VERSION "HNNBNNNYNNNNNNNNNNNNNNNNNNNNNNNNNNNNNNNNNN/4/%%%/4/'%**4NNN///"

NS_ :

BS_:

BU_: Aero_LB AFS_MLB Airbag_B8 BCM1_B8 Gateway_B8 Getriebe_AL551_651_B8 Getriebe_AL551_Q5_Hybrid Getriebe_SL_LB Lift_MLB_LB LWR_MLB Magnetic_Ride_LB Motor_MLB_AU48_AU416_Diesel Motor_MLB_B8_Q5_Otto Motor_MLB_Q5_Hybrid Niveau_LB Airbag_D4 BMS_Hybrid Daempfer_MLB EPB_MLB ESP Gateway Getriebe_AL551_951_D4_C7 Getriebe_AL551_Hybrid_D4_C7 Getriebe_DL382_MLB Getriebe_DL501_MLB Getriebe_VL381_MLB LEH_Hybrid LWS_D4 Motor2_MLB_D4_C7 Motor_MLB_AU64_AU57_Diesel Motor_MLB_BY_Otto Motor_MLB_C7_PHEV Motor_MLB_D4_C7_Hybrid Motor_MLB_D4_C7_Otto QSP SAK SAK2 SCR_MLB SCU

BO_ 782 Motor_05: 8 Motor_MLB_AU64_AU57_Diesel
 SG_ Motor_05_CHK : 0|8@1+ (1,0) [0|255] ""  Gateway,Getriebe_AL551_951_D4_C7,Getriebe_AL551_Hybrid_D4_C7,Getriebe_DL382_MLB,Getriebe_DL501_MLB,Getriebe_VL381_MLB
 SG_ Motor_05_BZ : 8|4@1+ (1,0) [0|15] ""  Gateway,Getriebe_AL551_951_D4_C7,Getriebe_AL551_Hybrid_D4_C7,Getriebe_DL382_MLB,Getriebe_DL501_MLB,Getriebe_VL381_MLB
 SG_ MO_EKlKomLeiRed : 12|2@1+ (1,0) [0|3] ""  Gateway
 SG_ MO_Freig_Reku : 14|2@1+ (1,0) [0|3] ""  Gateway
 SG_ MO_Klima_Eingr : 16|2@1+ (1,0) [0|3] ""  Gateway
 SG_ MO_Status_Normalbetrieb_02 : 18|1@1+ (1,0) [0|1] ""  Gateway
 SG_ MO_Schaltbeeinfl_Leistungsbegr : 19|1@1+ (1,0) [0|1] ""  Gateway,Getriebe_AL551_951_D4_C7,Getriebe_AL551_Hybrid_D4_C7,Getriebe_DL382_MLB,Getriebe_DL501_MLB
 SG_ MO_Schaltbeeinfl_Partikelfilter : 20|1@1+ (1,0) [0|1] ""  Gateway,Getriebe_AL551_951_D4_C7,Getriebe_AL551_Hybrid_D4_C7,Getriebe_DL382_MLB,Getriebe_DL501_MLB
 SG_ MO_Prio_MIN_Wunschdrehzahl : 21|1@1+ (1,0) [0|1] ""  Gateway,Getriebe_AL551_951_D4_C7,Getriebe_AL551_Hybrid_D4_C7,Getriebe_DL382_MLB,Getriebe_DL501_MLB,Getriebe_VL381_MLB
 SG_ MO_Freig_Anlass : 22|1@1+ (1,0) [0|1] ""  Gateway
 SG_ MO_Aussp_Anlass : 23|1@1+ (1,0) [0|1] ""  Gateway
 SG_ MO_MAX_Wunschdrehzahl : 24|9@1+ (25,0) [0|12750] "Unit_MinutInver"  Gateway,Getriebe_AL551_951_D4_C7,Getriebe_AL551_Hybrid_D4_C7,Getriebe_DL382_MLB,Getriebe_DL501_MLB,Getriebe_VL381_MLB
 SG_ MO_Prio_MAX_Wunschdrehzahl : 33|1@1+ (1,0) [0|1] ""  Gateway,Getriebe_AL551_951_D4_C7,Getriebe_AL551_Hybrid_D4_C7,Getriebe_DL382_MLB,Getriebe_DL501_MLB,Getriebe_VL381_MLB
 SG_ MO_Luftpfad_aktiv : 34|1@1+ (1,0) [0|1] ""  Gateway,Getriebe_AL551_951_D4_C7,Getriebe_AL551_Hybrid_D4_C7,Getriebe_DL382_MLB,Getriebe_DL501_MLB
 SG_ MO_v_Begrenz_Aktiv : 35|1@1+ (1,0) [0|1] ""  Gateway
 SG_ MO_v_Begrenz_Aktivierbar : 36|1@1+ (1,0) [0|1] ""  Gateway
 SG_ MO_Verbot_EKP : 37|1@1+ (1,0) [0|1] ""  Gateway
 SG_ MO_Anf_Pruefimpuls : 38|1@1+ (1,0) [0|1] ""  Gateway
 SG_ MO_Anf_KL75 : 39|1@1+ (1,0) [0|1] ""  Gateway
 SG_ MO_Charisma_FahrPr : 40|3@1+ (1,0) [0|7] ""  Gateway
 SG_ MO_Charisma_Status : 43|2@1+ (1,0) [0|3] ""  Gateway
 SG_ MO_Charisma_Umschaltung : 45|2@1+ (1,0) [0|3] ""  Gateway
 SG_ MO_Handshake_STH : 47|1@1+ (1,0) [0|1] ""  Gateway
 SG_ MO_MIN_Wunschdrehzahl : 48|8@1+ (25,0) [0|6350] "Unit_MinutInver"  Gateway,Getriebe_AL551_951_D4_C7,Getriebe_AL551_Hybrid_D4_C7,Getriebe_DL382_MLB,Getriebe_DL501_MLB,Getriebe_VL381_MLB
 SG_ MO_Drehzahlbeeinflussung : 56|8@1+ (0.39,0) [0|99.45] "Unit_PerCent"  Gateway,Getriebe_AL551_951_D4_C7,Getriebe_AL551_Hybrid_D4_C7,Getriebe_DL382_MLB,Getriebe_DL501_MLB,Getriebe_VL381_MLB

BO_ 1088 Motor_06: 8 Motor_MLB_AU64_AU57_Diesel
 SG_ MO_Kuehlerluefter_MUX M : 0|1@1+ (1,0) [0|1] ""  Gateway
 SG_ MO_Kuehlerluefter_1 m0 : 1|7@1+ (1,0) [0|100] "Unit_PerCent"  Gateway
 SG_ MO_Kuehlerluefter_2 m1 : 1|7@1+ (1,0) [0|100] "Unit_PerCent"  Gateway
 SG_ MO_HYB_Status_HV_Ladung : 8|3@1+ (1,0) [0|7] ""  Gateway
 SG_ MO_ITM_Warnung_Pumpe : 11|1@1+ (1,0) [0|1] ""  Gateway
 SG_ WIV_Anzeige_aktiv : 12|1@1+ (1,0) [0|1] ""  Gateway
 SG_ WIV_Oelmin_Warn : 13|1@1+ (1,0) [0|1] ""  Gateway
 SG_ WIV_Sensorfehler : 14|1@1+ (1,0) [0|1] ""  Gateway
 SG_ WIV_Schieflage : 15|1@1+ (1,0) [0|1] ""  Gateway
 SG_ WIV_Oelstand : 16|4@1+ (12.5,0) [0|100] "Unit_PerCent"  Gateway
 SG_ MO_Zustand_HWP : 20|2@1+ (1,0) [0|3] ""  Gateway
 SG_ MO_Kat_Warnung : 22|1@1+ (1,0) [0|1] ""  Gateway
 SG_ MO_Vorglueh_Lampe : 23|1@1+ (1,0) [0|1] ""  Gateway
 SG_ WIV_Oelsystem_aktiv : 24|1@1+ (1,0) [0|1] ""  Gateway
 SG_ WIV_nicht_betriebswarm : 25|1@1+ (1,0) [0|1] ""  Gateway
 SG_ WIV_Ueberfuell_Warn : 26|1@1+ (1,0) [0|1] ""  Gateway
 SG_ WIV_laufender_Motor : 27|1@1+ (1,0) [0|1] ""  Gateway
 SG_ MO_HYB_Text_1 : 28|1@1+ (1,0) [0|1] ""  Gateway
 SG_ MO_HYB_Text_2 : 29|1@1+ (1,0) [0|1] ""  Gateway
 SG_ MO_HYB_Text_3 : 30|1@1+ (1,0) [0|1] ""  Gateway
 SG_ MO_HYB_Text_4 : 31|1@1+ (1,0) [0|1] ""  Gateway
 SG_ MO_Text_Motorstart : 32|4@1+ (1,0) [0|15] ""  Gateway
 SG_ MO_HYB_Text_5 : 36|1@1+ (1,0) [0|1] ""  Gateway
 SG_ MO_HYB_Text_6 : 37|1@1+ (1,0) [0|1] ""  Gateway
 SG_ MO_HYB_Text_7 : 38|1@1+ (1,0) [0|1] ""  Gateway
 SG_ WIV_Oeldyn_avl : 39|1@1+ (1,0) [0|1] ""  Gateway
 SG_ MO_Text_MSG_Werkstatt : 40|1@1+ (1,0) [0|1] ""  Gateway
 SG_ MO_Text_Partikelfil_Reg : 41|1@1+ (1,0) [0|1] ""  Gateway
 SG_ MO_Text_Fehler_Kraftstoffsys : 42|1@1+ (1,0) [0|1] ""  Gateway
 SG_ WIV_Oelmenge : 43|5@1+ (125,0) [0|3875] "Unit_MilliLiter"  Gateway
 SG_ MO_Systemlampe : 48|1@1+ (1,0) [0|1] ""  Gateway
 SG_ MO_OBD2_Lampe : 49|1@1+ (1,0) [0|1] ""  Gateway
 SG_ MO_Heissleuchte : 50|1@1+ (1,0) [0|1] ""  Gateway
 SG_ MO_Partikel_Lampe : 51|1@1+ (1,0) [0|1] ""  Gateway
 SG_ MO_Winterfahrprog : 52|1@1+ (1,0) [0|1] ""  Gateway
 SG_ WIV_Oelstand_nicht_vorhanden : 53|1@1+ (1,0) [0|1] ""  Gateway
 SG_ WIV_nachfuellanzeige_ein : 54|1@1+ (1,0) [0|1] ""  Gateway
 SG_ WIV_Ueberfuell_deaktiv : 55|1@1+ (1,0) [0|1] ""  Gateway
 SG_ WIV_Unterfuell_Warn : 56|1@1+ (1,0) [0|1] ""  Gateway
 SG_ MO_Tankdeckel_Lampe : 57|1@1+ (1,0) [0|1] ""  Gateway
 SG_ MO_Text_Tankdeckelwarn : 58|1@1+ (1,0) [0|1] ""  Gateway
 SG_ WIV_Enable_Oeldr_Motor : 59|1@1+ (1,0) [0|1] ""  Gateway
 SG_ WIV_Oeldr_Warn_Motor : 60|1@1+ (1,0) [0|1] ""  Gateway
 SG_ MO_Avus_Motorschutz : 61|2@1+ (1,0) [0|3] ""  Gateway
 SG_ MO_HYB_Fahrbereitschaft : 63|1@1+ (1,0) [0|1] ""  Gateway

BO_ 1600 Motor_07: 8 Motor_MLB_AU64_AU57_Diesel
 SG_ MO_QBit_Ansaugluft_Temp : 0|1@1+ (1,0) [0|1] ""  Gateway,Getriebe_AL551_951_D4_C7,Getriebe_AL551_Hybrid_D4_C7,Getriebe_DL382_MLB,Getriebe_DL501_MLB,Getriebe_VL381_MLB
 SG_ MO_QBit_Oel_Temp : 1|1@1+ (1,0) [0|1] ""  Gateway,Getriebe_AL551_951_D4_C7,Getriebe_AL551_Hybrid_D4_C7
 SG_ MO_QBit_Kuehlmittel_Temp : 2|1@1+ (1,0) [0|1] ""  Gateway,Getriebe_AL551_951_D4_C7,Getriebe_AL551_Hybrid_D4_C7,Getriebe_DL382_MLB,Getriebe_DL501_MLB,Getriebe_VL381_MLB,LEH_Hybrid
 SG_ MO_HYB_Fehler_HV_Netz : 4|1@1+ (1,0) [0|1] ""  Gateway
 SG_ MO_aktives_Getriebeheizen : 5|1@1+ (1,0) [0|1] ""  Gateway,Getriebe_AL551_951_D4_C7,Getriebe_AL551_Hybrid_D4_C7,Getriebe_DL382_MLB,Getriebe_DL501_MLB,Getriebe_VL381_MLB
 SG_ MO_Absperrventil_oeffnen : 6|2@1+ (1,0) [0|3] ""  Gateway
 SG_ MO_Ansaugluft_Temp : 8|8@1+ (0.75,-48) [-48|141.75] "Unit_DegreCelsi"  Gateway,Getriebe_AL551_951_D4_C7,Getriebe_AL551_Hybrid_D4_C7,Getriebe_DL382_MLB,Getriebe_DL501_MLB,Getriebe_VL381_MLB
 SG_ MO_Oel_Temp : 16|8@1+ (1,-60) [-60|192] "Unit_DegreCelsi"  Gateway,Getriebe_AL551_951_D4_C7,Getriebe_AL551_Hybrid_D4_C7
 SG_ MO_Kuehlmittel_Temp : 24|8@1+ (0.75,-48) [-48|141.75] "Unit_DegreCelsi"  Gateway,Getriebe_AL551_951_D4_C7,Getriebe_AL551_Hybrid_D4_C7,Getriebe_DL382_MLB,Getriebe_DL501_MLB,Getriebe_VL381_MLB,LEH_Hybrid
 SG_ MO_Hoeheninfo : 32|8@1+ (0.00781,0) [0|1.98374] ""  Gateway,Getriebe_AL551_951_D4_C7,Getriebe_AL551_Hybrid_D4_C7,Getriebe_DL382_MLB,Getriebe_DL501_MLB,Getriebe_VL381_MLB
 SG_ MO_Kennfeldk : 40|1@1+ (1,0) [0|1] ""  Gateway
 SG_ MO_Versionsinfo : 41|6@1+ (1,0) [0|63] ""  Gateway
 SG_ MO_Getriebe_kuehlen : 47|1@1+ (1,0) [0|1] ""  Gateway,Getriebe_AL551_951_D4_C7,Getriebe_AL551_Hybrid_D4_C7,Getriebe_DL382_MLB,Getriebe_DL501_MLB,Getriebe_VL381_MLB
 SG_ MO_Mom_Traegheit_02 : 48|5@1+ (0.01,0) [0|0.31] "Unit_KiloGramMeterSquar"  Gateway,Getriebe_AL551_951_D4_C7,Getriebe_AL551_Hybrid_D4_C7,Getriebe_DL382_MLB,Getriebe_DL501_MLB,Getriebe_VL381_MLB
 SG_ MO_Heizungspumpenansteuerung : 53|4@1+ (10,0) [0|100] "Unit_PerCent"  Gateway
 SG_ MO_SpannungsAnf : 57|1@1+ (1,0) [0|1] ""  Gateway
 SG_ MO_Nachlaufzeit_Heizungspumpe : 58|6@1+ (15,0) [0|945] "Unit_Secon"  Gateway

BO_ 1607 Motor_09: 8 Motor_MLB_AU64_AU57_Diesel
 SG_ MO_ITM_Kuehlmittel_Temp : 0|8@1+ (0.75,-48) [-45.75|143.25] "Unit_DegreCelsi"  Gateway
 SG_ MO_E85_Sensor : 8|4@1+ (10,0) [0|100] "Unit_PerCent"  Gateway
 SG_ SCR_Anz_Motorstarts : 12|4@1+ (1,0) [0|13] ""  Gateway
 SG_ SCR_Reichweite : 16|15@1+ (1,0) [0|32766] "Unit_KiloMeter"  Gateway
 SG_ MO_Ethanol_Spuelhinweis : 31|1@1+ (1,0) [0|1] ""  Gateway
 SG_ SCR_Warnstufe_1 : 32|1@1+ (1,0) [0|1] ""  Gateway
 SG_ SCR_Warnstufe_2 : 33|1@1+ (1,0) [0|1] ""  Gateway
 SG_ SCR_Text : 34|3@1+ (1,0) [0|7] ""  Gateway
 SG_ SCR_Akustik : 37|2@1+ (1,0) [0|3] ""  Gateway
 SG_ SCR_verbaut : 39|1@1+ (1,0) [0|1] ""  Gateway
 SG_ MO_Kraftstofffilter_Wasser : 40|1@1+ (1,0) [0|1] ""  Gateway
 SG_ SCR_Systemfehler : 41|1@1+ (1,0) [0|1] ""  Gateway
 SG_ SCR_Inducement_Strategie : 42|2@1+ (1,0) [0|3] ""  Gateway
 SG_ MO_CO2_Faktor : 44|12@1+ (1,0) [1|4094] "Unit_GramPerLiter"  Gateway
 SG_ MO_MKB_MUX M : 56|2@1+ (1,0) [0|3] ""  Gateway
 SG_ MO_MKB_01 m0 : 59|5@1+ (1,0) [0|31] ""  Gateway
 SG_ MO_MKB_02 m1 : 59|5@1+ (1,0) [0|31] ""  Gateway
 SG_ MO_MKB_03 m2 : 59|5@1+ (1,0) [0|31] ""  Gateway
 SG_ MO_MKB_04 m3 : 59|5@1+ (1,0) [0|31] ""  Gateway

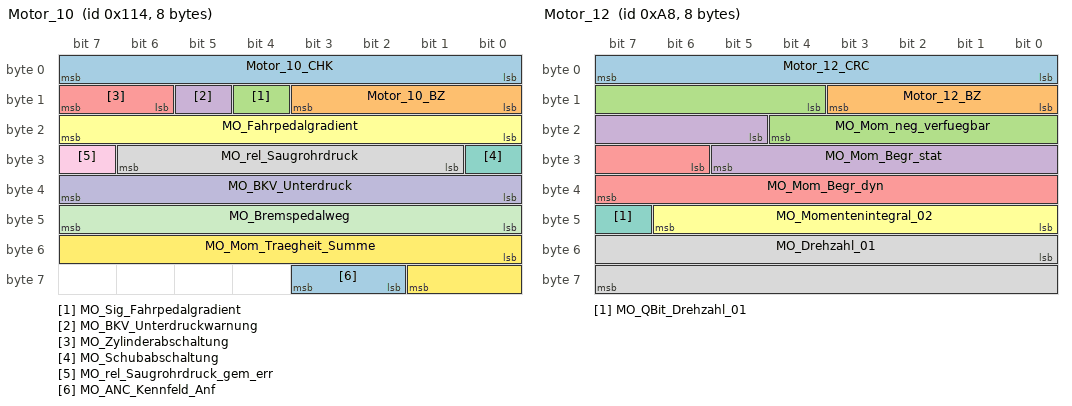
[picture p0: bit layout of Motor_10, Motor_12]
BO_ 276 Motor_10: 8 Motor_MLB_AU64_AU57_Diesel
 SG_ Motor_10_CHK : 0|8@1+ (1,0) [0|255] ""  Gateway,Getriebe_AL551_951_D4_C7,Getriebe_AL551_Hybrid_D4_C7,Getriebe_DL382_MLB,Getriebe_DL501_MLB
 SG_ Motor_10_BZ : 8|4@1+ (1,0) [0|15] ""  Gateway,Getriebe_AL551_951_D4_C7,Getriebe_AL551_Hybrid_D4_C7,Getriebe_DL382_MLB,Getriebe_DL501_MLB
 SG_ MO_Sig_Fahrpedalgradient : 12|1@1+ (1,0) [0|1] ""  Gateway
 SG_ MO_BKV_Unterdruckwarnung : 13|1@1+ (1,0) [0|1] ""  Gateway
 SG_ MO_Zylinderabschaltung : 14|2@1+ (1,0) [0|3] ""  Gateway,Getriebe_AL551_951_D4_C7,Getriebe_AL551_Hybrid_D4_C7,Getriebe_DL382_MLB,Getriebe_DL501_MLB
 SG_ MO_Fahrpedalgradient : 16|8@1+ (25,0) [0|6350] "Unit_PerCentPerSecon"  Gateway
 SG_ MO_Schubabschaltung : 24|1@1+ (1,0) [0|1] ""  Gateway
 SG_ MO_rel_Saugrohrdruck : 25|6@1+ (18,0) [0|1116] "Unit_MilliBar"  Gateway
 SG_ MO_rel_Saugrohrdruck_gem_err : 31|1@1+ (1,0) [0|1] ""  Gateway
 SG_ MO_BKV_Unterdruck : 32|8@1+ (4,0) [0|1012] "Unit_MilliBar"  Gateway
 SG_ MO_Bremspedalweg : 40|8@1+ (0.4,-0.4) [0|101.2] "Unit_PerCent"  Gateway,Getriebe_AL551_Hybrid_D4_C7
 SG_ MO_Mom_Traegheit_Summe : 48|10@1+ (1,-509) [-509|509] ""  Gateway,Getriebe_AL551_Hybrid_D4_C7
 SG_ MO_ANC_Kennfeld_Anf : 58|2@1+ (1,0) [0|3] ""  Gateway

BO_ 168 Motor_12: 8 Motor_MLB_C7_PHEV
 SG_ Motor_12_CRC : 0|8@1+ (1,0) [0|255] ""  Gateway
 SG_ Motor_12_BZ : 8|4@1+ (1,0) [0|15] ""  Gateway
 SG_ MO_Mom_neg_verfuegbar : 12|9@1+ (1,-509) [-509|0] ""  Gateway
 SG_ MO_Mom_Begr_stat : 21|9@1+ (1,0) [0|509] ""  Gateway
 SG_ MO_Mom_Begr_dyn : 30|10@1+ (1,-509) [-509|509] ""  Gateway
 SG_ MO_Momentenintegral_02 : 40|7@1+ (1,0) [0|100] "Unit_PerCent"  Gateway
 SG_ MO_QBit_Drehzahl_01 : 47|1@1+ (1,0) [0|1] ""  Gateway
 SG_ MO_Drehzahl_01 : 48|16@1+ (0.25,0) [0|16383] "Unit_MinutInver"  Gateway

BO_ 1648 Motor_18: 8 Motor_MLB_AU64_AU57_Diesel
 SG_ MO_max_Ladedruck : 0|6@1+ (0.1,0) [0|6.3] "Unit_Bar"  Gateway
 SG_ MO_ANC_Kennfeld_Anf : 6|2@1+ (1,0) [0|3] ""  Gateway
 SG_ MO_Bremslicht_Reku : 8|1@1+ (1,0) [0|1] ""  Gateway
 SG_ MO_StartStopp_PopUp : 9|2@1+ (1,0) [0|3] ""  Gateway
 SG_ MO_EPCL : 13|3@1+ (1,0) [0|7] ""  Gateway
 SG_ MO_Zylabsch_Texte_02 : 16|4@1+ (1,0) [0|15] ""  Gateway
 SG_ MO_Fahrzeugtyp : 20|3@1+ (1,0) [0|7] ""  Gateway
 SG_ MO_NMAX_Schaltanzeige : 23|9@1+ (25,0) [0|12775] "Unit_MinutInver"  Gateway
 SG_ MO_Abstellzeit : 32|8@1+ (8,0) [0|2024] "Unit_Minut"  Gateway,Getriebe_DL382_MLB,Getriebe_DL501_MLB
 SG_ MO_Abstellzeit_Status : 40|2@1+ (1,0) [0|3] ""  Gateway,Getriebe_DL382_MLB,Getriebe_DL501_MLB
 SG_ MO_Hybrid_StartStopp_LED : 43|2@1+ (1,0) [0|3] ""  Gateway
 SG_ MO_Fehler_Zylabsch : 45|2@1+ (1,0) [0|3] ""  Gateway
 SG_ MO_Anzahl_Abgesch_Zyl : 47|3@1+ (1,0) [0|7] ""  Gateway,Getriebe_AL551_951_D4_C7,Getriebe_AL551_Hybrid_D4_C7,Getriebe_DL382_MLB,Getriebe_DL501_MLB
 SG_ MO_Zylabsch_Texte : 50|2@1+ (1,0) [0|3] ""  Gateway
 SG_ MO_Ethanol_BS_Texte : 52|3@1+ (1,0) [0|7] ""  Gateway
 SG_ MO_Drehzahl_Warnung : 55|1@1+ (1,0) [0|1] ""  Gateway
 SG_ MO_obere_Drehzahlgrenze : 56|8@1+ (50,0) [50|12750] "Unit_MinutInver"  Gateway

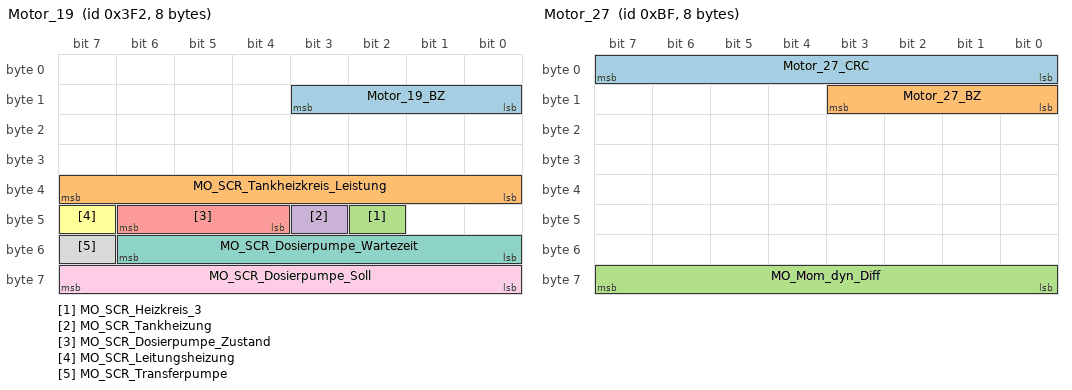
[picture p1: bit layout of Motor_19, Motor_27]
BO_ 1010 Motor_19: 8 Motor_MLB_AU64_AU57_Diesel
 SG_ Motor_19_BZ : 8|4@1+ (1,0) [0|15] ""  SCR_MLB
 SG_ MO_SCR_Tankheizkreis_Leistung : 32|8@1+ (1,0) [0|150] "Unit_Watt" Vector__XXX
 SG_ MO_SCR_Heizkreis_3 : 42|1@1+ (1,0) [0|1] ""  SCR_MLB
 SG_ MO_SCR_Tankheizung : 43|1@1+ (1,0) [0|1] ""  SCR_MLB
 SG_ MO_SCR_Dosierpumpe_Zustand : 44|3@1+ (1,0) [0|7] ""  SCR_MLB
 SG_ MO_SCR_Leitungsheizung : 47|1@1+ (1,0) [0|1] ""  SCR_MLB
 SG_ MO_SCR_Dosierpumpe_Wartezeit : 48|7@1+ (1,0) [0|120] "Unit_Secon"  SCR_MLB
 SG_ MO_SCR_Transferpumpe : 55|1@1+ (1,0) [0|1] ""  SCR_MLB
 SG_ MO_SCR_Dosierpumpe_Soll : 56|8@1+ (0.4,0) [0|100] "Unit_PerCent"  SCR_MLB

BO_ 815 Motor_23: 8 Motor_MLB_AU64_AU57_Diesel
 SG_ MO_Antriebsstrang_Warnung_HS : 46|2@1+ (1,0) [0|3] ""  Gateway
 SG_ MO_Anzeige_Verbrauch : 48|16@1+ (0.005,0) [0|327.675] "Unit_LiterPerHour"  Gateway

BO_ 1391 Motor_25: 8 Motor_MLB_AU64_AU57_Diesel
 SG_ MO_IstLeistung_EKAT : 41|7@1+ (20,0) [0|2500] "Unit_Watt"  Gateway
 SG_ MO_HYB_Drehzahl_VM : 48|16@1+ (0.25,0) [0|16256] "Unit_MinutInver"  Gateway,Getriebe_AL551_Hybrid_D4_C7

BO_ 191 Motor_27: 8 Motor_MLB_AU64_AU57_Diesel
 SG_ Motor_27_CRC : 0|8@1+ (1,0) [0|255] ""  Getriebe_AL551_951_D4_C7,Getriebe_AL551_Hybrid_D4_C7,Getriebe_DL382_MLB,Getriebe_DL501_MLB,Getriebe_VL381_MLB
 SG_ Motor_27_BZ : 8|4@1+ (1,0) [0|15] ""  Getriebe_AL551_951_D4_C7,Getriebe_AL551_Hybrid_D4_C7,Getriebe_DL382_MLB,Getriebe_DL501_MLB,Getriebe_VL381_MLB
 SG_ MO_Mom_dyn_Diff : 56|8@1+ (1,-25) [-25|229] "Unit_NewtoMeter"  Getriebe_AL551_951_D4_C7,Getriebe_AL551_Hybrid_D4_C7,Getriebe_DL382_MLB,Getriebe_DL501_MLB,Getriebe_VL381_MLB

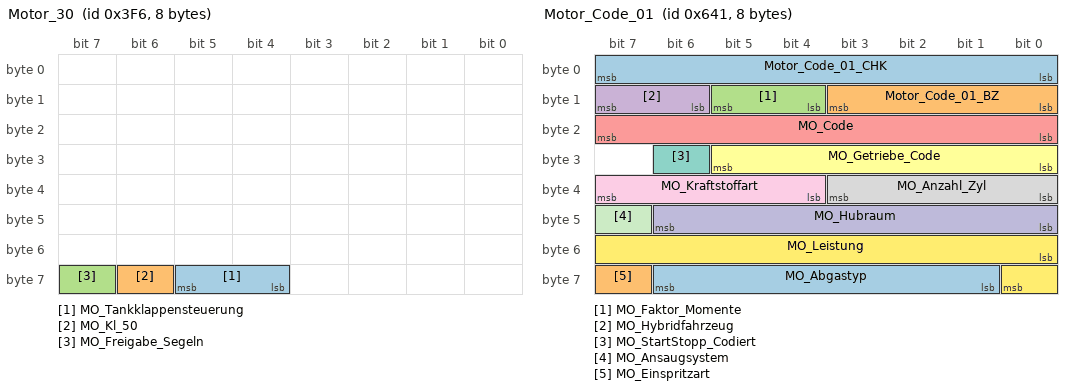
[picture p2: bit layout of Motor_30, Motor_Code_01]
BO_ 1014 Motor_30: 8 Motor_MLB_AU64_AU57_Diesel
 SG_ MO_Tankklappensteuerung : 60|2@1+ (1,0) [0|3] ""  Gateway
 SG_ MO_Kl_50 : 62|1@1+ (1,0) [0|1] ""  Getriebe_AL551_951_D4_C7
 SG_ MO_Freigabe_Segeln : 63|1@1+ (1,0) [0|1] ""  Getriebe_AL551_951_D4_C7,Getriebe_DL382_MLB,Getriebe_DL501_MLB

BO_ 1601 Motor_Code_01: 8 Motor_MLB_AU64_AU57_Diesel
 SG_ Motor_Code_01_CHK : 0|8@1+ (1,0) [0|255] ""  Gateway,Getriebe_AL551_951_D4_C7,Getriebe_AL551_Hybrid_D4_C7,Getriebe_DL382_MLB,Getriebe_DL501_MLB,Getriebe_VL381_MLB,LEH_Hybrid
 SG_ Motor_Code_01_BZ : 8|4@1+ (1,0) [0|15] ""  Gateway,Getriebe_AL551_951_D4_C7,Getriebe_AL551_Hybrid_D4_C7,Getriebe_DL382_MLB,Getriebe_DL501_MLB,Getriebe_VL381_MLB,LEH_Hybrid
 SG_ MO_Faktor_Momente : 12|2@1+ (1,0) [0|3] ""  EPB_MLB,Gateway,Getriebe_AL551_951_D4_C7,Getriebe_AL551_Hybrid_D4_C7,Getriebe_DL382_MLB,Getriebe_DL501_MLB,Getriebe_VL381_MLB
 SG_ MO_Hybridfahrzeug : 14|2@1+ (1,0) [0|3] ""  EPB_MLB,Gateway
 SG_ MO_Code : 16|8@1+ (1,0) [0|255] ""  EPB_MLB,Gateway,Getriebe_AL551_951_D4_C7,Getriebe_AL551_Hybrid_D4_C7,Getriebe_DL382_MLB,Getriebe_DL501_MLB,Getriebe_VL381_MLB,SAK,SAK2
 SG_ MO_Getriebe_Code : 24|6@1+ (1,0) [0|63] ""  EPB_MLB,Gateway,Getriebe_AL551_951_D4_C7,Getriebe_AL551_Hybrid_D4_C7,Getriebe_DL382_MLB,Getriebe_DL501_MLB,Getriebe_VL381_MLB
 SG_ MO_StartStopp_Codiert : 30|1@1+ (1,0) [0|1] ""  Gateway
 SG_ MO_Anzahl_Zyl : 32|4@1+ (1,0) [0|15] ""  Gateway
 SG_ MO_Kraftstoffart : 36|4@1+ (1,0) [0|15] ""  EPB_MLB,Gateway
 SG_ MO_Hubraum : 40|7@1+ (0.1,0) [0|12.7] "Unit_Liter"  Gateway
 SG_ MO_Ansaugsystem : 47|1@1+ (1,0) [0|1] ""  EPB_MLB,Gateway
 SG_ MO_Leistung : 48|9@1+ (1,0) [0|511] "Unit_KiloWatt"  Gateway
 SG_ MO_Abgastyp : 57|6@1+ (1,0) [0|63] ""  BMS_Hybrid,Gateway,Getriebe_AL551_951_D4_C7,Getriebe_AL551_Hybrid_D4_C7,LEH_Hybrid
 SG_ MO_Einspritzart : 63|1@1+ (1,0) [0|1] ""  Gateway

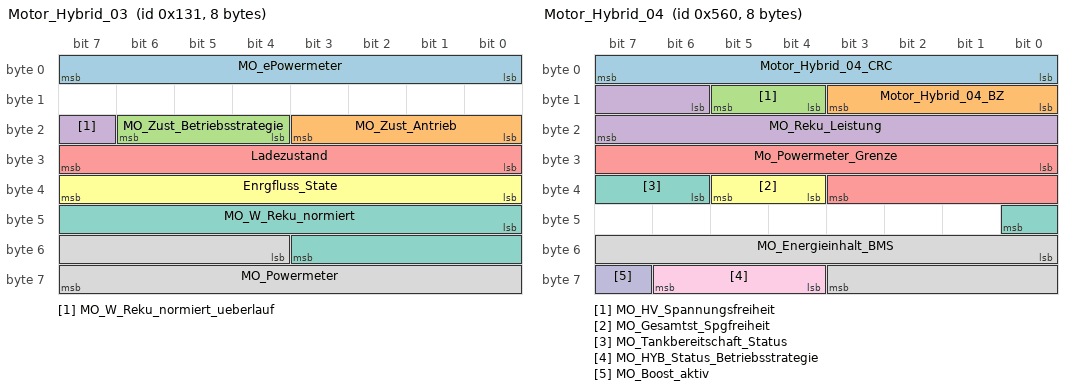
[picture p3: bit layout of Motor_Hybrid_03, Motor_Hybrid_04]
BO_ 305 Motor_Hybrid_03: 8 Motor_MLB_C7_PHEV
 SG_ MO_ePowermeter : 0|8@1+ (0.4,-0.4) [0|100.8] "Unit_PerCent"  Gateway
 SG_ MO_Zust_Antrieb : 16|4@1+ (1,0) [0|15] ""  Gateway
 SG_ MO_Zust_Betriebsstrategie : 20|3@1+ (1,0) [0|7] ""  Gateway
 SG_ MO_W_Reku_normiert_ueberlauf : 23|1@1+ (1,0) [0|1] ""  Gateway
 SG_ Ladezustand : 24|8@1+ (1,0) [0|100] "Unit_PerCent"  Gateway
 SG_ Enrgfluss_State : 32|8@1+ (1,0) [0|255] ""  Gateway
 SG_ MO_W_Reku_normiert : 40|12@1+ (10,0) [0|40950] "Unit_WattSecond"  Gateway
 SG_ MO_Powermeter : 52|12@1+ (1,0) [0|4092] ""  Gateway

BO_ 1376 Motor_Hybrid_04: 8 Motor_MLB_C7_PHEV
 SG_ Motor_Hybrid_04_CRC : 0|8@1+ (1,0) [0|255] ""  Gateway
 SG_ Motor_Hybrid_04_BZ : 8|4@1+ (1,0) [0|15] ""  Gateway
 SG_ MO_HV_Spannungsfreiheit : 12|2@1+ (1,0) [0|3] ""  Gateway
 SG_ MO_Reku_Leistung : 14|10@1+ (10,0) [0|10230] "Unit_Watt"  Gateway
 SG_ Mo_Powermeter_Grenze : 24|12@1+ (1,0) [0|4092] ""  Gateway
 SG_ MO_Gesamtst_Spgfreiheit : 36|2@1+ (1,0) [0|3] ""  Gateway
 SG_ MO_Tankbereitschaft_Status : 38|3@1+ (1,0) [0|7] ""  Gateway
 SG_ MO_Energieinhalt_BMS : 48|12@1+ (25,0) [0|102325] "Unit_WattHour"  Gateway
 SG_ MO_HYB_Status_Betriebsstrategie : 60|3@1+ (1,0) [0|7] ""  Gateway
 SG_ MO_Boost_aktiv : 63|1@1+ (1,0) [0|1] ""  Gateway

BO_ 969 MotorSlave_01: 1 Motor2_MLB_D4_C7
 SG_ MOS_KD_Fehler : 0|1@1+ (1,0) [0|1] ""  Gateway

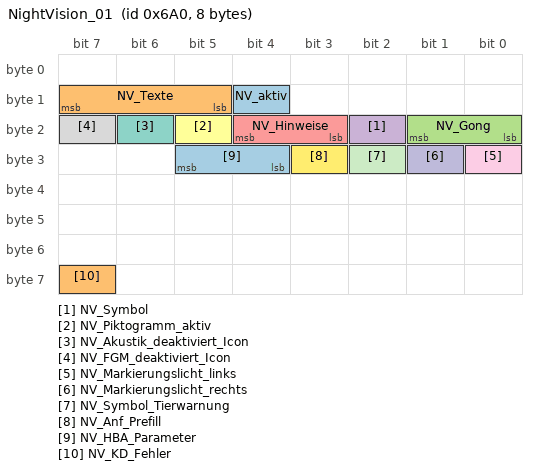
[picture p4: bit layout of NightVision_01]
BO_ 1696 NightVision_01: 8 Gateway
 SG_ NV_aktiv : 12|1@1+ (1,0) [0|1] ""  Airbag_D4
 SG_ NV_Texte : 13|3@1+ (1,0) [0|7] "" Vector__XXX
 SG_ NV_Gong : 16|2@1+ (1,0) [0|3] ""  Airbag_D4
 SG_ NV_Symbol : 18|1@1+ (1,0) [0|1] ""  Airbag_D4
 SG_ NV_Hinweise : 19|2@1+ (1,0) [0|3] "" Vector__XXX
 SG_ NV_Piktogramm_aktiv : 21|1@1+ (1,0) [0|1] "" Vector__XXX
 SG_ NV_Akustik_deaktiviert_Icon : 22|1@1+ (1,0) [0|1] "" Vector__XXX
 SG_ NV_FGM_deaktiviert_Icon : 23|1@1+ (1,0) [0|1] "" Vector__XXX
 SG_ NV_Markierungslicht_links : 24|1@1+ (1,0) [0|1] "" Vector__XXX
 SG_ NV_Markierungslicht_rechts : 25|1@1+ (1,0) [0|1] "" Vector__XXX
 SG_ NV_Symbol_Tierwarnung : 26|1@1+ (1,0) [0|1] "" Vector__XXX
 SG_ NV_Anf_Prefill : 27|1@1+ (1,0) [0|1] "" Vector__XXX
 SG_ NV_HBA_Parameter : 28|2@1+ (1,0) [0|3] "" Vector__XXX
 SG_ NV_KD_Fehler : 63|1@1+ (1,0) [0|1] "" Vector__XXX

BO_ 1742 NMH_BMS: 7 BMS_Hybrid
 SG_ NMH_BMS_Start_1 : 0|1@1+ (1,0) [0|1] ""  BMS_Hybrid,EPB_MLB,Gateway,Getriebe_AL551_951_D4_C7,Getriebe_AL551_Hybrid_D4_C7,Getriebe_DL382_MLB,Getriebe_DL501_MLB,Getriebe_VL381_MLB,LEH_Hybrid,Motor2_MLB_D4_C7,Motor_MLB_AU64_AU57_Diesel,Motor_MLB_BY_Otto,Motor_MLB_C7_PHEV,Motor_MLB_D4_C7_Hybrid,Motor_MLB_D4_C7_Otto,SCR_MLB
 SG_ NMH_BMS_Start_2 : 1|1@1+ (1,0) [0|1] "" Vector__XXX
 SG_ NMH_BMS_Normal_Mode_1 : 2|1@1+ (1,0) [0|1] "" Vector__XXX
 SG_ NMH_BMS_Normal_Mode_2 : 3|1@1+ (1,0) [0|1] "" Vector__XXX
 SG_ NMH_BMS_Car_WakeUp : 6|1@1+ (1,0) [0|1] "" Vector__XXX
 SG_ NMH_BMS_Per_WakeUp : 8|5@1+ (1,0) [0|31] "" Vector__XXX
 SG_ NMH_BMS_Fkt_WakeUp : 13|3@1+ (1,0) [0|7] "" Vector__XXX
 SG_ NMH_BMS_Klemme_15 : 16|1@1+ (1,0) [0|1] "" Vector__XXX
 SG_ NMH_BMS_Diagnose : 17|1@1+ (1,0) [0|1] "" Vector__XXX
 SG_ NMH_BMS_MindestAktivZeit : 18|1@1+ (1,0) [0|1] "" Vector__XXX
 SG_ NMH_BMS_NL_Daten_EEPROM : 24|1@1+ (1,0) [0|1] "" Vector__XXX
 SG_ NMH_BMS_NL_Luefter : 25|1@1+ (1,0) [0|1] "" Vector__XXX
 SG_ NMH_BMS_Signalfehler : 32|1@1+ (1,0) [0|1] "" Vector__XXX
 SG_ NMH_BMS_TimeOut_Fehler : 33|1@1+ (1,0) [0|1] "" Vector__XXX
 SG_ NMH_BMS_CAN_Diag_deaktiv : 34|1@1+ (1,0) [0|1] "" Vector__XXX
 SG_ NMH_BMS_KompSchutz : 35|1@1+ (1,0) [0|1] "" Vector__XXX
 SG_ NMH_BMS_Mute_Mode : 36|1@1+ (1,0) [0|1] "" Vector__XXX
 SG_ NMH_BMS_Transport_Mode : 37|1@1+ (1,0) [0|1] "" Vector__XXX
 SG_ NMH_BMS_Abschaltstufe_aktiv : 38|1@1+ (1,0) [0|1] "" Vector__XXX
 SG_ NMH_BMS_Busfehler : 39|1@1+ (1,0) [0|1] "" Vector__XXX
 SG_ NMH_BMS_Lokalaktiv : 48|1@1+ (1,0) [0|1] "" Vector__XXX
 SG_ NMH_BMS_Subsystemaktiv : 49|1@1+ (1,0) [0|1] "" Vector__XXX

BO_ 1743 NMH_EM: 7 LEH_Hybrid
 SG_ NMH_EM_Start_1 : 0|1@1+ (1,0) [0|1] ""  BMS_Hybrid,EPB_MLB,Gateway,Getriebe_AL551_951_D4_C7,Getriebe_AL551_Hybrid_D4_C7,Getriebe_DL382_MLB,Getriebe_DL501_MLB,Getriebe_VL381_MLB,LEH_Hybrid,Motor2_MLB_D4_C7,Motor_MLB_AU64_AU57_Diesel,Motor_MLB_BY_Otto,Motor_MLB_C7_PHEV,Motor_MLB_D4_C7_Hybrid,Motor_MLB_D4_C7_Otto,SCR_MLB
 SG_ NMH_EM_Start_2 : 1|1@1+ (1,0) [0|1] "" Vector__XXX
 SG_ NMH_EM_Normal_Mode_1 : 2|1@1+ (1,0) [0|1] "" Vector__XXX
 SG_ NMH_EM_Normal_Mode_2 : 3|1@1+ (1,0) [0|1] "" Vector__XXX
 SG_ NMH_EM_Car_WakeUp : 6|1@1+ (1,0) [0|1] "" Vector__XXX
 SG_ NMH_EM_Per_WakeUp : 8|5@1+ (1,0) [0|31] "" Vector__XXX
 SG_ NMH_EM_Fkt_WakeUp : 13|3@1+ (1,0) [0|7] "" Vector__XXX
 SG_ NMH_EM_Klemme_15 : 16|1@1+ (1,0) [0|1] "" Vector__XXX
 SG_ NMH_EM_Diagnose : 17|1@1+ (1,0) [0|1] "" Vector__XXX
 SG_ NMH_EM_MindestAktivZeit : 18|1@1+ (1,0) [0|1] "" Vector__XXX
 SG_ NMH_EM_keine_HV_Entl : 19|1@1+ (1,0) [0|1] "" Vector__XXX
 SG_ NMH_EM_NL_Datem_EEPROM : 24|1@1+ (1,0) [0|1] "" Vector__XXX
 SG_ NMH_EM_Signalfehler : 32|1@1+ (1,0) [0|1] "" Vector__XXX
 SG_ NMH_EM_TimeOut_Fehler : 33|1@1+ (1,0) [0|1] "" Vector__XXX
 SG_ NMH_EM_CAN_Diag_deaktiv : 34|1@1+ (1,0) [0|1] "" Vector__XXX
 SG_ NMH_EM_KompSchutz : 35|1@1+ (1,0) [0|1] "" Vector__XXX
 SG_ NMH_EM_Mute_Mode : 36|1@1+ (1,0) [0|1] "" Vector__XXX
 SG_ NMH_EM_Transport_Mode : 37|1@1+ (1,0) [0|1] "" Vector__XXX
 SG_ NMH_EM_Abschaltstufe_aktiv : 38|1@1+ (1,0) [0|1] "" Vector__XXX
 SG_ NMH_EM_Busfehler : 39|1@1+ (1,0) [0|1] "" Vector__XXX
 SG_ NMH_EM_Lokalaktiv : 48|1@1+ (1,0) [0|1] "" Vector__XXX
 SG_ NMH_EM_Subsystemaktiv : 49|1@1+ (1,0) [0|1] "" Vector__XXX

BO_ 1753 NMH_EPB: 7 EPB_MLB
 SG_ NMH_EPB_Start_1 : 0|1@1+ (1,0) [0|1] ""  BMS_Hybrid,EPB_MLB,Gateway,Getriebe_AL551_951_D4_C7,Getriebe_AL551_Hybrid_D4_C7,Getriebe_DL382_MLB,Getriebe_DL501_MLB,Getriebe_VL381_MLB,LEH_Hybrid,Motor2_MLB_D4_C7,Motor_MLB_AU64_AU57_Diesel,Motor_MLB_BY_Otto,Motor_MLB_C7_PHEV,Motor_MLB_D4_C7_Hybrid,Motor_MLB_D4_C7_Otto,SCR_MLB
 SG_ NMH_EPB_Start_2 : 1|1@1+ (1,0) [0|1] "" Vector__XXX
 SG_ NMH_EPB_Normal_Mode_1 : 2|1@1+ (1,0) [0|1] "" Vector__XXX
 SG_ NMH_EPB_Normal_Mode_2 : 3|1@1+ (1,0) [0|1] "" Vector__XXX
 SG_ NMH_EPB_Car_WakeUp : 6|1@1+ (1,0) [0|1] "" Vector__XXX
 SG_ NMH_EPB_Per_WakeUp : 8|5@1+ (1,0) [0|31] "" Vector__XXX
 SG_ NMH_EPB_Fkt_WakeUp : 13|3@1+ (1,0) [0|7] "" Vector__XXX
 SG_ NMH_EPB_NM_aktiv_Klemme_15 : 16|1@1+ (1,0) [0|1] "" Vector__XXX
 SG_ NMH_EPB_NM_aktiv_Diagnose : 17|1@1+ (1,0) [0|1] "" Vector__XXX
 SG_ NMH_EPB_NM_aktiv_Start : 18|1@1+ (1,0) [0|1] "" Vector__XXX
 SG_ NMH_EPB_NM_aktiv_Schalter : 19|1@1+ (1,0) [0|1] "" Vector__XXX
 SG_ NMH_EPB_NM_aktiv_Bedarf_Anzeige : 20|1@1+ (1,0) [0|1] "" Vector__XXX
 SG_ NMH_EPB_NM_aktiv_v_groesser_Null : 21|1@1+ (1,0) [0|1] "" Vector__XXX
 SG_ NMH_EPB_AutoAdjust : 22|1@1+ (1,0) [0|1] "" Vector__XXX
 SG_ NMH_EPB_kein_NL : 24|1@1+ (1,0) [0|1] "" Vector__XXX
 SG_ NMH_EPB_NL_Temp_Modell : 25|1@1+ (1,0) [0|1] "" Vector__XXX
 SG_ NMH_EPB_NL_Min : 26|1@1+ (1,0) [0|1] "" Vector__XXX
 SG_ NM_EPB_Signalfehler : 32|1@1+ (1,0) [0|1] "" Vector__XXX
 SG_ NMH_EPB_TimeOut_Fehler : 33|1@1+ (1,0) [0|1] "" Vector__XXX
 SG_ NMH_EPB_CAN_Diag_deaktiv : 34|1@1+ (1,0) [0|1] "" Vector__XXX
 SG_ NMH_EPB_KompSchutz : 35|1@1+ (1,0) [0|1] "" Vector__XXX
 SG_ NMH_EPB_Mute_Mode : 36|1@1+ (1,0) [0|1] "" Vector__XXX
 SG_ NMH_EPB_Transport_Mode : 37|1@1+ (1,0) [0|1] "" Vector__XXX
 SG_ NMH_EPB_Abschaltstufe_aktiv : 38|1@1+ (1,0) [0|1] "" Vector__XXX
 SG_ NMH_EPB_Eindraht_Fehler : 39|1@1+ (1,0) [0|1] "" Vector__XXX
 SG_ NMH_EPB_Lokalaktiv : 48|1@1+ (1,0) [0|1] "" Vector__XXX
 SG_ NMH_EPB_Subsystemaktiv : 49|1@1+ (1,0) [0|1] "" Vector__XXX

BO_ 1728 NMH_Gateway: 7 Gateway
 SG_ NMH_GW_Start_1 : 0|1@1+ (1,0) [0|1] ""  BMS_Hybrid,EPB_MLB,Gateway,Getriebe_AL551_951_D4_C7,Getriebe_AL551_Hybrid_D4_C7,Getriebe_DL382_MLB,Getriebe_DL501_MLB,Getriebe_VL381_MLB,LEH_Hybrid,Motor2_MLB_D4_C7,Motor_MLB_AU64_AU57_Diesel,Motor_MLB_BY_Otto,Motor_MLB_C7_PHEV,Motor_MLB_D4_C7_Hybrid,Motor_MLB_D4_C7_Otto,SCR_MLB
 SG_ NMH_GW_Start_2 : 1|1@1+ (1,0) [0|1] ""  BMS_Hybrid,EPB_MLB,Gateway,Getriebe_AL551_951_D4_C7,Getriebe_AL551_Hybrid_D4_C7,Getriebe_DL382_MLB,Getriebe_DL501_MLB,Getriebe_VL381_MLB,LEH_Hybrid,Motor2_MLB_D4_C7,Motor_MLB_AU64_AU57_Diesel,Motor_MLB_BY_Otto,Motor_MLB_C7_PHEV,Motor_MLB_D4_C7_Hybrid,Motor_MLB_D4_C7_Otto,SCR_MLB
 SG_ NMH_GW_Normal_Mode_1 : 2|1@1+ (1,0) [0|1] ""  BMS_Hybrid,EPB_MLB,Gateway,Getriebe_AL551_951_D4_C7,Getriebe_AL551_Hybrid_D4_C7,Getriebe_DL382_MLB,Getriebe_DL501_MLB,Getriebe_VL381_MLB,LEH_Hybrid,Motor2_MLB_D4_C7,Motor_MLB_AU64_AU57_Diesel,Motor_MLB_BY_Otto,Motor_MLB_C7_PHEV,Motor_MLB_D4_C7_Hybrid,Motor_MLB_D4_C7_Otto,SCR_MLB
 SG_ NMH_GW_Normal_Mode_2 : 3|1@1+ (1,0) [0|1] ""  BMS_Hybrid,EPB_MLB,Gateway,Getriebe_AL551_951_D4_C7,Getriebe_AL551_Hybrid_D4_C7,Getriebe_DL382_MLB,Getriebe_DL501_MLB,Getriebe_VL381_MLB,LEH_Hybrid,Motor2_MLB_D4_C7,Motor_MLB_AU64_AU57_Diesel,Motor_MLB_BY_Otto,Motor_MLB_C7_PHEV,Motor_MLB_D4_C7_Hybrid,Motor_MLB_D4_C7_Otto,SCR_MLB
 SG_ NMH_GW_Car_WakeUp : 6|1@1+ (1,0) [0|1] "" Vector__XXX
 SG_ NMH_GW_Per_WakeUp : 8|5@1+ (1,0) [0|31] "" Vector__XXX
 SG_ NMH_GW_Fkt_WakeUp : 13|3@1+ (1,0) [0|7] "" Vector__XXX
 SG_ NMH_GW_NM_aktiv_Klemme_15 : 16|1@1+ (1,0) [0|1] "" Vector__XXX
 SG_ NMH_GW_NM_aktiv_Diagnose : 17|1@1+ (1,0) [0|1] "" Vector__XXX
 SG_ NMH_GW_NM_aktiv_Start : 18|1@1+ (1,0) [0|1] "" Vector__XXX
 SG_ NMH_GW_NM_aktiv_BDM : 19|1@1+ (1,0) [0|1] "" Vector__XXX
 SG_ NMH_GW_NM_aktiv_Warnblinken : 20|1@1+ (1,0) [0|1] "" Vector__XXX
 SG_ NMH_GW_NM_aktiv_ESP : 21|1@1+ (1,0) [0|1] "" Vector__XXX
 SG_ NMH_GW_NM_aktiv_EMP : 22|1@1+ (1,0) [0|1] "" Vector__XXX
 SG_ NMH_GW_Abschaltstufe_3 : 24|1@1+ (1,0) [0|1] "" Vector__XXX
 SG_ NMH_GW_SG_Fehlerdauer : 25|1@1+ (1,0) [0|1] "" Vector__XXX
 SG_ NMH_GW_STH_Wakeup : 26|1@1+ (1,0) [0|1] "" Vector__XXX
 SG_ NMH_GW_NL_Diagnose : 27|1@1+ (1,0) [0|1] "" Vector__XXX
 SG_ NM_GW_Signalfehler : 32|1@1+ (1,0) [0|1] "" Vector__XXX
 SG_ NMH_GW_TimeOut_Fehler : 33|1@1+ (1,0) [0|1] "" Vector__XXX
 SG_ NMH_GW_CAN_Diag_deaktiv : 34|1@1+ (1,0) [0|1] "" Vector__XXX
 SG_ NMH_GW_KompSchutz : 35|1@1+ (1,0) [0|1] "" Vector__XXX
 SG_ NMH_GW_Mute_Mode : 36|1@1+ (1,0) [0|1] "" Vector__XXX
 SG_ NMH_GW_Transport_Mode : 37|1@1+ (1,0) [0|1] "" Vector__XXX
 SG_ NMH_GW_Abschaltstufe_aktiv : 38|1@1+ (1,0) [0|1] "" Vector__XXX
 SG_ NMH_GW_Eindraht_Fehler : 39|1@1+ (1,0) [0|1] "" Vector__XXX
 SG_ NMH_GW_ACAN : 40|1@1+ (1,0) [0|1] "" Vector__XXX
 SG_ NMH_GW_KombiCAN : 41|1@1+ (1,0) [0|1] "" Vector__XXX
 SG_ NMH_GW_KomfortCAN : 42|1@1+ (1,0) [0|1] "" Vector__XXX
 SG_ NMH_GW_Infotainment : 43|1@1+ (1,0) [0|1] "" Vector__XXX
 SG_ NMH_GW_Fahrwerk : 44|1@1+ (1,0) [0|1] "" Vector__XXX
 SG_ NMH_GW_WakeUp_CAN_Bus : 45|3@1+ (1,0) [0|7] "" Vector__XXX

BO_ 1730 NMH_Getriebe: 7 Getriebe_AL551_951_D4_C7
 SG_ NMH_GE_Start_1 : 0|1@1+ (1,0) [0|1] ""  BMS_Hybrid,EPB_MLB,Gateway,Getriebe_AL551_951_D4_C7,Getriebe_AL551_Hybrid_D4_C7,Getriebe_DL382_MLB,Getriebe_DL501_MLB,Getriebe_VL381_MLB,LEH_Hybrid,Motor2_MLB_D4_C7,Motor_MLB_AU64_AU57_Diesel,Motor_MLB_BY_Otto,Motor_MLB_C7_PHEV,Motor_MLB_D4_C7_Hybrid,Motor_MLB_D4_C7_Otto,SCR_MLB
 SG_ NMH_GE_Start_2 : 1|1@1+ (1,0) [0|1] "" Vector__XXX
 SG_ NMH_GE_Normal_Mode_1 : 2|1@1+ (1,0) [0|1] "" Vector__XXX
 SG_ NMH_GE_Normal_Mode_2 : 3|1@1+ (1,0) [0|1] "" Vector__XXX
 SG_ NMH_GE_Car_WakeUp : 6|1@1+ (1,0) [0|1] "" Vector__XXX
 SG_ NMH_GE_Per_WakeUp : 8|5@1+ (1,0) [0|31] "" Vector__XXX
 SG_ NMH_GE_Fkt_WakeUp : 13|3@1+ (1,0) [0|7] "" Vector__XXX
 SG_ NMH_GE_NM_aktiv_Klemme_15 : 16|1@1+ (1,0) [0|1] "" Vector__XXX
 SG_ NMH_GE_NM_aktiv_Diagnose : 17|1@1+ (1,0) [0|1] "" Vector__XXX
 SG_ NMH_GE_NM_aktiv_Start : 18|1@1+ (1,0) [0|1] "" Vector__XXX
 SG_ NMH_GE_N_Haltephase : 19|1@1+ (1,0) [0|1] "" Vector__XXX
 SG_ NMH_GE_Positionsanzeige : 20|1@1+ (1,0) [0|1] "" Vector__XXX
 SG_ NMH_GE_kein_NL : 24|1@1+ (1,0) [0|1] "" Vector__XXX
 SG_ NMH_GE_NL_Daten_EEPROM : 25|1@1+ (1,0) [0|1] "" Vector__XXX
 SG_ NMH_GE_NL_Drucksens : 26|1@1+ (1,0) [0|1] "" Vector__XXX
 SG_ NMH_GE_NL_Abtrieb : 27|1@1+ (1,0) [0|1] "" Vector__XXX
 SG_ NMH_GE_NL_Waehlhebel : 28|1@1+ (1,0) [0|1] "" Vector__XXX
 SG_ NMH_GE_NL_Wegfahrsperre : 29|1@1+ (1,0) [0|1] "" Vector__XXX
 SG_ NM_GE_Signalfehler : 32|1@1+ (1,0) [0|1] "" Vector__XXX
 SG_ NMH_GE_TimeOut_Fehler : 33|1@1+ (1,0) [0|1] "" Vector__XXX
 SG_ NMH_GE_CAN_Diag_deaktiv : 34|1@1+ (1,0) [0|1] "" Vector__XXX
 SG_ NMH_GE_KompSchutz : 35|1@1+ (1,0) [0|1] "" Vector__XXX
 SG_ NMH_GE_Mute_Mode : 36|1@1+ (1,0) [0|1] "" Vector__XXX
 SG_ NMH_GE_Transport_Mode : 37|1@1+ (1,0) [0|1] "" Vector__XXX
 SG_ NMH_GE_Abschaltstufe_aktiv : 38|1@1+ (1,0) [0|1] "" Vector__XXX
 SG_ NMH_GE_Eindraht_Fehler : 39|1@1+ (1,0) [0|1] "" Vector__XXX
 SG_ NMH_GE_Lokalaktiv : 48|1@1+ (1,0) [0|1] "" Vector__XXX
 SG_ NMH_GE_Subsystemaktiv : 49|1@1+ (1,0) [0|1] "" Vector__XXX
 SG_ NMH_GSG_Subbusaktiv : 50|1@1+ (1,0) [0|1] "" Vector__XXX

BO_ 1729 NMH_Motor: 7 Motor_MLB_AU64_AU57_Diesel
 SG_ NMH_MO_Start_1 : 0|1@1+ (1,0) [0|1] ""  BMS_Hybrid,EPB_MLB,Gateway,Getriebe_AL551_951_D4_C7,Getriebe_AL551_Hybrid_D4_C7,Getriebe_DL382_MLB,Getriebe_DL501_MLB,Getriebe_VL381_MLB,LEH_Hybrid,Motor2_MLB_D4_C7,Motor_MLB_AU64_AU57_Diesel,Motor_MLB_BY_Otto,Motor_MLB_C7_PHEV,Motor_MLB_D4_C7_Hybrid,Motor_MLB_D4_C7_Otto,SCR_MLB
 SG_ NMH_MO_Start_2 : 1|1@1+ (1,0) [0|1] "" Vector__XXX
 SG_ NMH_MO_Normal_Mode_1 : 2|1@1+ (1,0) [0|1] "" Vector__XXX
 SG_ NMH_MO_Normal_Mode_2 : 3|1@1+ (1,0) [0|1] "" Vector__XXX
 SG_ NMH_MO_Car_WakeUp : 6|1@1+ (1,0) [0|1] "" Vector__XXX
 SG_ NMH_MO_Per_WakeUp : 8|5@1+ (1,0) [0|31] "" Vector__XXX
 SG_ NMH_MO_Fkt_WakeUp : 13|3@1+ (1,0) [0|7] "" Vector__XXX
 SG_ NMH_MO_NM_aktiv_Klemme_15 : 16|1@1+ (1,0) [0|1] "" Vector__XXX
 SG_ NMH_MO_NM_aktiv_Diagnose : 17|1@1+ (1,0) [0|1] "" Vector__XXX
 SG_ NMH_MO_NM_aktiv_Start : 18|1@1+ (1,0) [0|1] "" Vector__XXX
 SG_ NMH_MO_NM_aktiv_EKP_Vorlauf : 19|1@1+ (1,0) [0|1] "" Vector__XXX
 SG_ NMH_MO_NM_aktiv_STH_Betrieb : 20|1@1+ (1,0) [0|1] "" Vector__XXX
 SG_ NMH_MO_NM_aktiv_HV : 21|1@1+ (1,0) [0|1] "" Vector__XXX
 SG_ NMH_MO_kein_NL : 24|1@1+ (1,0) [0|1] "" Vector__XXX
 SG_ NMH_MO_NL_Kuehlerluefter : 25|1@1+ (1,0) [0|1] "" Vector__XXX
 SG_ NMH_MO_NL_Diagnose : 26|1@1+ (1,0) [0|1] "" Vector__XXX
 SG_ NMH_MO_NL_WFS : 27|1@1+ (1,0) [0|1] "" Vector__XXX
 SG_ NMH_MO_NL_EEPROM : 28|1@1+ (1,0) [0|1] "" Vector__XXX
 SG_ NMH_MO_NL_Sonstige : 29|1@1+ (1,0) [0|1] "" Vector__XXX
 SG_ NM_MO_01_NM_aktiv_Betankung : 30|1@1+ (1,0) [0|1] "" Vector__XXX
 SG_ NM_MO_Signalfehler : 32|1@1+ (1,0) [0|1] "" Vector__XXX
 SG_ NMH_MO_TimeOut_Fehler : 33|1@1+ (1,0) [0|1] "" Vector__XXX
 SG_ NMH_MO_CAN_Diag_deaktiv : 34|1@1+ (1,0) [0|1] "" Vector__XXX
 SG_ NMH_MO_KompSchutz : 35|1@1+ (1,0) [0|1] "" Vector__XXX
 SG_ NMH_MO_Mute_Mode : 36|1@1+ (1,0) [0|1] "" Vector__XXX
 SG_ NMH_MO_Transport_Mode : 37|1@1+ (1,0) [0|1] "" Vector__XXX
 SG_ NMH_MO_Abschaltstufe_aktiv : 38|1@1+ (1,0) [0|1] "" Vector__XXX
 SG_ NMH_MO_Eindraht_Fehler : 39|1@1+ (1,0) [0|1] "" Vector__XXX
 SG_ NMH_MO_Lokalaktiv : 48|1@1+ (1,0) [0|1] "" Vector__XXX
 SG_ NMH_MO_Subsystemaktiv : 49|1@1+ (1,0) [0|1] "" Vector__XXX

BO_ 1736 NMH_Motor_Slave: 7 Motor2_MLB_D4_C7
 SG_ NMH_MO_SL_Start_1 : 0|1@1+ (1,0) [0|1] ""  BMS_Hybrid,EPB_MLB,Gateway,Getriebe_AL551_951_D4_C7,Getriebe_AL551_Hybrid_D4_C7,Getriebe_DL382_MLB,Getriebe_DL501_MLB,Getriebe_VL381_MLB,LEH_Hybrid,Motor2_MLB_D4_C7,Motor_MLB_AU64_AU57_Diesel,Motor_MLB_BY_Otto,Motor_MLB_C7_PHEV,Motor_MLB_D4_C7_Hybrid,Motor_MLB_D4_C7_Otto,SCR_MLB
 SG_ NMH_MO_SL_Start_2 : 1|1@1+ (1,0) [0|1] "" Vector__XXX
 SG_ NMH_MO_SL_Normal_Mode_1 : 2|1@1+ (1,0) [0|1] "" Vector__XXX
 SG_ NMH_MO_SL_Normal_Mode_2 : 3|1@1+ (1,0) [0|1] "" Vector__XXX
 SG_ NMH_MO_SL_Car_WakeUp : 6|1@1+ (1,0) [0|1] "" Vector__XXX
 SG_ NMH_MO_SL_Per_WakeUp : 8|5@1+ (1,0) [0|31] "" Vector__XXX
 SG_ NMH_MO_SL_Fkt_WakeUp : 13|3@1+ (1,0) [0|7] "" Vector__XXX
 SG_ NMH_MO_SL_NM_aktiv_Klemme_15 : 16|1@1+ (1,0) [0|1] "" Vector__XXX
 SG_ NMH_MO_SL_NM_aktiv_Diagnose : 17|1@1+ (1,0) [0|1] "" Vector__XXX
 SG_ NMH_MO_SL_NM_aktiv_Start : 18|1@1+ (1,0) [0|1] "" Vector__XXX
 SG_ NMH_MO_SL_NM_aktiv_EKP_Vorlauf : 19|1@1+ (1,0) [0|1] "" Vector__XXX
 SG_ NMH_MO_SL_NM_aktiv_STH_Betrieb : 20|1@1+ (1,0) [0|1] "" Vector__XXX
 SG_ NMH_MO_SL_NM_aktiv_HV : 21|1@1+ (1,0) [0|1] "" Vector__XXX
 SG_ NMH_MO_kein_NL : 24|1@1+ (1,0) [0|1] "" Vector__XXX
 SG_ NMH_MO_NL_Kuehlerluefter : 25|1@1+ (1,0) [0|1] "" Vector__XXX
 SG_ NMH_MO_NL_Diagnose : 26|1@1+ (1,0) [0|1] "" Vector__XXX
 SG_ NMH_MO_NL_WFS : 27|1@1+ (1,0) [0|1] "" Vector__XXX
 SG_ NMH_MO_NL_EEPROM : 28|1@1+ (1,0) [0|1] "" Vector__XXX
 SG_ NMH_MO_NL_Sonstige : 29|1@1+ (1,0) [0|1] "" Vector__XXX
 SG_ NM_MO_SL_Signalfehler : 32|1@1+ (1,0) [0|1] "" Vector__XXX
 SG_ NMH_MO_SL_TimeOut_Fehler : 33|1@1+ (1,0) [0|1] "" Vector__XXX
 SG_ NMH_MO_SL_CAN_Diag_deaktiv : 34|1@1+ (1,0) [0|1] "" Vector__XXX
 SG_ NMH_MO_SL_KompSchutz : 35|1@1+ (1,0) [0|1] "" Vector__XXX
 SG_ NMH_MO_SL_Mute_Mode : 36|1@1+ (1,0) [0|1] "" Vector__XXX
 SG_ NMH_MO_SL_Transport_Mode : 37|1@1+ (1,0) [0|1] "" Vector__XXX
 SG_ NMH_MO_SL_Abschaltstufe_aktiv : 38|1@1+ (1,0) [0|1] "" Vector__XXX
 SG_ NMH_MO_SL_Busfehler : 39|1@1+ (1,0) [0|1] "" Vector__XXX
 SG_ NMH_MO_Sl_Lokalaktiv : 48|1@1+ (1,0) [0|1] "" Vector__XXX
 SG_ NMH_MO_SL_Subsystemaktiv : 49|1@1+ (1,0) [0|1] "" Vector__XXX

BO_ 1782 NMH_SCR: 7 SCR_MLB
 SG_ NMH_SCR_Start_1 : 0|1@1+ (1,0) [0|1] ""  BMS_Hybrid,EPB_MLB,Gateway,Getriebe_AL551_951_D4_C7,Getriebe_AL551_Hybrid_D4_C7,Getriebe_DL382_MLB,Getriebe_DL501_MLB,Getriebe_VL381_MLB,LEH_Hybrid,Motor2_MLB_D4_C7,Motor_MLB_AU64_AU57_Diesel,Motor_MLB_BY_Otto,Motor_MLB_C7_PHEV,Motor_MLB_D4_C7_Hybrid,Motor_MLB_D4_C7_Otto,SCR_MLB
 SG_ NMH_SCR_Start_2 : 1|1@1+ (1,0) [0|1] "" Vector__XXX
 SG_ NMH_SCR_Normal_Mode_1 : 2|1@1+ (1,0) [0|1] "" Vector__XXX
 SG_ NMH_SCR_Normal_Mode_2 : 3|1@1+ (1,0) [0|1] "" Vector__XXX
 SG_ NMH_SCR_Car_WakeUp : 6|1@1+ (1,0) [0|1] "" Vector__XXX
 SG_ NMH_SCR_Per_WakeUp : 8|5@1+ (1,0) [0|31] "" Vector__XXX
 SG_ NMH_SCR_Fkt_WakeUp : 13|3@1+ (1,0) [0|7] "" Vector__XXX
 SG_ NMH_SCR_Klemme_15 : 16|1@1+ (1,0) [0|1] "" Vector__XXX
 SG_ NMH_SCR_Diagnose : 17|1@1+ (1,0) [0|1] "" Vector__XXX
 SG_ NMH_SCR_MindestAktivZeit : 18|1@1+ (1,0) [0|1] "" Vector__XXX
 SG_ NMH_SCR_NL_Datem_EEPROM : 24|1@1+ (1,0) [0|1] "" Vector__XXX
 SG_ NMH_SCR_NL_OBD_Diagnose : 25|1@1+ (1,0) [0|1] "" Vector__XXX
 SG_ NMH_SCR_Signalfehler : 32|1@1+ (1,0) [0|1] "" Vector__XXX
 SG_ NMH_SCR_TimeOut_Fehler : 33|1@1+ (1,0) [0|1] "" Vector__XXX
 SG_ NMH_SCR_CAN_Diag_deaktiv : 34|1@1+ (1,0) [0|1] "" Vector__XXX
 SG_ NMH_SCR_KompSchutz : 35|1@1+ (1,0) [0|1] "" Vector__XXX
 SG_ NMH_SCR_Mute_Mode : 36|1@1+ (1,0) [0|1] "" Vector__XXX
 SG_ NMH_SCR_Transport_Mode : 37|1@1+ (1,0) [0|1] "" Vector__XXX
 SG_ NMH_SCR_Abschaltstufe_aktiv : 38|1@1+ (1,0) [0|1] "" Vector__XXX
 SG_ NMH_SCR_Busfehler : 39|1@1+ (1,0) [0|1] "" Vector__XXX
 SG_ NMH_SCR_Lokalaktiv : 48|1@1+ (1,0) [0|1] "" Vector__XXX
 SG_ NMH_SCR_Subsystemaktiv : 49|1@1+ (1,0) [0|1] "" Vector__XXX

BO_TX_BU_ 782 : Motor_MLB_AU64_AU57_Diesel,Motor_MLB_BY_Otto,Motor_MLB_C7_PHEV,Motor_MLB_D4_C7_Hybrid,Motor_MLB_D4_C7_Otto;
BO_TX_BU_ 1088 : Motor_MLB_AU64_AU57_Diesel,Motor_MLB_BY_Otto,Motor_MLB_C7_PHEV,Motor_MLB_D4_C7_Hybrid,Motor_MLB_D4_C7_Otto;
BO_TX_BU_ 1600 : Motor_MLB_AU64_AU57_Diesel,Motor_MLB_BY_Otto,Motor_MLB_C7_PHEV,Motor_MLB_D4_C7_Hybrid,Motor_MLB_D4_C7_Otto;
BO_TX_BU_ 1607 : Motor_MLB_AU64_AU57_Diesel,Motor_MLB_BY_Otto,Motor_MLB_C7_PHEV,Motor_MLB_D4_C7_Hybrid,Motor_MLB_D4_C7_Otto;
BO_TX_BU_ 276 : Motor_MLB_AU64_AU57_Diesel,Motor_MLB_BY_Otto,Motor_MLB_C7_PHEV,Motor_MLB_D4_C7_Hybrid,Motor_MLB_D4_C7_Otto;
BO_TX_BU_ 168 : Motor_MLB_C7_PHEV,Motor_MLB_D4_C7_Hybrid;
BO_TX_BU_ 1648 : Motor_MLB_AU64_AU57_Diesel,Motor_MLB_BY_Otto,Motor_MLB_C7_PHEV,Motor_MLB_D4_C7_Hybrid,Motor_MLB_D4_C7_Otto;
BO_TX_BU_ 815 : Motor_MLB_AU64_AU57_Diesel,Motor_MLB_BY_Otto,Motor_MLB_C7_PHEV,Motor_MLB_D4_C7_Hybrid,Motor_MLB_D4_C7_Otto;
BO_TX_BU_ 1391 : Motor_MLB_AU64_AU57_Diesel,Motor_MLB_C7_PHEV,Motor_MLB_D4_C7_Hybrid;
BO_TX_BU_ 1014 : Motor_MLB_AU64_AU57_Diesel,Motor_MLB_C7_PHEV,Motor_MLB_D4_C7_Hybrid,Motor_MLB_D4_C7_Otto;
BO_TX_BU_ 1601 : Motor_MLB_AU64_AU57_Diesel,Motor_MLB_BY_Otto,Motor_MLB_C7_PHEV,Motor_MLB_D4_C7_Hybrid,Motor_MLB_D4_C7_Otto;
BO_TX_BU_ 305 : Motor_MLB_C7_PHEV,Motor_MLB_D4_C7_Hybrid;
BO_TX_BU_ 1376 : Motor_MLB_C7_PHEV,Motor_MLB_D4_C7_Hybrid;
BO_TX_BU_ 1730 : Getriebe_AL551_951_D4_C7,Getriebe_AL551_Hybrid_D4_C7,Getriebe_DL382_MLB,Getriebe_DL501_MLB,Getriebe_VL381_MLB;
BO_TX_BU_ 1729 : Motor_MLB_AU64_AU57_Diesel,Motor_MLB_BY_Otto,Motor_MLB_C7_PHEV,Motor_MLB_D4_C7_Hybrid,Motor_MLB_D4_C7_Otto;
CM_ SG_ 782 Motor_05_CHK "Berechnung siehe Lastenheft 'Kommunikationsabsicherung für FlexRay und CAN'
Endwerte siehe 'Kommunikationsabsicherung für FlexRay und CAN / Anhang C: Tabelle S-PDU Kennungen'";
CM_ SG_ 782 MO_EKlKomLeiRed "Anforderung an die Klimasteuerung, die Leistungsaufnahme des E-Kompressors bei schlechtem SOC und in bestimmten Fahrsituationen zu begrenzen. (Das bereits bestehende Signal 'Klimakompressor aus' als stets umzusetzende Anforderung bleibt unverändert besteh";
CM_ SG_ 782 MO_Freig_Reku "Empfehlung des Motor-SG's zur Spannungsabsenkung/-anhebung für den Rekuperationsbetrieb";
CM_ SG_ 782 MO_Klima_Eingr "Eingriffe des Motor bei der Klima";
CM_ SG_ 782 MO_Status_Normalbetrieb_02 "Signal ausschließlich für AUDI B8.
Auch im B8 nur GSG Empfänger dieses Signales.
Alle weiteren Fahrzeuge verwenden das Signal in Motor_02.

Das Motorsteuergerät sendet das Informationsbit, wenn die Initialisierungsphase des Steuergerätes abgeschlossen";
CM_ SG_ 782 MO_Schaltbeeinfl_Leistungsbegr "Schaltbeeinflussung an das Getriebe wegen Leistungsbegrenzung";
CM_ SG_ 782 MO_Schaltbeeinfl_Partikelfilter "Schaltbeeinflussung an das Getriebe wegen Partikelfilter-Regeneration
";
CM_ SG_ 782 MO_Prio_MIN_Wunschdrehzahl "Prioritätsbit der Motorwunschdrehzahl als MIN";
CM_ SG_ 782 MO_Freig_Anlass "Bit wird gesetzt, wenn der Motor beim Automatikstart gestartet werden darf (Motorstillstand, Emissionsmaßnahmen sind erfüllt).";
CM_ SG_ 782 MO_Aussp_Anlass "Das Signal zeigt an, ob die Wiederholstartsperre aktiv ist. D. h. eine Ansteuerung des Anlassers wird auch bei erfüllten Startvoraussetzungen (HS: Interlock betätigt bzw. AT: P/N eingelegt und Bremse betätigt) nicht erfolgen.";
CM_ SG_ 782 MO_MAX_Wunschdrehzahl "maximale Motorwunschdrehzahl aufgrund Systemfehlern, Temperatur oder Verbrauchs/ Abgas Optimum, die vom Getriebe nicht überschritten werden darf";
CM_ SG_ 782 MO_Prio_MAX_Wunschdrehzahl "Prioritätsbit der Motorwunschdrehzahl  als MAX";
CM_ SG_ 782 MO_Luftpfad_aktiv "Getriebeeingriff wird zusätzlich zum Zündungspfad auch über den Luftpfad umgesetzt, kommt zu MLB neu in die PL48-Getriebe";
CM_ SG_ 782 MO_v_Begrenz_Aktiv "Motor begrenzt aktuell die Geschwindigkeit des Fahrzeugs; Reaktion auf externe oder interne Anforderung";
CM_ SG_ 782 MO_v_Begrenz_Aktivierbar "Fehlerbit wird vom Motor-SG gesetzt, wenn dieses nicht in dieGeschwindigkeits-begrenzung gehen kann, ein Fehler während der v-Begrenzung auftritt oder v > v_Begrenzung - v_Delta";
CM_ SG_ 782 MO_Verbot_EKP "Es gilt: Signalspec MO_Verbot_EKP V1.1

MSG sendet Verbot der EKP-Ansteuerung an das BCM";
CM_ SG_ 782 MO_Anf_Pruefimpuls "Es gilt: Signalspec MO_Anf_Pruefimpuls v1.1

Anforderung des MSG an das BCM  zum Senden eines Prüfimpulses zur Diagnose der Wakeup-Leitung auf Dauerlow";
CM_ SG_ 782 MO_Anf_KL75 "Information wann die Kl. 75 während des Startvorgangs abgeschaltet werden soll. Umsetzung durch BCM2.";
CM_ SG_ 782 MO_Charisma_FahrPr "Aktuelles Fahrprogramm des Charisma-Teilnehmers

Achtung neue Modusnamen (wie im MMI):

0x1 = Komfort = Comfort
0x2 = Dynamik = Auto
0x3 = Sport = Dynamic";
CM_ SG_ 782 MO_Charisma_Status "Charisma Systemstatus des Charisma-Teilnehmers

Wert 0x3 ist nur für Fahrzeuge ab MQB relevant";
CM_ SG_ 782 MO_Charisma_Umschaltung "Erkennung  Umschaltaufforderung des Charisma-Teilnehmers";
CM_ SG_ 782 MO_Handshake_STH "Es gilt: Signalspec MO_Handshake v1.0

Handshake zwischen MSG und STH. Wenn das MSG die EKP aufgrund einer STH-Anforderung ansteuert und kein Fehlereintrag bzgl. EKP/KPE/NDR vorliegt, wird das Bit gesetzt.";
CM_ SG_ 782 MO_MIN_Wunschdrehzahl "minimale Motorwunschdrehzahl aufgrund Regeneration, die vom Getriebe nicht unterschritten werden darf";
CM_ SG_ 782 MO_Drehzahlbeeinflussung "Mit diesem Faktor kann das Motorsteuergerät die vom CVT-Getriebe einzustellende Sollmotodrehzahl beeinflussen. Im CVT-Steuergerät ist ein verbrauchsoptimales Kennfeld und ein abgasoptimiertes Kennfeld abgelegt. Mit dem Wert von 0-100% wird zwischen diesen";
CM_ SG_ 1088 MO_Kuehlerluefter_MUX "Multiplexer für das Signal 'MO_Kuehlerlüfter'";
CM_ SG_ 1088 MO_Kuehlerluefter_1 "Ansteuertastverhaeltnis (PWM) der Kuehlerluefterendstufe 1";
CM_ SG_ 1088 MO_Kuehlerluefter_2 "Ansteuertastverhaeltnis (PWM) der Kuehlerluefterendstufe 2";
CM_ SG_ 1088 MO_HYB_Status_HV_Ladung "Statusanzeige für Funktion HV-Ladung über 12V-Seite";
CM_ SG_ 1088 MO_ITM_Warnung_Pumpe "Textanzeige: 'Motor sofort abstellen, geschaltete Wasserpumpe defekt / klemmt'";
CM_ SG_ 1088 WIV_Anzeige_aktiv "Peilstabsanzeigefunktion aktiv";
CM_ SG_ 1088 WIV_Oelmin_Warn "Signal gibt an wenn der Ölstand die Min-Schwelle unterschritten hat";
CM_ SG_ 1088 WIV_Sensorfehler "Ölstand/Öltemperatursensor (TOG) defekt";
CM_ SG_ 1088 WIV_Schieflage "Fahrzeug steht nicht waagerecht, Messung ungenau";
CM_ SG_ 1088 WIV_Oelstand "8 Segmente zur Balkenanzeige des Ölstands";
CM_ SG_ 1088 MO_Zustand_HWP "Rückmeldung des  Ansteuerzustand der Hauptwasserpumpe an das Klima-SG .
Der Zustand 'HWP fördert' wird übermittelt, wenn die Schaufeln der Hauptwasserpumpe frei drehen können und die Motordrehzahl und damit die Wasserpumpendrehzahl größer als Null ist. B";
CM_ SG_ 1088 MO_Kat_Warnung "Das Signal lässt im Kombi des LB83x eine Warnlampe angehen um eine Überhitzung   des Katalysators zu signalisieren";
CM_ SG_ 1088 MO_Vorglueh_Lampe "Vorglühlampe im Kombi, Kombi steuert immer gleiche LED an. 
Mit Einführung des Einheits-Kombis sind getrennte Signalwege für Vorglühlampe und EPCL notwendig.";
CM_ SG_ 1088 WIV_Oelsystem_aktiv "Gesamtölsystem aktiv (entspricht Ölsensor verbaut) und das Ölstand-Untermenu im MMI aktiv";
CM_ SG_ 1088 WIV_nicht_betriebswarm "Motor nicht betriebswarm, Messung ungenau";
CM_ SG_ 1088 WIV_Ueberfuell_Warn "Ölstand hat die Überfüllschwelle überschritten";
CM_ SG_ 1088 WIV_laufender_Motor "Messung bei laufendem Motor nicht möglich";
CM_ SG_ 1088 MO_HYB_Text_1 "Textanzeige: Fehler Hybridsystem
bitte Fahrzeug an sicherem Ort anhalten";
CM_ SG_ 1088 MO_HYB_Text_2 "Textanzeige: Fehler Hybridystem
bitte Werkstatt aufsuchen";
CM_ SG_ 1088 MO_HYB_Text_3 "Textanzeige: Bitte Motor erneut starten";
CM_ SG_ 1088 MO_HYB_Text_4 "Textanzeige: E-Mode unterbrochen (passiv)";
CM_ SG_ 1088 MO_Text_Motorstart "Anzeigetexte für Start/Stopp und Motor-Start";
CM_ SG_ 1088 MO_HYB_Text_5 "Textanzeige: Hybrid-Funktionen nicht verfügbar";
CM_ SG_ 1088 MO_HYB_Text_6 "Textanzeige: Elektrisches Fahren zur Zeit nicht möglich";
CM_ SG_ 1088 MO_HYB_Text_7 "Textanzeige: Traktionsbatterie wird geladen bitte Motor nicht abstellen";
CM_ SG_ 1088 WIV_Oeldyn_avl "Ölstand aus dynamischer Messung vorhanden";
CM_ SG_ 1088 MO_Text_MSG_Werkstatt "Über dieses Bit wird im Kombi ein Fehlerklartextanzeige erzeugt werden: 'Motorsteuergerät Werkstatt'.
";
CM_ SG_ 1088 MO_Text_Partikelfil_Reg "Über dieses Bit im Kombi wird ein Klartextanzeige erzeugt werden: 'Partikelfilter benötigt Regeneration'.
";
CM_ SG_ 1088 MO_Text_Fehler_Kraftstoffsys "Über dieses Bit wird im Kombi ein Fehlerklartextanzeige erzeugt wird: 'Fehler im Kraftstoffsystem'.	
";
CM_ SG_ 1088 WIV_Oelmenge "Ölmenge zwischen Min und Max";
CM_ SG_ 1088 MO_Systemlampe "EGas Systemlampe (EPC) oder Vorglühlampe im Kombi, Kombi steuert immer gleiche
LED an, nur über Ziffernblatt wird die EPC von der Vorglühlampe differenziert";
CM_ SG_ 1088 MO_OBD2_Lampe "OBD bzw. MIL-Lampe wird vom Motorsteuergerät angesteuert, die Information im Signal GE_OBD_Status wird vom Motorsteuergerät an das Kombi weitergereicht";
CM_ SG_ 1088 MO_Heissleuchte "Ansteuerung der Kühlwassertemperatur-Heißleuchte (Sensor nur noch am Motorsteuergerät): Temperaturschaltschwellen mit Hysterese (bei VW D1/Colorado Kombi derzeit noch nicht genutzt).";
CM_ SG_ 1088 MO_Partikel_Lampe "Partikelfilter-Lampe wird eingeschaltet";
CM_ SG_ 1088 WIV_Oelstand_nicht_vorhanden "Kein aktueller Ölstand vorhanden";
CM_ SG_ 1088 WIV_nachfuellanzeige_ein "Steuert das Aufblenden der Nachfüllanzeige im Kombi, nach Klemme 15 ein und geöffneter Motorhaube";
CM_ SG_ 1088 WIV_Ueberfuell_deaktiv "Unterdrückung der Warnung im Kombi die durch Signal WIV_Ueberfuel_Warn ausgelöst wird";
CM_ SG_ 1088 WIV_Unterfuell_Warn "Ölstand hat die Unterfüllschwelle unterschritten";
CM_ SG_ 1088 MO_Tankdeckel_Lampe "Ansteuerung Tankdeckel-Warnlampe Kombiinstrument (nur Ottomotoren) z.Zt. Vorhalt VW";
CM_ SG_ 1088 MO_Text_Tankdeckelwarn "Textbit der Tankdeckelwarnung, z.Zt. Vorhalt VW";
CM_ SG_ 1088 WIV_Enable_Oeldr_Motor "Schaltet die interne Öldruckauswertung im Kombiinstrument ab und aktiviert die Auswertung des Bits 'WIV_Oeldr_Warn_Motor'";
CM_ SG_ 1088 WIV_Oeldr_Warn_Motor "Löst im Kombiinstrument die rote Prio1-Öldruckwarnung (inkl. 3xBeep) aus.
nur MLB: die Warnauslösung erfolgt nur bei gleichzeitig gesetztem 'WIV_Enable_Oeldr_Motor'";
CM_ SG_ 1088 MO_Avus_Motorschutz "Warntexten zum Kombi für den Fall des Avus-Notlauf. Priowarnung, kann parallel mit anderen Warnungen 
im Mitteldisplay angezeigt werden.";
CM_ SG_ 1088 MO_HYB_Fahrbereitschaft "Signal steuert u.a. in der Lenkhilfe zusammen mit weiteren Informationen den Modewechsel in den 'Drivemode'
Grüne Anzeige im Kombiinstrument zur Signalisierung der Bereitschaft des Hybridsystems.";
CM_ SG_ 1600 MO_QBit_Ansaugluft_Temp "
";
CM_ SG_ 1600 MO_QBit_Kuehlmittel_Temp "
";
CM_ SG_ 1600 MO_HYB_Fehler_HV_Netz "Im HV-Bordnetz ist fehlerbedingt kein generatorischer Betrieb möglich. Das 12V-Bordnetz wird über den DC/DC-Wandler allein aus der Traktionsbatterie gespeist. Um diesen Zustand möglichst lange aufrechterhalten zu können, sollten Komfort-Verbraucher abgesc";
CM_ SG_ 1600 MO_aktives_Getriebeheizen "Information für Getriebe, ob ein Ventil für Getriebheizen angesteuert werden muss";
CM_ SG_ 1600 MO_Absperrventil_oeffnen "Signal an Klima-SG das Absperrrventil anzusteuern. Ab D4 auch 0x3 Ventil_schließen.

Im MQB wird hier der Soll-Status des Absperrventils ausgegeben.
Achtung: bei z. B. klemmendem Ventil entspricht das Signal nicht dem tatsächlichen Status!";
CM_ SG_ 1600 MO_Ansaugluft_Temp "In Fahrzeugen ohne Außentemperatur vom Kombi kann aus der Ansauglufttemperatur auf die Außentemperatur geschlossen werden. Beim SDI ist das mit einer gewissen Genauigkeit gegeben. Genutzt wird es vom ASG.";
CM_ SG_ 1600 MO_Oel_Temp "Realer Meßbereich ca. -40..150 Grad";
CM_ SG_ 1600 MO_Kuehlmittel_Temp "Kuehlmitteltemperatur";
CM_ SG_ 1600 MO_Hoeheninfo "Korrekturfaktor Höhe (1 entspricht 1013 mbar)";
CM_ SG_ 1600 MO_Kennfeldk "Die Kennfeldkühlung ist in diesem Fahrzeug verbaut und hat keinen Systemfehler";
CM_ SG_ 1600 MO_Versionsinfo "Versioninformation vom Motor zur Steuerung bei inkompatiblen KMatrix-Änderung bzw. Einführung von neuen Funktionen, die in den Empfängern verriegelt werden müssen. Zu jedem Ereignis wird ein fixer Zählerstand zugeordnet, um dem Empfänger die funktionale Ä";
CM_ SG_ 1600 MO_Getriebe_kuehlen "Anforderung Getriebekühlventilansteuerung";
CM_ SG_ 1600 MO_Mom_Traegheit_02 "Massenträgheit des Motors (J) in kgm²
Bei Handschaltern wird das Zweimassenschwungrad mit berücksichtigt.
Bei eingebautem Getriebesteuergerät wird nur das Motorträgheitsmoment angegeben (Ohne Anteile des Massenschwungrades).";
CM_ SG_ 1600 MO_Heizungspumpenansteuerung "Anforderung Heizungspumpenansteuerung
MQB und Hybrid: Status der Heizungsunterstützungspumpe am MSG
";
CM_ SG_ 1600 MO_SpannungsAnf "Forderung des Motor-SGs zur Spannungsanhebung";
CM_ SG_ 1600 MO_Nachlaufzeit_Heizungspumpe "Nachlaufzeit für Heizungspumpe für Turboladerschutz";
CM_ SG_ 1607 MO_ITM_Kuehlmittel_Temp "Kuehlmitteltemperatur: Ersatzkühlmitteltemperatur für Motoren mit ITM (Thermomanagement)

ACHTUNG: Ab MQB wird in diesem Signal das Anzeigeplateau durch das MSG dargestellt!";
CM_ SG_ 1607 MO_E85_Sensor "Information über den E85 Gehalt (%-mass.) im Ottokraftstoff";
CM_ SG_ 1607 SCR_Anz_Motorstarts "Anzahl noch möglicher Motorstarts, wenn Reichweite = 0 ist
0..13 = Anzeige 'x mögliche Restarts'
14 = Eingeschränkte Fahrfunktion (z. Zt. Audi)
15 = keine Einschränkung (Anzeige Reichweite)
Bedienung des Signals nur bei Dieseln mit SCR-System.";
CM_ SG_ 1607 SCR_Reichweite "Gesamtreichweite in km der aktuellen SCR-Tankfüllung.
Bedienung des Signals nur bei Dieseln mit SCR-System.";
CM_ SG_ 1607 MO_Ethanol_Spuelhinweis "Hinweis das der Fahrer beim nächsten Tanken Ethanol armen Sprit tanken soll.";
CM_ SG_ 1607 SCR_Warnstufe_1 "Ansteuerung der SCR Füllstandswarnlampe (Stufe 1) (gelbe Lampe) SCR_Warnstufe_1 (Prio 2).
Bedienung des Signals nur bei Dieseln mit SCR-System. Andere senden Initwert.";
CM_ SG_ 1607 SCR_Warnstufe_2 "Ansteuerung der SCR Füllstandswarnlampe (Stufe 2) (Blinkbit für gelbe Lampe oder rote Lampe) SCR_Warnstufe_2 (Prio 1).
Bedienung des Signals nur bei Dieseln mit SCR-System. Andere senden Initwert.";
CM_ SG_ 1607 SCR_Text "Warntext (z. B. in Kombination mit SCR Warnstufe und SCR-Systemfehler).
Bedienung des Signals nur bei Dieseln mit SCR-System. Andere senden Initwert.";
CM_ SG_ 1607 SCR_Akustik "Ansteuerung von Summer/Gong bei Aktivieren der SCR-Warnungen.
Bedienung des Signals nur bei Dieseln mit SCR-System. Andere senden Initwert.";
CM_ SG_ 1607 SCR_verbaut "Die SCR-Signale deren Initwert ungleich 0 sind, werden nur dann ausgewertet, wenn SCR_verbaut == 1 den Verbau des SCR Systems zeigt.";
CM_ SG_ 1607 MO_Kraftstofffilter_Wasser "Für Schlechtkraftstoffländer wird das Wasserabscheidevolumen im Dieselkraftstofffilter mit einem  Wassersensor überwacht. Ist das Volumen erschöpft, erfolgt im Kombi eine entsprechende Anzeige.";
CM_ SG_ 1607 SCR_Systemfehler "Ansteuerung Anzeige für SCR-Systemfehler";
CM_ SG_ 1607 SCR_Inducement_Strategie "Art des Motor-Inducement-Konzepts. Abhängig von diesem Signal sind die Warntexte zwischen 'Kein Motorstart (in...km)' und 'eingeschränkte Fahrbarkeit (in ...km)' auszuwählen.";
CM_ SG_ 1607 MO_CO2_Faktor "dynamischer Umrechnungsfaktor von l in CO2";
CM_ SG_ 1607 MO_MKB_MUX "Die vier Motorkennbuchstaben werden gemultiplext in MO_MKB übertragen. Das Signal MO_MKB_MUX stellt das Steuersignal für diesen Multiplexer dar.";
CM_ SG_ 1607 MO_MKB_01 "Motorkennbuchstabe 1";
CM_ SG_ 1607 MO_MKB_02 "Motorkennbuchstabe 2";
CM_ SG_ 1607 MO_MKB_03 "Motorkennbuchstabe 3";
CM_ SG_ 1607 MO_MKB_04 "Motorkennbuchstabe 4";
CM_ SG_ 276 Motor_10_CHK "Berechnung siehe Lastenheft 'Kommunikationsabsicherung für FlexRay und CAN'
Endwerte siehe 'Kommunikationsabsicherung für FlexRay und CAN / Anhang C: Tabelle S-PDU Kennungen'";
CM_ SG_ 276 MO_Sig_Fahrpedalgradient "Kennzeichnet das Vorzeichen des Signal 'Fahrpedalgradient'. Die Ausgabe erfolgt nur parallel statisch mit gesendetem Signal: 'Steuerungsbit Fahrpedalgradient' ";
CM_ SG_ 276 MO_BKV_Unterdruckwarnung "Über die Unterdruckwarnung signalisiert das MSG dem ESP, dass kein ausreichender Unterdruck für den BKV zur Verfügung gestellt werden kann.";
CM_ SG_ 276 MO_Zylinderabschaltung "Status Zylinderabschaltung Motor";
CM_ SG_ 276 MO_Fahrpedalgradient "Das Motorsteuergerät besitzt 2 analoge Fahrpedalsignale. Das Signal des ersten Kanals wird alle 4ms abgetastet. Um Bitschwankungen des A/D-Wandler herauszufiltern wird das Signal entjittert. Anschließend wird der Gradient berechnet. Entsprechend der Zyklu";
CM_ SG_ 276 MO_Schubabschaltung "ESP plausibilisiert Unterdrucksensor nur bei aktiver Schubabschaltung";
CM_ SG_ 276 MO_rel_Saugrohrdruck "Der Wert gibt an, um wieviel mbar der Saugrohrdruck unterhalb des Umgebungsdrucks liegt. Überdruck im Saugrohr wird nicht ausgegeben.
0: Saugrohrdruck=Umgebungsdruck";
CM_ SG_ 276 MO_rel_Saugrohrdruck_gem_err "0: mind. eine Modellrechnung wird zur Berechnung des relativen Saugdrucks herangezogen
1: Relativer Saugrohrdruck wird ausschließlich über Messgrößen bestimmt";
CM_ SG_ 276 MO_BKV_Unterdruck "Der maximale Wert wird auf 1012 mbar begrenzt";
CM_ SG_ 276 MO_Bremspedalweg "Bremspedalwert in Prozent. Der Wert ist Nullpunkt-abgeglichen.";
CM_ SG_ 276 MO_Mom_Traegheit_Summe "Einheitenloser Wert! Faktor in MO_Faktor_Momente (CAN V6.x) bzw. MO_Faktor_Momente_02 (CAN V7.x) in Motor_Code_01 beachten!

Moment, das zur Beschleunigung der trägen Massen aufgewendet wird bzw. frei wird; Summen aus Anteilen für Verbrennungsmotor und ";
CM_ SG_ 276 MO_ANC_Kennfeld_Anf "Anforderung ANC Kennfeldumschaltung";
CM_ BO_ 168 "Teil 2 neue Momentenschnittstelle MLB";
CM_ SG_ 168 Motor_12_CRC "Für MLB:
'Berechnung siehe Lastenheft 'Kommunikationsabsicherung für FlexRay und CAN''

Ab MQB und MLBevo:
'Berechnung siehe Lastenheft 'End-to-End Kommunikationsabsicherung'

Endwerte siehe Begleitdokument 'S-PDU Kennungsfolgen'";
CM_ SG_ 168 MO_Mom_neg_verfuegbar "Einheitenloser Wert! Faktor in MO_Faktor_Momente (CAN V6.x) bzw. MO_Faktor_Momente_02 (CAN V7.x) in Motor_Code_01 beachten!

Bei aktueller Drehzahl im nächsten Task (bei CAN-Übertragung z.B. 10ms) tatsächlich verfügbares negatives Moment (Summe aus Verl";
CM_ SG_ 168 MO_Mom_Begr_stat "Einheitenloser Wert! Faktor in MO_Faktor_Momente (CAN V6.x) bzw. MO_Faktor_Momente_02 (CAN V7.x) in Motor_Code_01 beachten!

Bei aktueller Drehzahl max. mögliches Moment (Summe aus Verbrennungsmotor und E-Motor) aus stat. Vollastkurve, korrigiert für ak";
CM_ SG_ 168 MO_Mom_Begr_dyn "Einheitenloser Wert! Faktor in MO_Faktor_Momente (CAN V6.x) bzw. MO_Faktor_Momente_02 (CAN V7.x) in Motor_Code_01 beachten!

Bei aktueller Drehzahl kurzfristig (ca. 100..200 ms) max. mögliches Moment (Summe aus Verbrennungsmotor und E-Motor), zeigt alle";
CM_ SG_ 168 MO_Momentenintegral_02 "100  %  entspricht volle Verfügbarkeit aktuell vorhanden. 0 % entspricht Integral bis Limit gefüllt, erhöhender Eingriff kann aktuell nicht berücksichtigt werden oder aufgrund eines Fehlers nicht verfügbar
";
CM_ SG_ 168 MO_QBit_Drehzahl_01 "AUDI D4: Zykluszeit: 10ms (siehe Zykluszeit schnell/Cycletime Fast)

Achtung:
Reduktion der Zykluszeit Motor_03 auf 10ms geplant.
Projektabhängig soll künftig mit 10ms gesendet werden.
Empfänger die in weiteren Konzern-Projekten eingesetzt werden müs";
CM_ SG_ 168 MO_Drehzahl_01 "Im Fehlerfall wird die Motordrehzahl über die Nockenwellendrehzahl als Ersatzgrösse ausgegeben

Bei Parallelhybrid: Getriebeeingangsdrehzahl (=E-Maschinen Drehzahl)";
CM_ BO_ 1648 "Kombischnittstelle";
CM_ SG_ 1648 MO_max_Ladedruck "maximal möglicher Ladedruck (zur Anpassung des Anzeigebereichs bei absoluter Ladedruckanzeige)";
CM_ SG_ 1648 MO_ANC_Kennfeld_Anf "Anforderung ANC Kennfeldumschaltung";
CM_ SG_ 1648 MO_Bremslicht_Reku "Bremslicht (ggf. bei Rekuperation durch E-Motor) wird angesteuert";
CM_ SG_ 1648 MO_StartStopp_PopUp "Das Signal zeigt an, ob der StSt-Status mittels Deaktivierungstaster geändert wurde. Ein Wechsel auf die Werte 01 oder 10 löst im Kombi ein entsprechendes PopUp aus. Bei einem Statuswechsel durch andere Signalquellen (z.B. Charisma, fehlerbedingte Abschal";
CM_ SG_ 1648 MO_EPCL "tbd";
CM_ SG_ 1648 MO_Zylabsch_Texte_02 "ZAS-Anzeige für den Fahrer im Kombi
0: kein ZAS (generell keinerlei ZAS-Anzeigen)  (Init für nicht ZAS-Motor)
1: ZAS im Vollmotorbetrieb  (Init für ZAS-Motor)
2: ZAS im Abschaltbetrieb: 1 Zyl aktiv
3: ZAS im Abschaltbetrieb: 2 Zyl aktiv
4: ZAS im Abs";
CM_ SG_ 1648 MO_Fahrzeugtyp "Unterscheidet die Fahrzeugtypen bzgl. der Antriebsart";
CM_ SG_ 1648 MO_NMAX_Schaltanzeige "Maximaldrehzahl für Schaltanzeige";
CM_ SG_ 1648 MO_Abstellzeit "Abstelldauer nach letztem KL15 aus";
CM_ SG_ 1648 MO_Abstellzeit_Status "Statusinformation zur Abstellzeit
0: Die dem Status zugeordnete Variable konnte noch nicht berechnet werden. 
1: Die dem Status zugehörige Variable wurde korrekt berechnet. 
2: Der Wert der zugehörigen Variablen ist nur ein Minimalwert. 
3: Der Wert d";
CM_ SG_ 1648 MO_Hybrid_StartStopp_LED "Ansteuerung der Funktions-LED der Hybrid Taste bzw. Start/Stop Deaktivierungstaste.
Der Start/Stopp-Master (derzeit im MSG) (oder ein künftiger Hybrid-Master) soll die Ansteuerung senden.";
CM_ SG_ 1648 MO_Fehler_Zylabsch "Fehlerstatus der Funktion Zylinderabschaltung ";
CM_ SG_ 1648 MO_Anzahl_Abgesch_Zyl "Gibt die Anzahl der abgeschalteten Zylinder an. In Übergangszuständen wird der Zielbetriebszustand angezeigt.";
CM_ SG_ 1648 MO_Zylabsch_Texte "Zylinderabschaltung mode in Kombi, fuer Zylinderabschaltung";
CM_ SG_ 1648 MO_Ethanol_BS_Texte "Ethanol Brennstoff-Texte im Kombi

0 = kein Text
1 = E85 Warm_Up
2 = FlexFuel Warnung 3.Stufe (Too cold for ethanol)
3 = Warmfahrempfehlung MQB / FlexFuel Warnung 1.Stufe (Refuel with gasoline)
4 = FlexFuel Warnung 2. Stufe (Refuel with gasoline)
5";
CM_ SG_ 1648 MO_Drehzahl_Warnung "Warnhinweis zum Kombi im Fall einer fehlerbehafteten Drehzahlbegrenzung";
CM_ SG_ 1648 MO_obere_Drehzahlgrenze "obere Drehzahlgrenze des Motors";
CM_ BO_ 1010 "SCR-Schnittstelle";
CM_ SG_ 1010 Motor_19_BZ "Zähler der von der Applikation inkrementiert wird";
CM_ SG_ 1010 MO_SCR_Tankheizkreis_Leistung "der Tankheizer soll Leistungsgeregelt werden";
CM_ SG_ 1010 MO_SCR_Heizkreis_3 "Heizkreis 3 einschalten";
CM_ SG_ 1010 MO_SCR_Tankheizung "Anforderung Tankheizung";
CM_ SG_ 1010 MO_SCR_Dosierpumpe_Zustand "In welchen Zustand die  Dosierpumpe geschaltet wird";
CM_ SG_ 1010 MO_SCR_Leitungsheizung "Anforderung Leitungsheizung";
CM_ SG_ 1010 MO_SCR_Dosierpumpe_Wartezeit "Zeit nach der bei KL15_AUS das Rücksaugen der Leitung en beginnen soll. Abhängig von der AGA-Temperatur";
CM_ SG_ 1010 MO_SCR_Transferpumpe "Ansteuern der Tansferpumpe zum Umpumpen vom Passivtank zum Aktivtank";
CM_ SG_ 1010 MO_SCR_Dosierpumpe_Soll "Sollwert zur Pumpensteuerung im eingestellten Zustand
Drehzahlregulierung 100% entspricht 4000 1/min
Druckregelung 100% entspricht 10 bar";
CM_ SG_ 815 MO_Antriebsstrang_Warnung_HS "Status der Fehlerlampen-Ansteuerung und Textausgabe für Fehlerspeichereinträge aus der Kupplungsschutz-Funktion für Handschaltgetriebe.";
CM_ SG_ 815 MO_Anzeige_Verbrauch "Anzeige Verbrauchssignal fürs Kombi.
Im Bezug auf Verbrennerbeteiligung.";
CM_ SG_ 1391 MO_IstLeistung_EKAT "Gesamt IST-Leistung der elektrischen Heizscheibe(n)";
CM_ SG_ 1391 MO_HYB_Drehzahl_VM "für OBD freeze frame";
CM_ SG_ 191 Motor_27_CRC "Für MLB:
'Berechnung siehe Lastenheft 'Kommunikationsabsicherung für FlexRay und CAN''

Ab MQB und MLBevo:
'Berechnung siehe Lastenheft 'End-to-End Kommunikationsabsicherung''

Endwerte siehe Begleitdokument 'S-PDU Kennungsfolgen'";
CM_ SG_ 191 MO_Mom_dyn_Diff "dynamisches Differenzmoment zwischen berechneten inneren Motormoment und dem zylinderdruckbasierten gemessenen inneren Motormoment";
CM_ SG_ 1014 MO_Tankklappensteuerung "Ansteuerungsanforderung der Tankklappe";
CM_ SG_ 1014 MO_Kl_50 "Klemme 50: Startausführung
";
CM_ SG_ 1014 MO_Freigabe_Segeln "Freigabebit des Segelbetriebs im Getriebe. Bedingt durch bestimmte Diagnosen und Adaptionen des MSGs, die nur im Schub möglich sind, darf nicht jede Schubphase für einen Segelbetrieb genutzt werden. Eine Freigabe bleibt auch außerhalb einer Schubphase bes";
CM_ BO_ 1601 "MLB";
CM_ SG_ 1601 Motor_Code_01_CHK "Berechnung siehe Lastenheft 'Kommunikationsabsicherung für FlexRay und CAN'
Endwerte siehe 'Kommunikationsabsicherung für FlexRay und CAN / Anhang C: Tabelle S-PDU Kennungen'


";
CM_ SG_ 1601 MO_Faktor_Momente "Dieses Bit schaltet den Wertebereich aller Momente vom Motor, Getriebe, TSK, ESP ... um! Die Momente besitzen somit einen variablen Wertebereich, weil sich durch den Faktor die Momente sowohl in Auflösung als auch Maximalwerten ändert.

Defaultwert ist ";
CM_ SG_ 1601 MO_Hybridfahrzeug "Anhand dieses Signals plausibilisiert die Lenkhilfe das Bit Fahrbereitschaft.

Im Projekt Cayenne PHEV (und ggf. auch VW526 PHEV) ist aus Gründen der Abwärtskompatibilität der Wert '2' zu senden.";
CM_ SG_ 1601 MO_Code "Motorcodierinformation für Getriebe. Überwachung auf Falschverbau.";
CM_ SG_ 1601 MO_Getriebe_Code "Getriebecodierung des Motors";
CM_ SG_ 1601 MO_StartStopp_Codiert "Funktion StartStopp im aktuellen Klemmenzyklus verbaut";
CM_ SG_ 1601 MO_Anzahl_Zyl "Zylinderzahl des Verbrennungsmotors";
CM_ SG_ 1601 MO_Kraftstoffart "Primärkraftstoff zum Antrieb des Fahrzeugs";
CM_ SG_ 1601 MO_Hubraum "Hubraum des Verbrennungsmotors";
CM_ SG_ 1601 MO_Ansaugsystem "Art des Ansaugsystems des Verbrennungsmotors";
CM_ SG_ 1601 MO_Leistung "Nennleistung des Verbrennungsmotors";
CM_ SG_ 1601 MO_Abgastyp "Bit 0:
0x0 = kein EOBD
0x1 = EOBD

Bit 1:
0x0 = kein OBD (US-Norm)
0x1 = OBD (US-Norm)

Bit 2: 
0x0 = kein DPF verbaut
0x1 = DPF verbaut

Bit 5: 
0x0 = DPF regeneriert nicht
0x1 = DPF regeneriert
";
CM_ SG_ 305 MO_ePowermeter "Anzeige ePowermeter (Fahrreserve elektrisch bis Start Verbrennungsmotor (Verbrenner startet bei 100%))";
CM_ SG_ 305 MO_Zust_Antrieb "Signalisiert die Zuordnung der Antriebsverbräuche zu den Antriebsmaschinen für die Restreichweitenberechnung, nicht gleichbedeutend mit Motorlauf EM oder VM";
CM_ SG_ 305 MO_Zust_Betriebsstrategie "Signalisiert den aktuellen Zustand der Betriebsstrategie";
CM_ SG_ 305 MO_W_Reku_normiert_ueberlauf "Motorsteuergeräteinterner Rekuperationszähler, der vom Kombi ausgewertet wird, um die Rekuperierte Arbeit/Leistung zu erfassen.";
CM_ SG_ 305 Ladezustand "Ladezustand der Batterie
";
CM_ SG_ 305 Enrgfluss_State "Energiefluss zwischen den Achsen, Batterie, Elektromotor und Verbrennungsmotor";
CM_ SG_ 305 MO_W_Reku_normiert "Motorsteuergeräteinterner Rekuperationszähler, der vom Kombi ausgewertet wird, um die Rekuperierte Arbeit/Leistung zu erfassen.";
CM_ SG_ 305 MO_Powermeter "Anzeigewerte im Kombi
0       = Unteres Ende Bremsen/grau;
340   = Unteres Ende CHARGE;
1020 = READY;
1870 = Oberes Ende EFFICIENCY;
3400 = 100%;
4080 = MAX;";
CM_ SG_ 1376 Motor_Hybrid_04_CRC "'Berechnung siehe Lastenheft 'End-to-End Kommunikationsabsicherung'

Endwerte siehe Begleitdokument 'S-PDU Kennungsfolgen'";
CM_ SG_ 1376 Motor_Hybrid_04_BZ "4bit-Botschaftszaehler, wird in jeder Sendebotschaft inkrementiert";
CM_ SG_ 1376 MO_HV_Spannungsfreiheit "Anzeige der Spannungsfreiheit des HV-Systems im Kombi (Service und Produktion). 

Abhängigkeiten zu anderen Signalen:
BMS_Status_Spannungsfreiheit und EM_Status_Spannungsfreiheit und BMS_Status_ServiceDisconnect";
CM_ SG_ 1376 MO_Reku_Leistung "Durchschnittliche Rekuperationsleistung zur Umrechnung im Kombi";
CM_ SG_ 1376 Mo_Powermeter_Grenze "Anzeige des verfügbaren Powermeterstands im Kombi. Bei EV Unterscheidung zwischen Boost- und Dauerbereich, bei HEV für die Zustartgrenze nutzber";
CM_ SG_ 1376 MO_Gesamtst_Spgfreiheit "0x0 (00)   Funktion Init (ohne Funktion)
0x1 (01)   HV-System spannungsfrei 
0x2 (10)   HV-System nicht spannungsfrei 
0x3 (11)   Fehler";
CM_ SG_ 1376 MO_Tankbereitschaft_Status "Meldung der Tankbereitschaft";
CM_ SG_ 1376 MO_Energieinhalt_BMS "Restenergieinhalt der Traktionsbatterie, beeinflusst durch Fahrstrategie und weiteren Faktoren der Antriebssteuerung.";
CM_ SG_ 1376 MO_HYB_Status_Betriebsstrategie "Zustände der Betriebsstrategie im MSG";
CM_ SG_ 1376 MO_Boost_aktiv "Anzeige im Kombi ob Boostmode aktiv ist.
Nur für Au210/7 Flottenfahrzeuge. Entfall zur Serientopologie";
CM_ BO_ 969 "neu: geänderte ID wg. Verschiebung NMH";
CM_ BO_ 1696 "MLBevo ohne KD-Bit";
CM_ SG_ 1696 NV_aktiv "Nightvision aktiviert (liefert Bild)";
CM_ SG_ 1696 NV_Gong "Das Signal löst einen Gong des NightVision-Systems im Kombidisplay aus";
CM_ SG_ 1696 NV_Symbol "Wenn das NV-System einen Fußgänger findet, fordert es mit dem Signal das HUD auf, ein Symbol zu zeigen";
CM_ SG_ 1696 NV_Hinweise "Das Signal dient dazu Hinweistexte in das NightVision Bild im Kombiinstrument einzublenden.Die Anzeigedauer der Hinweistexte ist Signalgesteuert. D.h., sie werden angezeigt bis das CAN-Signal s_NV_Texte seinen Wert ändert.";
CM_ SG_ 1696 NV_Piktogramm_aktiv "Signal sagt, dass das Piktogramm im NightVision-Reiter geändert werden soll";
CM_ SG_ 1696 NV_Akustik_deaktiviert_Icon "Ansteuerungssignal für das  Akustik-deaktiviert-Icon";
CM_ SG_ 1696 NV_FGM_deaktiviert_Icon "Ansteuerungssignal für das  Fussgängermarkierung-deaktiviert-Icon";
CM_ SG_ 1696 NV_Markierungslicht_links "Das Signal steuert die Aktivierung des Markierungslicht links bei Fußgängerwarnung";
CM_ SG_ 1696 NV_Markierungslicht_rechts "Das Signal steuert die Aktivierung des Markierungslicht rechts bei Fußgängerwarnung";
CM_ SG_ 1696 NV_Symbol_Tierwarnung "Signal zur Anforderung einer Symbolanzeige für Tierwarnung.";
CM_ SG_ 1696 NV_Anf_Prefill "Anforderung an ESP, dass die Prefill-Funktion aktiviert werden soll.";
CM_ SG_ 1696 NV_HBA_Parameter "Anforderung an ESP, welcher HBA-Parametersatz verwendet werden soll. Die Festlegung der Empfindlichkeitsschwellen der verschiedenen Parametersätze erfolgt mit der Applikation des Gesamtsystems ESP/ACC bzw. des HBA.
Nur Audi B8: Umsetzung der Anforderung ";
CM_ SG_ 1696 NV_KD_Fehler "Bei gesetztem Bit ist mindestens ein Kundendienstfehler eingetragen
";
CM_ BO_ 1742 "200 ms";
CM_ SG_ 1742 NMH_BMS_Start_1 "Transition in NMH-Statemachine: 'Bus-Sleep' ==> 'Start'
Das Bit wird von der Standard-SW bedient.";
CM_ SG_ 1742 NMH_BMS_Start_2 "Transition in NMH-Statemachine: 'Prepare To Sleep' ==> 'Start'
Das Bit wird von der Standard-SW bedient.";
CM_ SG_ 1742 NMH_BMS_Normal_Mode_1 "Transition in NMH-Statemachine: 'Start' ==> 'Normal Mode'
Das Bit wird von der Standard-SW bedient.";
CM_ SG_ 1742 NMH_BMS_Normal_Mode_2 "Transition in NMH-Statemachine: 'Ready To Sleep' ==> 'Normal'
Das Bit wird von der Standard-SW bedient.";
CM_ SG_ 1742 NMH_BMS_Car_WakeUp "Das Bit wird vom VSG nicht bedient. Die Car Wakeup-Funktionalität ist im BMS nicht umgesetzt.
";
CM_ SG_ 1742 NMH_BMS_Per_WakeUp "Peripherie-Wakeup (Peripherie inkl. CAN hat geweckt):
1 = CAN

";
CM_ SG_ 1742 NMH_BMS_Fkt_WakeUp "Funktions-Wakeup (Softwarefunktion hat geweckt):
0x0 Peripherie-Wakeup


";
CM_ SG_ 1742 NMH_BMS_Klemme_15 "NM-Nachlaufursache: Das BMS sendet noch NM-high Botschaften (befindet sich nicht im Zustand 'Ready To Sleep') aufgrund einer eingeschalteten Kl.15. In diesem Fall wird das Bit vom BMS gesetzt.";
CM_ SG_ 1742 NMH_BMS_Diagnose "NM-Nachlaufursache: Das BMS sendet noch NM-high Botschaften (befindet sich nicht im Zustand 'Ready To Sleep') bei Kl.15 AUS und aktiver Diagnosesession. In diesem Fall wird das Bit vom BMS gesetzt.";
CM_ SG_ 1742 NMH_BMS_MindestAktivZeit "NM-Nachlaufursache: Das BMS sendet noch NM-high Botschaften (befindet sich nicht im Zustand 'Ready To Sleep') aufgrund der Mindestaktivzeit von 4s. In diesem Fall wird das Bit vom BMS gesetzt.";
CM_ SG_ 1742 NMH_BMS_NL_Daten_EEPROM "EEPROM Datenspeicherung (lokaler / SG interner Nachlauf vor Wakeup)";
CM_ SG_ 1742 NMH_BMS_NL_Luefter "Lüftersteuerung für Batteriekühlung (lokaler / SG interner Nachlauf vor Wakeup)";
CM_ SG_ 1742 NMH_BMS_Signalfehler "Bei der Speicherung eines CAN-Signalfehlers muss dieser mindestens einmal in der NM-Botschaft angezeigt werden.";
CM_ SG_ 1742 NMH_BMS_TimeOut_Fehler "Das BMS hat einen aktiven Timeout-Fehler zu einem anderen SG erkannt und setzt dieses Bit. Der FSP-Eintrag ist aktiv. Sobald wieder Botschaften des anderen Teilnehmers empfangen werden (FSP-Eintrag passiv), wird das Bit zurückgesetzt.";
CM_ SG_ 1742 NMH_BMS_CAN_Diag_deaktiv "Das Bit wird vom BMS in folgenden Fällen gesetzt (CAN-Diagnose ist deaktiv):
- Hochlauf des Steuergeräts nach CAN-Wakeup (t_diag_start ist noch nicht abgelaufen)
- Retriggerung von t_diag_start bei Kl.15 EIN
- Unterspannung (U < 9V)
- Überspannung (U ";
CM_ SG_ 1742 NMH_BMS_KompSchutz "Das Bit wird vom BMS immer mit 0 gesendet";
CM_ SG_ 1742 NMH_BMS_Mute_Mode "Das Bit wird vom BMS wie folgt bedient: wenn über den UDS-Service 'Communication Control' ein Abschalten der Applikationsbotschaften gefordert wird und gleichzeitig noch NWM-Botschaften gesendet werden dürfen, dann wird das Bit gesetzt
";
CM_ SG_ 1742 NMH_BMS_Transport_Mode "Funktionseinschränkung aufgrund Transportmodus aktiv:
Das Bit wird vom BMS gesetzt, wenn das Signal 'BEM_02_Abschaltstufen' in der Botschaft BEM_02 den Wert 4 
(= Transportmodus) annimmt. Die Ambientebeleuchtung wird vom BMS abgeschaltet bzw. nicht eing";
CM_ SG_ 1742 NMH_BMS_Abschaltstufe_aktiv "Funktionseinschränkung aufgrund Abschaltstufe aktiv:
Das Bit wird vom BMS gesetzt, wenn das Signal 'BEM_02_Abschaltstufen' in der Botschaft BEM_02 den Wert 2 (= Stufe 2), den Wert 3 (= Stufe 3) oder den Wert 7 (= Ruhestrommessmodus) annimmt. Die Ambiente";
CM_ SG_ 1742 NMH_BMS_Busfehler "Das Bit wird vom BMS gesetzt, wenn der ERROR-Pin des CAN-Transceivers dem µController einen Fehler signalisiert.";
CM_ SG_ 1742 NMH_BMS_Lokalaktiv "Zeigt an ob Steuergerät lokal aktiv war";
CM_ SG_ 1742 NMH_BMS_Subsystemaktiv "Zeigt an ob ein Subsystem des SGs nach Klemme15 AUS und nach entsprechender MAX Aktivzeit noch aktiv war";
CM_ BO_ 1743 "Elektrischer Motor
200 ms";
CM_ SG_ 1743 NMH_EM_Start_1 "Transition in NMH-Statemachine: 'Bus-Sleep' ==> 'Start'
Das Bit wird von der Standard-SW bedient.";
CM_ SG_ 1743 NMH_EM_Start_2 "Transition in NMH-Statemachine: 'Prepare To Sleep' ==> 'Start'
Das Bit wird von der Standard-SW bedient.";
CM_ SG_ 1743 NMH_EM_Normal_Mode_1 "Transition in NMH-Statemachine: 'Start' ==> 'Normal Mode'
Das Bit wird von der Standard-SW bedient.";
CM_ SG_ 1743 NMH_EM_Normal_Mode_2 "Transition in NMH-Statemachine: 'Ready To Sleep' ==> 'Normal'
Das Bit wird von der Standard-SW bedient.";
CM_ SG_ 1743 NMH_EM_Car_WakeUp "Das Bit wird vom SG nicht bedient. Die Car Wakeup-Funktionalität ist im SG nicht umgesetzt.
";
CM_ SG_ 1743 NMH_EM_Per_WakeUp "Peripherie-Wakeup (Peripherie inkl. CAN hat geweckt):
1 = CAN

";
CM_ SG_ 1743 NMH_EM_Fkt_WakeUp "Funktions-Wakeup (Softwarefunktion hat geweckt):
0x0 Peripherie-Wakeup


";
CM_ SG_ 1743 NMH_EM_Klemme_15 "NM-Nachlaufursache: Das SG sendet noch NM-high Botschaften (befindet sich nicht im Zustand 'Ready To Sleep') aufgrund einer eingeschalteten Kl.15. In diesem Fall wird das Bit vom SG gesetzt.";
CM_ SG_ 1743 NMH_EM_Diagnose "NM-Nachlaufursache: Das SG sendet noch NM-high Botschaften (befindet sich nicht im Zustand 'Ready To Sleep') bei Kl.15 AUS und aktiver Diagnosesession. In diesem Fall wird das Bit vom SG gesetzt.";
CM_ SG_ 1743 NMH_EM_MindestAktivZeit "NM-Nachlaufursache: Das SG sendet noch NM-high Botschaften (befindet sich nicht im Zustand 'Ready To Sleep') aufgrund der Mindestaktivzeit von 4s. In diesem Fall wird das Bit vom SG gesetzt.";
CM_ SG_ 1743 NMH_EM_keine_HV_Entl "HV-Entladung nicht möglich (NM-Nachlaufursache, nicht 'Ready To Sleep')";
CM_ SG_ 1743 NMH_EM_NL_Datem_EEPROM "EEPROM Datenspeicherung (lokaler / SG interner Nachlauf vor Wakeup)";
CM_ SG_ 1743 NMH_EM_Signalfehler "Bei der Speicherung eines CAN-Signalfehlers muss dieser mindestens einmal in der NM-Botschaft angezeigt werden.";
CM_ SG_ 1743 NMH_EM_TimeOut_Fehler "Das SG hat einen aktiven Timeout-Fehler zu einem anderen SG erkannt und setzt dieses Bit. Der FSP-Eintrag ist aktiv. Sobald wieder Botschaften des anderen Teilnehmers empfangen werden (FSP-Eintrag passiv), wird das Bit zurückgesetzt.";
CM_ SG_ 1743 NMH_EM_CAN_Diag_deaktiv "Das Bit wird vom SG in folgenden Fällen gesetzt (CAN-Diagnose ist deaktiv):
- Hochlauf des Steuergeräts nach CAN-Wakeup (t_diag_start ist noch nicht abgelaufen)
- Retriggerung von t_diag_start bei Kl.15 EIN
- Unterspannung (U < 9V)
- Überspannung (U >";
CM_ SG_ 1743 NMH_EM_KompSchutz "Das Bit wird vom SG immer mit 0 gesendet";
CM_ SG_ 1743 NMH_EM_Mute_Mode "Das Bit wird vom SG wie folgt bedient: wenn über den UDS-Service 'Communication Control' ein Abschalten der Applikationsbotschaften gefordert wird und gleichzeitig noch NWM-Botschaften gesendet werden dürfen, dann wird das Bit gesetzt
";
CM_ SG_ 1743 NMH_EM_Transport_Mode "Funktionseinschränkung aufgrund Transportmodus aktiv:
Das Bit wird vom SG gesetzt, wenn das Signal 'BEM_02_Abschaltstufen' in der Botschaft BEM_02 den Wert 4 
(= Transportmodus) annimmt. Die Ambientebeleuchtung wird vom SG abgeschaltet bzw. nicht einges";
CM_ SG_ 1743 NMH_EM_Abschaltstufe_aktiv "Funktionseinschränkung aufgrund Abschaltstufe aktiv:
Das Bit wird vom SG gesetzt, wenn das Signal 'BEM_02_Abschaltstufen' in der Botschaft BEM_02 den Wert 2 (= Stufe 2), den Wert 3 (= Stufe 3) oder den Wert 7 (= Ruhestrommessmodus) annimmt. Die Ambienteb";
CM_ SG_ 1743 NMH_EM_Busfehler "Das Bit wird vom SG gesetzt, wenn der ERROR-Pin des CAN-Transceivers dem µController einen Fehler signalisiert.";
CM_ SG_ 1743 NMH_EM_Lokalaktiv "Zeigt an ob Steuergerät lokal aktiv war";
CM_ SG_ 1743 NMH_EM_Subsystemaktiv "Zeigt an ob ein Subsystem des SGs nach Klemme15 AUS und nach entsprechender MAX Aktivzeit noch aktiv war";
CM_ BO_ 1753 "200ms ab D4";
CM_ SG_ 1753 NMH_EPB_Start_1 "Zustand Start (<--Sleep)";
CM_ SG_ 1753 NMH_EPB_Start_2 "Zustand Start (<--Prepare to Sleep)";
CM_ SG_ 1753 NMH_EPB_Normal_Mode_1 "Zustand Normal Mode (<-- Start)";
CM_ SG_ 1753 NMH_EPB_Normal_Mode_2 "Zustand Normal Mode (<-- Ready to Sleep)";
CM_ SG_ 1753 NMH_EPB_Car_WakeUp "Car WakeUp (optional), wird vom EPB nicht gesendet";
CM_ SG_ 1753 NMH_EPB_Per_WakeUp "Weckursache Peripherie
";
CM_ SG_ 1753 NMH_EPB_Fkt_WakeUp "Weckursache Funktion
";
CM_ SG_ 1753 NMH_EPB_NM_aktiv_Klemme_15 "Kl.15 EIN (Nachlaufursache, nicht 'Ready To Sleep')";
CM_ SG_ 1753 NMH_EPB_NM_aktiv_Diagnose "Diagnose bei Kl 15 aus (Nachlaufursache, nicht 'Ready To Sleep')";
CM_ SG_ 1753 NMH_EPB_NM_aktiv_Start "Mindestaktivzeit Zustand 'Start' (Nachlaufursache, nicht 'Ready To Sleep')";
CM_ SG_ 1753 NMH_EPB_NM_aktiv_Schalter "Schalter aktiv (Nachlaufursache, nicht 'Ready To Sleep')";
CM_ SG_ 1753 NMH_EPB_NM_aktiv_Bedarf_Anzeige "EPB hat noch Anzeigebedarf im Kombi (Buskommunikation erforderlich)
(Nachlaufursache, nicht 'Ready To Sleep')
";
CM_ SG_ 1753 NMH_EPB_NM_aktiv_v_groesser_Null "v>0 bis zu ersten Fahrzeugstillstand (Nachlaufursache, nicht 'Ready To Sleep')";
CM_ SG_ 1753 NMH_EPB_AutoAdjust "Anzeige der Nachlaufursache wenn die Funktion Auto Adjust ausgeführt wird";
CM_ SG_ 1753 NMH_EPB_kein_NL "kein lokaler / SG interner Nachlauf vor Wakeup";
CM_ SG_ 1753 NMH_EPB_NL_Temp_Modell "Temperaturmodell (lokaler / SG interner Nachlauf vor Wakeup)";
CM_ SG_ 1753 NMH_EPB_NL_Min "Mindestlaufzeit nach Spezifikation noch nicht abgelaufen (kein lokaler / SG interner Nachlauf vor Wakeup)
";
CM_ SG_ 1753 NM_EPB_Signalfehler "Bei der Speicherung eines CAN-Signalfehlers muss dieser mindestens einmal in der NM-Botschaft angezeigt werden.";
CM_ SG_ 1753 NMH_EPB_TimeOut_Fehler "Aktiver Timeout Fehlerspeichereintrag";
CM_ SG_ 1753 NMH_EPB_CAN_Diag_deaktiv "CAN Bus bezogene Eigendiagnose deaktiviert (Überspannung, Unterspannung, Hochlaufphase, ...) ";
CM_ SG_ 1753 NMH_EPB_KompSchutz "Funktionseinschränung aufgrund Komponentenschutz aktiv";
CM_ SG_ 1753 NMH_EPB_Mute_Mode "Funktionseinschränung aufgrund Mute Mode aktiv, nur VW";
CM_ SG_ 1753 NMH_EPB_Transport_Mode "Funktionseinschränung aufgrund Transport Mode aktiv";
CM_ SG_ 1753 NMH_EPB_Abschaltstufe_aktiv "Funktionsabschaltung wegen Abschaltschaltstufe";
CM_ SG_ 1753 NMH_EPB_Eindraht_Fehler "Erkennung Eindrahtfehler";
CM_ SG_ 1753 NMH_EPB_Lokalaktiv "Zeigt an ob das SG nach Klemme15 AUS und nach entsprechender MAX Aktivzeit noch aktiv war";
CM_ SG_ 1753 NMH_EPB_Subsystemaktiv "Zeigt an ob ein Subsystem des SGs nach Klemme15 AUS und nach entsprechender MAX Aktivzeit noch aktiv war";
CM_ BO_ 1728 "D4 Kombi-Komfort 200ms";
CM_ SG_ 1728 NMH_GW_Start_1 "Zustand Start (<--Sleep)";
CM_ SG_ 1728 NMH_GW_Start_2 "Zustand Start (<--Prepare to Sleep)";
CM_ SG_ 1728 NMH_GW_Normal_Mode_1 "Zustand Normal Mode (<-- Start)";
CM_ SG_ 1728 NMH_GW_Normal_Mode_2 "Zustand Normal Mode (<-- Ready to Sleep)";
CM_ SG_ 1728 NMH_GW_Car_WakeUp "Car WakeUp (optional), wird vom GW nicht gesendet";
CM_ SG_ 1728 NMH_GW_Per_WakeUp "Weckursache Peripherie
";
CM_ SG_ 1728 NMH_GW_Fkt_WakeUp "Weckursache Funktion (Softwarefunktion hat geweckt)
0 = wenn Peripheriewakeup
1 = BDM BEM
2 = Car Wakeup empfangen: Das Bussegment wurde aufgrund einer CarWakeup Anforderung geweckt. Das GW hat zuvor eine NWM-Botschaft auf einem Bus mit aktiviertem Car";
CM_ SG_ 1728 NMH_GW_NM_aktiv_Klemme_15 "Kl.15 EIN (Nachlaufursache, nicht 'Ready To Sleep')";
CM_ SG_ 1728 NMH_GW_NM_aktiv_Diagnose "Diagnose bei Kl 15 aus (Nachlaufursache, nicht 'Ready To Sleep')";
CM_ SG_ 1728 NMH_GW_NM_aktiv_Start "Mindestaktivzeit Zustand 'Start' (Nachlaufursache, nicht 'Ready To Sleep')";
CM_ SG_ 1728 NMH_GW_NM_aktiv_BDM "BDM-Kommunikation (Nachlaufursache, nicht 'Ready To Sleep')
";
CM_ SG_ 1728 NMH_GW_NM_aktiv_Warnblinken "Warnblinken (NM-Nachlaufursache, nicht 'Ready To Sleep')
";
CM_ SG_ 1728 NMH_GW_NM_aktiv_ESP "ESP aktiv (Wakeup/Sleep-Konzept)
(NM-Nachlaufursache, nicht 'Ready To Sleep')
";
CM_ SG_ 1728 NMH_GW_NM_aktiv_EMP "Nachlauf Energiemanagementplannung";
CM_ SG_ 1728 NMH_GW_Abschaltstufe_3 "Abschaltstufe 3 (BEM) 
(SG-interner Nachlauf vor CAN-Wakeup)
";
CM_ SG_ 1728 NMH_GW_SG_Fehlerdauer "Steuergeraetefehlerdauer (BEM)
(SG-interner Nachlauf vor CAN-Wakeup)
";
CM_ SG_ 1728 NMH_GW_STH_Wakeup "Standheizungswakeup (BEM)
(SG-interner Nachlauf vor CAN-Wakeup)";
CM_ SG_ 1728 NMH_GW_NL_Diagnose "Gateway hat lokalen Nachlauf wegen Kommunikation mit Tester auf DiagCAN";
CM_ SG_ 1728 NM_GW_Signalfehler "Bei der Speicherung eines CAN-Signalfehlers muss dieser mindestens einmal in der NM-Botschaft angezeigt werden.";
CM_ SG_ 1728 NMH_GW_TimeOut_Fehler "Aktiver Timeout Fehlerspeichereintrag";
CM_ SG_ 1728 NMH_GW_CAN_Diag_deaktiv "CAN Bus bezogene Eigendiagnose deaktiviert (Überspannung, Unterspannung, Hochlaufphase, ...) ";
CM_ SG_ 1728 NMH_GW_KompSchutz "Funktionseinschränung aufgrund Komponentenschutz aktiv";
CM_ SG_ 1728 NMH_GW_Mute_Mode "Funktionseinschränung aufgrund Mute Mode aktiv, nur VW";
CM_ SG_ 1728 NMH_GW_Transport_Mode "Funktionseinschränung aufgrund Transport Mode aktiv";
CM_ SG_ 1728 NMH_GW_Abschaltstufe_aktiv "Funktionsabschaltung wegen Abschaltschaltstufe";
CM_ SG_ 1728 NMH_GW_Eindraht_Fehler "Erkennung Eindrahtfehler";
CM_ SG_ 1728 NMH_GW_ACAN "Antriebs-CAN aktiv (Wakeup/Sleep Konzept)
(NM-Nachlaufursache, nicht 'Ready To Sleep')
";
CM_ SG_ 1728 NMH_GW_KombiCAN "Kombi/Fahrwerks-CAN aktiv (Wakeup/Sleep Konzept)
(NM-Nachlaufursache, nicht 'Ready To Sleep')
";
CM_ SG_ 1728 NMH_GW_KomfortCAN "Komfort-CAN aktiv (Wakeup/Sleep Konzept)
(NM-Nachlaufursache, nicht 'Ready To Sleep')

";
CM_ SG_ 1728 NMH_GW_Infotainment "Infotainment aktiv (CAN oder MOST), Wakeup/Sleep-Konzept
(NM-Nachlaufursache, nicht 'Ready To Sleep')
";
CM_ SG_ 1728 NMH_GW_Fahrwerk "Fahrwerks-Bus aktiv (Wakeup/Sleep Konzept)
(NM-Nachlaufursache, nicht 'Ready To Sleep')
";
CM_ SG_ 1728 NMH_GW_WakeUp_CAN_Bus "Weckendes Bussegment (Welcher CAN hat geweckt bzw. CarWakeup angefordert?)

";
CM_ BO_ 1730 "200ms ab D4";
CM_ SG_ 1730 NMH_GE_Start_1 "Zustand Start (<--Sleep)";
CM_ SG_ 1730 NMH_GE_Start_2 "Zustand Start (<--Prepare to Sleep)";
CM_ SG_ 1730 NMH_GE_Normal_Mode_1 "Zustand Normal Mode (<-- Start)";
CM_ SG_ 1730 NMH_GE_Normal_Mode_2 "Zustand Normal Mode (<-- Ready to Sleep)";
CM_ SG_ 1730 NMH_GE_Car_WakeUp "Car WakeUp (optional), wird vom Getriebe nicht gesendet";
CM_ SG_ 1730 NMH_GE_Per_WakeUp "Weckurasche Peripherie
";
CM_ SG_ 1730 NMH_GE_Fkt_WakeUp "Weckursache Funktion

";
CM_ SG_ 1730 NMH_GE_NM_aktiv_Klemme_15 "Klemme 15 ein (NM-Nachlaufursache, nicht 'Ready To Sleep')
";
CM_ SG_ 1730 NMH_GE_NM_aktiv_Diagnose "Diagnose bei Kl 15 aus (Nachlaufursache, nicht 'Ready To Sleep')";
CM_ SG_ 1730 NMH_GE_NM_aktiv_Start "Mindestaktivzeit Zustand 'Start' (Nachlaufursache, nicht 'Ready To Sleep')";
CM_ SG_ 1730 NMH_GE_N_Haltephase "Falls Wefgahrsperre Nachlauf vor CAN-Wakeup aktiv (Nur AL-Getriebe)";
CM_ SG_ 1730 NMH_GE_Positionsanzeige "Nachlauf für die Anzeige der Getriebeposition im Kombi";
CM_ SG_ 1730 NMH_GE_kein_NL "kein lokaler / SG interner Nachlauf vor Wakeup";
CM_ SG_ 1730 NMH_GE_NL_Daten_EEPROM "EEPROM Datenspeicherung (lokaler / SG interner Nachlauf vor Wakeup)";
CM_ SG_ 1730 NMH_GE_NL_Drucksens "lokaler / SG interner Nachlauf: Wird gesetzt falls Druck auf einer der beiden Drucksensoren über applizierbarer Schwelle (bedeutet Motor läuft) vor CAN-Wakeup - nur VL Getriebe";
CM_ SG_ 1730 NMH_GE_NL_Abtrieb "lokaler / SG interner Nachlauf: Wird gesetzt falls Abtriebsdrehzahl größer applizierbarer Schwelle (bedeutet Fahrzeug bewegt sich) vor CAN-Wakeup - nicht DL Getriebe";
CM_ SG_ 1730 NMH_GE_NL_Waehlhebel "lokaler / SG interner Nachlauf: Wird gesetzt falls Wählhebel nicht in P oder N vor CAN-Wakeup - nur AL Getriebe";
CM_ SG_ 1730 NMH_GE_NL_Wegfahrsperre "lokaler / SG interner Nachlauf: Wird gesetzt falls Wegfahrsperre Nachlauf vor CAN-Wakeup aktiv - nur AL Getriebe";
CM_ SG_ 1730 NM_GE_Signalfehler "Bei der Speicherung eines CAN-Signalfehlers muss dieser mindestens einmal in der NM-Botschaft angezeigt werden.";
CM_ SG_ 1730 NMH_GE_TimeOut_Fehler "Aktiver Timeout Fehlerspeichereintrag  ";
CM_ SG_ 1730 NMH_GE_CAN_Diag_deaktiv "CAN Bus bezogene Eigendiagnose deaktiviert (Überspannung, Unterspannung, Hochlaufphase, ...) ";
CM_ SG_ 1730 NMH_GE_KompSchutz "Funktionseinschränung aufgrund Komponentenschutz aktiv";
CM_ SG_ 1730 NMH_GE_Mute_Mode "Funktionseinschränung aufgrund Mute Mode aktiv, nur VW";
CM_ SG_ 1730 NMH_GE_Transport_Mode "Funktionseinschränung aufgrund Transport Mode aktiv";
CM_ SG_ 1730 NMH_GE_Abschaltstufe_aktiv "Funktionsabschaltung wegen Abschaltschaltstufe";
CM_ SG_ 1730 NMH_GE_Eindraht_Fehler "Erkennung Eindrahtfehler";
CM_ SG_ 1730 NMH_GE_Lokalaktiv "Zeigt an ob das SG nach Klemme15 AUS und nach entsprechender MAX Aktivzeit noch aktiv war";
CM_ SG_ 1730 NMH_GE_Subsystemaktiv "Zeigt an ob ein Subsystem des SGs nach Klemme15 AUS und nach entsprechender MAX Aktivzeit noch aktiv war";
CM_ SG_ 1730 NMH_GSG_Subbusaktiv "Zeigt an ob der Subbus aktiv oder inaktiv ist";
CM_ BO_ 1729 "200ms ab D4";
CM_ SG_ 1729 NMH_MO_Start_1 "Zustand Start (<--Sleep)";
CM_ SG_ 1729 NMH_MO_Start_2 "Zustand Start (<--Prepare to Sleep)";
CM_ SG_ 1729 NMH_MO_Normal_Mode_1 "Zustand Normal Mode (<-- Start)";
CM_ SG_ 1729 NMH_MO_Normal_Mode_2 "Zustand Normal Mode (<-- Ready to Sleep)";
CM_ SG_ 1729 NMH_MO_Car_WakeUp "Car WakeUp (optional), wird vom Motor nicht gesendet";
CM_ SG_ 1729 NMH_MO_Per_WakeUp "Weckursache Peripherie
";
CM_ SG_ 1729 NMH_MO_Fkt_WakeUp "Weckursache Funktion
";
CM_ SG_ 1729 NMH_MO_NM_aktiv_Klemme_15 "Klemme 15 ein (NM-Nachlaufursache, nicht 'Ready To Sleep')";
CM_ SG_ 1729 NMH_MO_NM_aktiv_Diagnose "Diagnose bei Kl 15 aus (NM-Nachlaufursache, nicht 'Ready To Sleep')
";
CM_ SG_ 1729 NMH_MO_NM_aktiv_Start "Mindestaktivzeit Zustand 'Start' (NM-Nachlaufursache, nicht 'Ready To Sleep')";
CM_ SG_ 1729 NMH_MO_NM_aktiv_EKP_Vorlauf "EKP-Vorlauf (z. Zt. nicht bei Diesel)
(NM-Nachlaufursache, nicht 'Ready To Sleep')
";
CM_ SG_ 1729 NMH_MO_NM_aktiv_STH_Betrieb "STH-Betrieb (NM-Nachlaufursache, nicht 'Ready To Sleep')
";
CM_ SG_ 1729 NMH_MO_NM_aktiv_HV "Abschaltung HV-System:
Hybrid-Manager deaktiviert alle Hochvolt-Verbraucher für stromloses Öffnen der Batterieschütze
(Nachlaufursache, nicht 'Ready To Sleep')

Laden:
Nachlauf aufgrund Start des Ladevorganges HV-Batterie

Konditionieren:
Nachlauf";
CM_ SG_ 1729 NMH_MO_kein_NL "kein lokaler / SG interner Nachlauf vor Wakeup";
CM_ SG_ 1729 NMH_MO_NL_Kuehlerluefter "Kühlerlüfter Steuerung / Zusatzwasserpumpe (lokaler / SG interner Nachlauf vor Wakeup)";
CM_ SG_ 1729 NMH_MO_NL_Diagnose "Diagnosefunktionen (lokaler / SG interner Nachlauf vor Wakeup)";
CM_ SG_ 1729 NMH_MO_NL_WFS "Wegfahrsperre (lokaler / SG interner Nachlauf vor Wakeup)";
CM_ SG_ 1729 NMH_MO_NL_EEPROM "EEPROM Zugriffe RAM/ROM Tests (lokaler / SG interner Nachlauf vor Wakeup)";
CM_ SG_ 1729 NMH_MO_NL_Sonstige "Sonstige lokale / SG interne Nachläufe vor Wakeup";
CM_ SG_ 1729 NM_MO_01_NM_aktiv_Betankung "Betankung Drucktank";
CM_ SG_ 1729 NM_MO_Signalfehler "Bei der Speicherung eines CAN-Signalfehlers muss dieser mindestens einmal in der NM-Botschaft angezeigt werden.";
CM_ SG_ 1729 NMH_MO_TimeOut_Fehler "Aktiver Timeout Fehlerspeichereintrag  ";
CM_ SG_ 1729 NMH_MO_CAN_Diag_deaktiv "CAN Bus bezogene Eigendiagnose deaktiviert (Überspannung, Unterspannung, Hochlaufphase, ...) ";
CM_ SG_ 1729 NMH_MO_KompSchutz "Funktionseinschränung aufgrund Komponentenschutz aktiv";
CM_ SG_ 1729 NMH_MO_Mute_Mode "Funktionseinschränung aufgrund Mute Mode aktiv, nur VW";
CM_ SG_ 1729 NMH_MO_Transport_Mode "1 = Funktionseinschränung aufgrund Transport Mode aktiv";
CM_ SG_ 1729 NMH_MO_Abschaltstufe_aktiv "Funktionsabschaltung wegen Abschaltschaltstufe";
CM_ SG_ 1729 NMH_MO_Eindraht_Fehler "Erkennung Eindrahtfehler";
CM_ SG_ 1729 NMH_MO_Lokalaktiv "Zeigt an ob das SG nach Klemme15 AUS und nach entsprechender MAX Aktivzeit noch aktiv war";
CM_ SG_ 1729 NMH_MO_Subsystemaktiv "Zeigt an ob ein Subsystem des SGs nach Klemme15 AUS und nach entsprechender MAX Aktivzeit noch aktiv war";
CM_ BO_ 1736 "200ms D4";
CM_ SG_ 1736 NMH_MO_SL_Start_1 "Zustand Start (<--Sleep)";
CM_ SG_ 1736 NMH_MO_SL_Start_2 "Zustand Start (<--Prepare to Sleep)";
CM_ SG_ 1736 NMH_MO_SL_Normal_Mode_1 "Zustand Normal Mode (<-- Start)";
CM_ SG_ 1736 NMH_MO_SL_Normal_Mode_2 "Zustand Normal Mode (<-- Ready to Sleep)";
CM_ SG_ 1736 NMH_MO_SL_Car_WakeUp "Car WakeUp (optional), wird vom Motor nicht gesendet";
CM_ SG_ 1736 NMH_MO_SL_Per_WakeUp "Weckursache Peripherie
";
CM_ SG_ 1736 NMH_MO_SL_Fkt_WakeUp "Weckursache Funktion
";
CM_ SG_ 1736 NMH_MO_SL_NM_aktiv_Klemme_15 "Klemme 15 ein (NM-Nachlaufursache, nicht 'Ready To Sleep')";
CM_ SG_ 1736 NMH_MO_SL_NM_aktiv_Diagnose "Diagnose bei Kl 15 aus (NM-Nachlaufursache, nicht 'Ready To Sleep')
";
CM_ SG_ 1736 NMH_MO_SL_NM_aktiv_Start "Mindestaktivzeit Zustand 'Start' (NM-Nachlaufursache, nicht 'Ready To Sleep')";
CM_ SG_ 1736 NMH_MO_SL_NM_aktiv_EKP_Vorlauf "EKP-Vorlauf (z. Zt. nicht bei Diesel)
(NM-Nachlaufursache, nicht 'Ready To Sleep')
";
CM_ SG_ 1736 NMH_MO_SL_NM_aktiv_STH_Betrieb "STH-Betrieb (NM-Nachlaufursache, nicht 'Ready To Sleep')
";
CM_ SG_ 1736 NMH_MO_SL_NM_aktiv_HV "Abschaltung HV-System:
Hybrid-Manager deaktiviert alle Hochvolt-Verbraucher für stromloses Öffnen der Batterieschütze
(Nachlaufursache, nicht 'Ready To Sleep')

Laden:
Nachlauf aufgrund Start des Ladevorganges HV-Batterie

Konditionieren:
Nachlauf";
CM_ SG_ 1736 NMH_MO_kein_NL "kein lokaler / SG interner Nachlauf vor Wakeup";
CM_ SG_ 1736 NMH_MO_NL_Kuehlerluefter "Kühlerlüfter Steuerung / Zusatzwasserpumpe (lokaler / SG interner Nachlauf vor Wakeup)";
CM_ SG_ 1736 NMH_MO_NL_Diagnose "Diagnosefunktionen (lokaler / SG interner Nachlauf vor Wakeup)";
CM_ SG_ 1736 NMH_MO_NL_WFS "Wegfahrsperre (lokaler / SG interner Nachlauf vor Wakeup)";
CM_ SG_ 1736 NMH_MO_NL_EEPROM "EEPROM Zugriffe RAM/ROM Tests (lokaler / SG interner Nachlauf vor Wakeup)";
CM_ SG_ 1736 NMH_MO_NL_Sonstige "Sonstige lokale / SG interne Nachläufe vor Wakeup";
CM_ SG_ 1736 NM_MO_SL_Signalfehler "Bei der Speicherung eines CAN-Signalfehlers muss dieser mindestens einmal in der NM-Botschaft angezeigt werden.";
CM_ SG_ 1736 NMH_MO_SL_TimeOut_Fehler "Aktiver Timeout Fehlerspeichereintrag  ";
CM_ SG_ 1736 NMH_MO_SL_CAN_Diag_deaktiv "CAN Bus bezogene Eigendiagnose deaktiviert (Überspannung, Unterspannung, Hochlaufphase, ...) ";
CM_ SG_ 1736 NMH_MO_SL_KompSchutz "Funktionseinschränung aufgrund Komponentenschutz aktiv";
CM_ SG_ 1736 NMH_MO_SL_Mute_Mode "Funktionseinschränung aufgrund Mute Mode aktiv, nur VW";
CM_ SG_ 1736 NMH_MO_SL_Transport_Mode "1 = Funktionseinschränung aufgrund Transport Mode aktiv";
CM_ SG_ 1736 NMH_MO_SL_Abschaltstufe_aktiv "Funktionsabschaltung wegen Abschaltschaltstufe";
CM_ SG_ 1736 NMH_MO_Sl_Lokalaktiv "Zeigt an ob das SG nach Klemme15 AUS und nach entsprechender MAX Aktivzeit noch aktiv war";
CM_ SG_ 1736 NMH_MO_SL_Subsystemaktiv "Zeigt an ob ein Subsystem des SGs nach Klemme15 AUS und nach entsprechender MAX Aktivzeit noch aktiv war";
CM_ SG_ 1782 NMH_SCR_Start_1 "Transition in NMH-Statemachine: 'Bus-Sleep' ==> 'Start'
Das Bit wird von der Standard-SW bedient.";
CM_ SG_ 1782 NMH_SCR_Start_2 "Transition in NMH-Statemachine: 'Prepare To Sleep' ==> 'Start'
Das Bit wird von der Standard-SW bedient.";
CM_ SG_ 1782 NMH_SCR_Normal_Mode_1 "Transition in NMH-Statemachine: 'Start' ==> 'Normal Mode'
Das Bit wird von der Standard-SW bedient.";
CM_ SG_ 1782 NMH_SCR_Normal_Mode_2 "Transition in NMH-Statemachine: 'Ready To Sleep' ==> 'Normal'
Das Bit wird von der Standard-SW bedient.";
CM_ SG_ 1782 NMH_SCR_Car_WakeUp "Das Bit wird vom SG nicht bedient. Die Car Wakeup-Funktionalität ist im SG nicht umgesetzt.
";
CM_ SG_ 1782 NMH_SCR_Per_WakeUp "Peripherie-Wakeup (Peripherie inkl. CAN hat geweckt):
1 = CAN

";
CM_ SG_ 1782 NMH_SCR_Fkt_WakeUp "Funktions-Wakeup (Softwarefunktion hat geweckt):
0x0 Peripherie-Wakeup


";
CM_ SG_ 1782 NMH_SCR_Klemme_15 "NM-Nachlaufursache: Das SG sendet noch NM-high Botschaften (befindet sich nicht im Zustand 'Ready To Sleep') aufgrund einer eingeschalteten Kl.15. In diesem Fall wird das Bit vom SG gesetzt.";
CM_ SG_ 1782 NMH_SCR_Diagnose "NM-Nachlaufursache: Das SG sendet noch NM-high Botschaften (befindet sich nicht im Zustand 'Ready To Sleep') bei Kl.15 AUS und aktiver Diagnosesession. In diesem Fall wird das Bit vom SG gesetzt.";
CM_ SG_ 1782 NMH_SCR_MindestAktivZeit "NM-Nachlaufursache: Das SG sendet noch NM-high Botschaften (befindet sich nicht im Zustand 'Ready To Sleep') aufgrund der Mindestaktivzeit von 4s. In diesem Fall wird das Bit vom SG gesetzt.";
CM_ SG_ 1782 NMH_SCR_NL_Datem_EEPROM "EEPROM Datenspeicherung (lokaler / SG interner Nachlauf vor Wakeup)";
CM_ SG_ 1782 NMH_SCR_Signalfehler "Bei der Speicherung eines CAN-Signalfehlers muss dieser mindestens einmal in der NM-Botschaft angezeigt werden.";
CM_ SG_ 1782 NMH_SCR_TimeOut_Fehler "Das SG hat einen aktiven Timeout-Fehler zu einem anderen SG erkannt und setzt dieses Bit. Der FSP-Eintrag ist aktiv. Sobald wieder Botschaften des anderen Teilnehmers empfangen werden (FSP-Eintrag passiv), wird das Bit zurückgesetzt.";
CM_ SG_ 1782 NMH_SCR_CAN_Diag_deaktiv "Das Bit wird vom SG in folgenden Fällen gesetzt (CAN-Diagnose ist deaktiv):
- Hochlauf des Steuergeräts nach CAN-Wakeup (t_diag_start ist noch nicht abgelaufen)
- Retriggerung von t_diag_start bei Kl.15 EIN
- Unterspannung (U < 9V)
- Überspannung (U >";
CM_ SG_ 1782 NMH_SCR_KompSchutz "Das Bit wird vom SG immer mit 0 gesendet";
CM_ SG_ 1782 NMH_SCR_Mute_Mode "Das Bit wird vom SG wie folgt bedient: wenn über den UDS-Service 'Communication Control' ein Abschalten der Applikationsbotschaften gefordert wird und gleichzeitig noch NWM-Botschaften gesendet werden dürfen, dann wird das Bit gesetzt
";
CM_ SG_ 1782 NMH_SCR_Transport_Mode "Funktionseinschränkung aufgrund Transportmodus aktiv:
Das Bit wird vom SG gesetzt, wenn das Signal 'BEM_02_Abschaltstufen' in der Botschaft BEM_02 den Wert 4 
(= Transportmodus) annimmt. Die Ambientebeleuchtung wird vom SG abgeschaltet bzw. nicht einges";
CM_ SG_ 1782 NMH_SCR_Abschaltstufe_aktiv "Funktionseinschränkung aufgrund Abschaltstufe aktiv:
Das Bit wird vom SG gesetzt, wenn das Signal 'BEM_02_Abschaltstufen' in der Botschaft BEM_02 den Wert 2 (= Stufe 2), den Wert 3 (= Stufe 3) oder den Wert 7 (= Ruhestrommessmodus) annimmt. Die Ambienteb";
CM_ SG_ 1782 NMH_SCR_Busfehler "Das Bit wird vom SG gesetzt, wenn der ERROR-Pin des CAN-Transceivers dem µController einen Fehler signalisiert.";
CM_ SG_ 1782 NMH_SCR_Lokalaktiv "Zeigt an ob Steuergerät lokal aktiv war";
CM_ SG_ 1782 NMH_SCR_Subsystemaktiv "Zeigt an ob ein Subsystem des SGs nach Klemme15 AUS und nach entsprechender MAX Aktivzeit noch aktiv war";
BA_DEF_ BO_  "DiagRequest" ENUM  "No","Yes";
BA_DEF_ BO_  "DiagResponse" ENUM  "No","Yes";
BA_DEF_ BO_  "DiagState" ENUM  "No","Yes";
BA_DEF_ BO_  "GenMsgChkConstant" HEX 0 4095;
BA_DEF_ BO_  "GenMsgCycleTime" INT 0 65535;
BA_DEF_ BO_  "GenMsgCycleTimeFast" INT 0 65535;
BA_DEF_ BO_  "GenMsgDelayTime" INT 0 100000;
BA_DEF_ BO_  "GenMsgILSupport" ENUM  "No","Yes";
BA_DEF_ BO_  "GenMsgNrOfRepetition" INT 0 100;
BA_DEF_ BO_  "GenMsgPDUConstants" STRING ;
BA_DEF_ BO_  "GenMsgSendType" ENUM  "Cyclic","not_used","not_used","not_used","not_used","not_used","not_used","IfActive","NoMsgSendType";
BA_DEF_ BO_  "GenMsgStartDelayTime" INT 0 100000;
BA_DEF_ BO_  "NmMessage" ENUM  "No","Yes";
BA_DEF_ BO_  "NmhMessage" ENUM  "No","Yes";
BA_DEF_ BO_  "MsgType" ENUM  "Application","NM ","NMH","TP2.0","ISO-TP ","BAP","EID";
BA_DEF_ BO_  "VAGTP20_API" HEX 0 255;
BA_DEF_ BO_  "VAGTP20_DynConnection" ENUM  "No","Yes";
BA_DEF_ BO_  "VAGTP20_DynSetup" ENUM  "No","Yes";
BA_DEF_ BO_  "VAGTP20_StatConnection" ENUM  "No","Yes";
BA_DEF_ SG_  "GenSigActiveRepetitions" INT -2147483648 2147483647;
BA_DEF_ SG_  "GenSigInactiveValue" INT -2147483648 2147483647;
BA_DEF_ SG_  "GenSigSendType" ENUM  "Cyclic","OnWrite","OnWriteWithRepetition","OnChange","OnChangeWithRepetition","IfActive","IfActiveWithRepetition","NoSigSendType","OnChangeAndIfActive","OnChangeAndIfActiveWithRepetition";
BA_DEF_ SG_  "GenSigStartValue" INT -2147483648 2147483647;
BA_DEF_ SG_  "NWM-WakeupAllowed" ENUM  "No","Yes";
BA_DEF_ SG_  "GenSigFuncType" ENUM  "NoFunction","MsgCounter","CRC-8","XOR","XOR-2","DatedBit","SW-Kl15","CHK","Constant","Protocol","CRC-8-SAE_J1850";
BA_DEF_ SG_  "GenSigSwitchedByIgnition" ENUM  "No","Yes";
BA_DEF_ SG_  "Fehlerwert" HEX 0 2147483647;
BA_DEF_ SG_  "GenSigMissingSourceValue" HEX 0 2147483647;
BA_DEF_REL_ BU_SG_REL_  "GenSigTimeoutTime" INT 0 65535;
BA_DEF_DEF_REL_ "GenSigTimeoutTime" 0;
BA_DEF_DEF_  "DiagRequest" "No";
BA_DEF_DEF_  "DiagResponse" "No";
BA_DEF_DEF_  "DiagState" "No";
BA_DEF_DEF_  "GenMsgChkConstant" 0;
BA_DEF_DEF_  "GenMsgCycleTime" 0;
BA_DEF_DEF_  "GenMsgCycleTimeFast" 0;
BA_DEF_DEF_  "GenMsgDelayTime" 0;
BA_DEF_DEF_  "GenMsgILSupport" "No";
BA_DEF_DEF_  "GenMsgNrOfRepetition" 0;
BA_DEF_DEF_  "GenMsgPDUConstants" "";
BA_DEF_DEF_  "GenMsgSendType" "NoMsgSendType";
BA_DEF_DEF_  "GenMsgStartDelayTime" 0;
BA_DEF_DEF_  "NmMessage" "No";
BA_DEF_DEF_  "NmhMessage" "No";
BA_DEF_DEF_  "MsgType" "Application";
BA_DEF_DEF_  "VAGTP20_API" 0;
BA_DEF_DEF_  "VAGTP20_DynConnection" "No";
BA_DEF_DEF_  "VAGTP20_DynSetup" "No";
BA_DEF_DEF_  "VAGTP20_StatConnection" "No";
BA_DEF_DEF_  "GenSigActiveRepetitions" 0;
BA_DEF_DEF_  "GenSigInactiveValue" 0;
BA_DEF_DEF_  "GenSigSendType" "NoSigSendType";
BA_DEF_DEF_  "GenSigStartValue" 0;
BA_DEF_DEF_  "NWM-WakeupAllowed" "No";
BA_DEF_DEF_  "GenSigFuncType" "NoFunction";
BA_DEF_DEF_  "GenSigSwitchedByIgnition" "Yes";
BA_DEF_DEF_  "Fehlerwert" 0;
BA_DEF_DEF_  "GenSigMissingSourceValue" 0;
BA_ "GenMsgSendType" BO_ 782 0;
BA_ "GenMsgPDUConstants" BO_ 782 "0x0d,0x0d,0x0d,0x0d,0x0d,0x0d,0x0d,0x0d,0x0d,0x0d,0x0d,0x0d,0x0d,0x0d,0x0d,0x0d";
BA_ "GenMsgILSupport" BO_ 782 1;
BA_ "GenMsgCycleTime" BO_ 782 50;
BA_ "GenMsgChkConstant" BO_ 782 13;
BA_ "GenMsgSendType" BO_ 1088 0;
BA_ "GenMsgILSupport" BO_ 1088 1;
BA_ "GenMsgCycleTime" BO_ 1088 100;
BA_ "GenMsgSendType" BO_ 1600 0;
BA_ "GenMsgILSupport" BO_ 1600 1;
BA_ "GenMsgCycleTime" BO_ 1600 500;
BA_ "GenMsgSendType" BO_ 1607 0;
BA_ "GenMsgILSupport" BO_ 1607 1;
BA_ "GenMsgCycleTime" BO_ 1607 500;
BA_ "GenMsgSendType" BO_ 276 0;
BA_ "GenMsgPDUConstants" BO_ 276 "0x15,0x15,0x15,0x15,0x15,0x15,0x15,0x15,0x15,0x15,0x15,0x15,0x15,0x15,0x15,0x15";
BA_ "GenMsgILSupport" BO_ 276 1;
BA_ "GenMsgCycleTime" BO_ 276 20;
BA_ "GenMsgChkConstant" BO_ 276 21;
BA_ "GenMsgSendType" BO_ 168 0;
BA_ "GenMsgPDUConstants" BO_ 168 "0x3d,0x3d,0x3d,0x3d,0x3d,0x3d,0x3d,0x3d,0x3d,0x3d,0x3d,0x3d,0x3d,0x3d,0x3d,0x3d";
BA_ "GenMsgILSupport" BO_ 168 1;
BA_ "GenMsgCycleTime" BO_ 168 10;
BA_ "GenMsgChkConstant" BO_ 168 61;
BA_ "GenMsgSendType" BO_ 1648 0;
BA_ "GenMsgILSupport" BO_ 1648 1;
BA_ "GenMsgDelayTime" BO_ 1648 20;
BA_ "GenMsgCycleTime" BO_ 1648 500;
BA_ "GenMsgSendType" BO_ 1010 0;
BA_ "GenMsgILSupport" BO_ 1010 1;
BA_ "GenMsgCycleTime" BO_ 1010 100;
BA_ "GenMsgSendType" BO_ 815 0;
BA_ "GenMsgILSupport" BO_ 815 1;
BA_ "GenMsgCycleTime" BO_ 815 40;
BA_ "GenMsgSendType" BO_ 1391 0;
BA_ "GenMsgILSupport" BO_ 1391 1;
BA_ "GenMsgCycleTime" BO_ 1391 500;
BA_ "GenMsgSendType" BO_ 191 0;
BA_ "GenMsgPDUConstants" BO_ 191 "0xe6,0xe6,0xe6,0xe6,0xe6,0xe6,0xe6,0xe6,0xe6,0xe6,0xe6,0xe6,0xe6,0xe6,0xe6,0xe6";
BA_ "GenMsgILSupport" BO_ 191 1;
BA_ "GenMsgCycleTime" BO_ 191 10;
BA_ "GenMsgChkConstant" BO_ 191 230;
BA_ "GenMsgSendType" BO_ 1014 0;
BA_ "GenMsgILSupport" BO_ 1014 1;
BA_ "GenMsgDelayTime" BO_ 1014 20;
BA_ "GenMsgCycleTime" BO_ 1014 100;
BA_ "GenMsgSendType" BO_ 1601 0;
BA_ "GenMsgPDUConstants" BO_ 1601 "0x47,0x47,0x47,0x47,0x47,0x47,0x47,0x47,0x47,0x47,0x47,0x47,0x47,0x47,0x47,0x47";
BA_ "GenMsgILSupport" BO_ 1601 1;
BA_ "GenMsgCycleTime" BO_ 1601 1000;
BA_ "GenMsgChkConstant" BO_ 1601 71;
BA_ "GenMsgSendType" BO_ 305 0;
BA_ "GenMsgILSupport" BO_ 305 1;
BA_ "GenMsgCycleTime" BO_ 305 20;
BA_ "GenMsgSendType" BO_ 1376 0;
BA_ "GenMsgPDUConstants" BO_ 1376 "0x65,0x65,0x65,0x65,0x65,0x65,0x65,0x65,0x65,0x65,0x65,0x65,0x65,0x65,0x65,0x65";
BA_ "GenMsgILSupport" BO_ 1376 1;
BA_ "GenMsgCycleTime" BO_ 1376 200;
BA_ "GenMsgChkConstant" BO_ 1376 101;
BA_ "GenMsgSendType" BO_ 969 0;
BA_ "GenMsgILSupport" BO_ 969 1;
BA_ "GenMsgCycleTime" BO_ 969 100;
BA_ "GenMsgSendType" BO_ 1696 0;
BA_ "GenMsgILSupport" BO_ 1696 1;
BA_ "GenMsgDelayTime" BO_ 1696 30;
BA_ "GenMsgCycleTime" BO_ 1696 200;
BA_ "MsgType" BO_ 1742 2;
BA_ "NmhMessage" BO_ 1742 1;
BA_ "GenMsgCycleTime" BO_ 1742 200;
BA_ "MsgType" BO_ 1743 2;
BA_ "NmhMessage" BO_ 1743 1;
BA_ "GenMsgCycleTime" BO_ 1743 200;
BA_ "MsgType" BO_ 1753 2;
BA_ "NmhMessage" BO_ 1753 1;
BA_ "GenMsgCycleTime" BO_ 1753 200;
BA_ "MsgType" BO_ 1728 2;
BA_ "NmhMessage" BO_ 1728 1;
BA_ "GenMsgCycleTime" BO_ 1728 200;
BA_ "MsgType" BO_ 1730 2;
BA_ "NmhMessage" BO_ 1730 1;
BA_ "GenMsgCycleTime" BO_ 1730 200;
BA_ "MsgType" BO_ 1729 2;
BA_ "NmhMessage" BO_ 1729 1;
BA_ "GenMsgCycleTime" BO_ 1729 200;
BA_ "MsgType" BO_ 1736 2;
BA_ "NmhMessage" BO_ 1736 1;
BA_ "GenMsgCycleTime" BO_ 1736 200;
BA_ "MsgType" BO_ 1782 2;
BA_ "NmhMessage" BO_ 1782 1;
BA_ "GenMsgCycleTime" BO_ 1782 200;
BA_ "GenSigSwitchedByIgnition" SG_ 782 Motor_05_CHK 0;
BA_ "GenSigFuncType" SG_ 782 Motor_05_CHK 3;
BA_ "GenSigSendType" SG_ 782 Motor_05_CHK 0;
BA_ "GenSigSwitchedByIgnition" SG_ 782 Motor_05_BZ 0;
BA_ "GenSigFuncType" SG_ 782 Motor_05_BZ 1;
BA_ "GenSigSendType" SG_ 782 Motor_05_BZ 0;
BA_ "GenSigSwitchedByIgnition" SG_ 782 MO_EKlKomLeiRed 0;
BA_ "GenSigSendType" SG_ 782 MO_EKlKomLeiRed 0;
BA_ "GenSigSwitchedByIgnition" SG_ 782 MO_Freig_Reku 0;
BA_ "GenSigSendType" SG_ 782 MO_Freig_Reku 0;
BA_ "GenSigSwitchedByIgnition" SG_ 782 MO_Klima_Eingr 0;
BA_ "GenSigSendType" SG_ 782 MO_Klima_Eingr 0;
BA_ "GenSigSwitchedByIgnition" SG_ 782 MO_Status_Normalbetrieb_02 0;
BA_ "GenSigSendType" SG_ 782 MO_Status_Normalbetrieb_02 0;
BA_ "GenSigSwitchedByIgnition" SG_ 782 MO_Schaltbeeinfl_Leistungsbegr 0;
BA_ "GenSigSendType" SG_ 782 MO_Schaltbeeinfl_Leistungsbegr 0;
BA_ "GenSigSwitchedByIgnition" SG_ 782 MO_Schaltbeeinfl_Partikelfilter 0;
BA_ "GenSigSendType" SG_ 782 MO_Schaltbeeinfl_Partikelfilter 0;
BA_ "GenSigSwitchedByIgnition" SG_ 782 MO_Prio_MIN_Wunschdrehzahl 0;
BA_ "GenSigSendType" SG_ 782 MO_Prio_MIN_Wunschdrehzahl 0;
BA_ "GenSigSwitchedByIgnition" SG_ 782 MO_Freig_Anlass 0;
BA_ "GenSigSendType" SG_ 782 MO_Freig_Anlass 0;
BA_ "GenSigSwitchedByIgnition" SG_ 782 MO_Aussp_Anlass 0;
BA_ "GenSigSendType" SG_ 782 MO_Aussp_Anlass 0;
BA_ "Fehlerwert" SG_ 782 MO_MAX_Wunschdrehzahl 511;
BA_ "GenSigSwitchedByIgnition" SG_ 782 MO_MAX_Wunschdrehzahl 0;
BA_ "GenSigSendType" SG_ 782 MO_MAX_Wunschdrehzahl 0;
BA_ "GenSigSwitchedByIgnition" SG_ 782 MO_Prio_MAX_Wunschdrehzahl 0;
BA_ "GenSigSendType" SG_ 782 MO_Prio_MAX_Wunschdrehzahl 0;
BA_ "GenSigSwitchedByIgnition" SG_ 782 MO_Luftpfad_aktiv 0;
BA_ "GenSigSendType" SG_ 782 MO_Luftpfad_aktiv 0;
BA_ "GenSigSwitchedByIgnition" SG_ 782 MO_v_Begrenz_Aktiv 0;
BA_ "GenSigSendType" SG_ 782 MO_v_Begrenz_Aktiv 0;
BA_ "GenSigSwitchedByIgnition" SG_ 782 MO_v_Begrenz_Aktivierbar 0;
BA_ "GenSigSendType" SG_ 782 MO_v_Begrenz_Aktivierbar 0;
BA_ "GenSigSwitchedByIgnition" SG_ 782 MO_Verbot_EKP 0;
BA_ "GenSigSendType" SG_ 782 MO_Verbot_EKP 0;
BA_ "GenSigSwitchedByIgnition" SG_ 782 MO_Anf_Pruefimpuls 0;
BA_ "GenSigSendType" SG_ 782 MO_Anf_Pruefimpuls 0;
BA_ "GenSigSwitchedByIgnition" SG_ 782 MO_Anf_KL75 0;
BA_ "GenSigStartValue" SG_ 782 MO_Anf_KL75 1;
BA_ "GenSigSendType" SG_ 782 MO_Anf_KL75 0;
BA_ "GenSigSwitchedByIgnition" SG_ 782 MO_Charisma_FahrPr 0;
BA_ "GenSigSendType" SG_ 782 MO_Charisma_FahrPr 0;
BA_ "GenSigSwitchedByIgnition" SG_ 782 MO_Charisma_Status 0;
BA_ "GenSigSendType" SG_ 782 MO_Charisma_Status 0;
BA_ "GenSigSwitchedByIgnition" SG_ 782 MO_Charisma_Umschaltung 0;
BA_ "GenSigSendType" SG_ 782 MO_Charisma_Umschaltung 0;
BA_ "GenSigSwitchedByIgnition" SG_ 782 MO_Handshake_STH 0;
BA_ "GenSigSendType" SG_ 782 MO_Handshake_STH 0;
BA_ "Fehlerwert" SG_ 782 MO_MIN_Wunschdrehzahl 255;
BA_ "GenSigSwitchedByIgnition" SG_ 782 MO_MIN_Wunschdrehzahl 0;
BA_ "GenSigSendType" SG_ 782 MO_MIN_Wunschdrehzahl 0;
BA_ "GenSigSwitchedByIgnition" SG_ 782 MO_Drehzahlbeeinflussung 0;
BA_ "GenSigSendType" SG_ 782 MO_Drehzahlbeeinflussung 0;
BA_ "GenSigSwitchedByIgnition" SG_ 1088 MO_Kuehlerluefter_MUX 0;
BA_ "GenSigSendType" SG_ 1088 MO_Kuehlerluefter_MUX 0;
BA_ "Fehlerwert" SG_ 1088 MO_Kuehlerluefter_1 127;
BA_ "GenSigSwitchedByIgnition" SG_ 1088 MO_Kuehlerluefter_1 0;
BA_ "GenSigStartValue" SG_ 1088 MO_Kuehlerluefter_1 126;
BA_ "Fehlerwert" SG_ 1088 MO_Kuehlerluefter_2 127;
BA_ "GenSigSwitchedByIgnition" SG_ 1088 MO_Kuehlerluefter_2 0;
BA_ "GenSigStartValue" SG_ 1088 MO_Kuehlerluefter_2 126;
BA_ "GenSigSwitchedByIgnition" SG_ 1088 MO_HYB_Status_HV_Ladung 0;
BA_ "GenSigSendType" SG_ 1088 MO_HYB_Status_HV_Ladung 0;
BA_ "GenSigSwitchedByIgnition" SG_ 1088 MO_ITM_Warnung_Pumpe 0;
BA_ "GenSigSendType" SG_ 1088 MO_ITM_Warnung_Pumpe 0;
BA_ "GenSigSwitchedByIgnition" SG_ 1088 WIV_Anzeige_aktiv 0;
BA_ "GenSigSendType" SG_ 1088 WIV_Anzeige_aktiv 0;
BA_ "GenSigSwitchedByIgnition" SG_ 1088 WIV_Oelmin_Warn 0;
BA_ "GenSigSendType" SG_ 1088 WIV_Oelmin_Warn 0;
BA_ "GenSigSwitchedByIgnition" SG_ 1088 WIV_Sensorfehler 0;
BA_ "GenSigSendType" SG_ 1088 WIV_Sensorfehler 0;
BA_ "GenSigSwitchedByIgnition" SG_ 1088 WIV_Schieflage 0;
BA_ "GenSigSendType" SG_ 1088 WIV_Schieflage 0;
BA_ "GenSigSwitchedByIgnition" SG_ 1088 WIV_Oelstand 0;
BA_ "GenSigSendType" SG_ 1088 WIV_Oelstand 0;
BA_ "GenSigSwitchedByIgnition" SG_ 1088 MO_Zustand_HWP 0;
BA_ "GenSigStartValue" SG_ 1088 MO_Zustand_HWP 1;
BA_ "GenSigSendType" SG_ 1088 MO_Zustand_HWP 0;
BA_ "GenSigSwitchedByIgnition" SG_ 1088 MO_Kat_Warnung 0;
BA_ "GenSigSendType" SG_ 1088 MO_Kat_Warnung 0;
BA_ "GenSigSwitchedByIgnition" SG_ 1088 MO_Vorglueh_Lampe 0;
BA_ "GenSigSendType" SG_ 1088 MO_Vorglueh_Lampe 0;
BA_ "GenSigSwitchedByIgnition" SG_ 1088 WIV_Oelsystem_aktiv 0;
BA_ "GenSigSendType" SG_ 1088 WIV_Oelsystem_aktiv 0;
BA_ "GenSigSwitchedByIgnition" SG_ 1088 WIV_nicht_betriebswarm 0;
BA_ "GenSigSendType" SG_ 1088 WIV_nicht_betriebswarm 0;
BA_ "GenSigSwitchedByIgnition" SG_ 1088 WIV_Ueberfuell_Warn 0;
BA_ "GenSigSendType" SG_ 1088 WIV_Ueberfuell_Warn 0;
BA_ "GenSigSwitchedByIgnition" SG_ 1088 WIV_laufender_Motor 0;
BA_ "GenSigSendType" SG_ 1088 WIV_laufender_Motor 0;
BA_ "GenSigSwitchedByIgnition" SG_ 1088 MO_HYB_Text_1 0;
BA_ "GenSigSendType" SG_ 1088 MO_HYB_Text_1 0;
BA_ "GenSigSwitchedByIgnition" SG_ 1088 MO_HYB_Text_2 0;
BA_ "GenSigSendType" SG_ 1088 MO_HYB_Text_2 0;
BA_ "GenSigSwitchedByIgnition" SG_ 1088 MO_HYB_Text_3 0;
BA_ "GenSigSendType" SG_ 1088 MO_HYB_Text_3 0;
BA_ "GenSigSwitchedByIgnition" SG_ 1088 MO_HYB_Text_4 0;
BA_ "GenSigSendType" SG_ 1088 MO_HYB_Text_4 0;
BA_ "GenSigSwitchedByIgnition" SG_ 1088 MO_Text_Motorstart 0;
BA_ "GenSigSendType" SG_ 1088 MO_Text_Motorstart 0;
BA_ "GenSigSwitchedByIgnition" SG_ 1088 MO_HYB_Text_5 0;
BA_ "GenSigSendType" SG_ 1088 MO_HYB_Text_5 0;
BA_ "GenSigSwitchedByIgnition" SG_ 1088 MO_HYB_Text_6 0;
BA_ "GenSigSendType" SG_ 1088 MO_HYB_Text_6 0;
BA_ "GenSigSwitchedByIgnition" SG_ 1088 MO_HYB_Text_7 0;
BA_ "GenSigSendType" SG_ 1088 MO_HYB_Text_7 0;
BA_ "GenSigSwitchedByIgnition" SG_ 1088 WIV_Oeldyn_avl 0;
BA_ "GenSigSendType" SG_ 1088 WIV_Oeldyn_avl 0;
BA_ "GenSigSwitchedByIgnition" SG_ 1088 MO_Text_MSG_Werkstatt 0;
BA_ "GenSigSendType" SG_ 1088 MO_Text_MSG_Werkstatt 0;
BA_ "GenSigSwitchedByIgnition" SG_ 1088 MO_Text_Partikelfil_Reg 0;
BA_ "GenSigSendType" SG_ 1088 MO_Text_Partikelfil_Reg 0;
BA_ "GenSigSwitchedByIgnition" SG_ 1088 MO_Text_Fehler_Kraftstoffsys 0;
BA_ "GenSigSendType" SG_ 1088 MO_Text_Fehler_Kraftstoffsys 0;
BA_ "GenSigSwitchedByIgnition" SG_ 1088 WIV_Oelmenge 0;
BA_ "GenSigSendType" SG_ 1088 WIV_Oelmenge 0;
BA_ "GenSigSwitchedByIgnition" SG_ 1088 MO_Systemlampe 0;
BA_ "GenSigSendType" SG_ 1088 MO_Systemlampe 0;
BA_ "GenSigSwitchedByIgnition" SG_ 1088 MO_OBD2_Lampe 0;
BA_ "GenSigSendType" SG_ 1088 MO_OBD2_Lampe 0;
BA_ "GenSigSwitchedByIgnition" SG_ 1088 MO_Heissleuchte 0;
BA_ "GenSigSendType" SG_ 1088 MO_Heissleuchte 0;
BA_ "GenSigSwitchedByIgnition" SG_ 1088 MO_Partikel_Lampe 0;
BA_ "GenSigSendType" SG_ 1088 MO_Partikel_Lampe 0;
BA_ "GenSigSwitchedByIgnition" SG_ 1088 MO_Winterfahrprog 0;
BA_ "GenSigSendType" SG_ 1088 MO_Winterfahrprog 0;
BA_ "GenSigSwitchedByIgnition" SG_ 1088 WIV_Oelstand_nicht_vorhanden 0;
BA_ "GenSigSendType" SG_ 1088 WIV_Oelstand_nicht_vorhanden 0;
BA_ "GenSigSwitchedByIgnition" SG_ 1088 WIV_nachfuellanzeige_ein 0;
BA_ "GenSigSendType" SG_ 1088 WIV_nachfuellanzeige_ein 0;
BA_ "GenSigSwitchedByIgnition" SG_ 1088 WIV_Ueberfuell_deaktiv 0;
BA_ "GenSigSendType" SG_ 1088 WIV_Ueberfuell_deaktiv 0;
BA_ "GenSigSwitchedByIgnition" SG_ 1088 WIV_Unterfuell_Warn 0;
BA_ "GenSigSendType" SG_ 1088 WIV_Unterfuell_Warn 0;
BA_ "GenSigSwitchedByIgnition" SG_ 1088 MO_Tankdeckel_Lampe 0;
BA_ "GenSigSendType" SG_ 1088 MO_Tankdeckel_Lampe 0;
BA_ "GenSigSwitchedByIgnition" SG_ 1088 MO_Text_Tankdeckelwarn 0;
BA_ "GenSigSendType" SG_ 1088 MO_Text_Tankdeckelwarn 0;
BA_ "GenSigSwitchedByIgnition" SG_ 1088 WIV_Enable_Oeldr_Motor 0;
BA_ "GenSigSendType" SG_ 1088 WIV_Enable_Oeldr_Motor 0;
BA_ "GenSigSwitchedByIgnition" SG_ 1088 WIV_Oeldr_Warn_Motor 0;
BA_ "GenSigSendType" SG_ 1088 WIV_Oeldr_Warn_Motor 0;
BA_ "GenSigSwitchedByIgnition" SG_ 1088 MO_Avus_Motorschutz 0;
BA_ "GenSigSendType" SG_ 1088 MO_Avus_Motorschutz 0;
BA_ "GenSigSwitchedByIgnition" SG_ 1088 MO_HYB_Fahrbereitschaft 0;
BA_ "GenSigSendType" SG_ 1088 MO_HYB_Fahrbereitschaft 0;
BA_ "GenSigSwitchedByIgnition" SG_ 1600 MO_QBit_Ansaugluft_Temp 0;
BA_ "GenSigStartValue" SG_ 1600 MO_QBit_Ansaugluft_Temp 1;
BA_ "GenSigSendType" SG_ 1600 MO_QBit_Ansaugluft_Temp 0;
BA_ "GenSigSwitchedByIgnition" SG_ 1600 MO_QBit_Oel_Temp 0;
BA_ "GenSigStartValue" SG_ 1600 MO_QBit_Oel_Temp 1;
BA_ "GenSigSendType" SG_ 1600 MO_QBit_Oel_Temp 0;
BA_ "GenSigSwitchedByIgnition" SG_ 1600 MO_QBit_Kuehlmittel_Temp 0;
BA_ "GenSigStartValue" SG_ 1600 MO_QBit_Kuehlmittel_Temp 1;
BA_ "GenSigSendType" SG_ 1600 MO_QBit_Kuehlmittel_Temp 0;
BA_ "GenSigSwitchedByIgnition" SG_ 1600 MO_HYB_Fehler_HV_Netz 0;
BA_ "GenSigSendType" SG_ 1600 MO_HYB_Fehler_HV_Netz 0;
BA_ "GenSigSwitchedByIgnition" SG_ 1600 MO_aktives_Getriebeheizen 0;
BA_ "GenSigSendType" SG_ 1600 MO_aktives_Getriebeheizen 0;
BA_ "GenSigSwitchedByIgnition" SG_ 1600 MO_Absperrventil_oeffnen 0;
BA_ "GenSigSendType" SG_ 1600 MO_Absperrventil_oeffnen 0;
BA_ "Fehlerwert" SG_ 1600 MO_Ansaugluft_Temp 255;
BA_ "GenSigSwitchedByIgnition" SG_ 1600 MO_Ansaugluft_Temp 0;
BA_ "GenSigStartValue" SG_ 1600 MO_Ansaugluft_Temp 254;
BA_ "GenSigSendType" SG_ 1600 MO_Ansaugluft_Temp 0;
BA_ "Fehlerwert" SG_ 1600 MO_Oel_Temp 255;
BA_ "GenSigSwitchedByIgnition" SG_ 1600 MO_Oel_Temp 0;
BA_ "GenSigStartValue" SG_ 1600 MO_Oel_Temp 254;
BA_ "GenSigSendType" SG_ 1600 MO_Oel_Temp 0;
BA_ "Fehlerwert" SG_ 1600 MO_Kuehlmittel_Temp 255;
BA_ "GenSigSwitchedByIgnition" SG_ 1600 MO_Kuehlmittel_Temp 0;
BA_ "GenSigStartValue" SG_ 1600 MO_Kuehlmittel_Temp 254;
BA_ "GenSigSendType" SG_ 1600 MO_Kuehlmittel_Temp 0;
BA_ "Fehlerwert" SG_ 1600 MO_Hoeheninfo 255;
BA_ "GenSigSwitchedByIgnition" SG_ 1600 MO_Hoeheninfo 0;
BA_ "GenSigSendType" SG_ 1600 MO_Hoeheninfo 0;
BA_ "GenSigSwitchedByIgnition" SG_ 1600 MO_Kennfeldk 0;
BA_ "GenSigSendType" SG_ 1600 MO_Kennfeldk 0;
BA_ "GenSigSwitchedByIgnition" SG_ 1600 MO_Versionsinfo 0;
BA_ "GenSigFuncType" SG_ 1600 MO_Versionsinfo 8;
BA_ "GenSigSendType" SG_ 1600 MO_Versionsinfo 0;
BA_ "GenSigSwitchedByIgnition" SG_ 1600 MO_Getriebe_kuehlen 0;
BA_ "GenSigSendType" SG_ 1600 MO_Getriebe_kuehlen 0;
BA_ "GenSigSwitchedByIgnition" SG_ 1600 MO_Mom_Traegheit_02 0;
BA_ "GenSigSendType" SG_ 1600 MO_Mom_Traegheit_02 0;
BA_ "Fehlerwert" SG_ 1600 MO_Heizungspumpenansteuerung 13;
BA_ "GenSigSwitchedByIgnition" SG_ 1600 MO_Heizungspumpenansteuerung 0;
BA_ "GenSigStartValue" SG_ 1600 MO_Heizungspumpenansteuerung 14;
BA_ "GenSigSendType" SG_ 1600 MO_Heizungspumpenansteuerung 0;
BA_ "GenSigSwitchedByIgnition" SG_ 1600 MO_SpannungsAnf 0;
BA_ "GenSigSendType" SG_ 1600 MO_SpannungsAnf 0;
BA_ "GenSigSwitchedByIgnition" SG_ 1600 MO_Nachlaufzeit_Heizungspumpe 0;
BA_ "GenSigSendType" SG_ 1600 MO_Nachlaufzeit_Heizungspumpe 0;
BA_ "Fehlerwert" SG_ 1607 MO_ITM_Kuehlmittel_Temp 2;
BA_ "GenSigSwitchedByIgnition" SG_ 1607 MO_ITM_Kuehlmittel_Temp 0;
BA_ "GenSigStartValue" SG_ 1607 MO_ITM_Kuehlmittel_Temp 1;
BA_ "GenSigSendType" SG_ 1607 MO_ITM_Kuehlmittel_Temp 0;
BA_ "Fehlerwert" SG_ 1607 MO_E85_Sensor 15;
BA_ "GenSigSwitchedByIgnition" SG_ 1607 MO_E85_Sensor 0;
BA_ "GenSigStartValue" SG_ 1607 MO_E85_Sensor 14;
BA_ "GenSigSendType" SG_ 1607 MO_E85_Sensor 0;
BA_ "GenSigSwitchedByIgnition" SG_ 1607 SCR_Anz_Motorstarts 0;
BA_ "GenSigStartValue" SG_ 1607 SCR_Anz_Motorstarts 15;
BA_ "GenSigSendType" SG_ 1607 SCR_Anz_Motorstarts 0;
BA_ "GenSigSwitchedByIgnition" SG_ 1607 SCR_Reichweite 0;
BA_ "GenSigStartValue" SG_ 1607 SCR_Reichweite 32767;
BA_ "GenSigSendType" SG_ 1607 SCR_Reichweite 0;
BA_ "GenSigSwitchedByIgnition" SG_ 1607 MO_Ethanol_Spuelhinweis 0;
BA_ "GenSigSendType" SG_ 1607 MO_Ethanol_Spuelhinweis 0;
BA_ "GenSigSwitchedByIgnition" SG_ 1607 SCR_Warnstufe_1 0;
BA_ "GenSigSendType" SG_ 1607 SCR_Warnstufe_1 0;
BA_ "GenSigSwitchedByIgnition" SG_ 1607 SCR_Warnstufe_2 0;
BA_ "GenSigSendType" SG_ 1607 SCR_Warnstufe_2 0;
BA_ "GenSigSwitchedByIgnition" SG_ 1607 SCR_Text 0;
BA_ "GenSigSendType" SG_ 1607 SCR_Text 0;
BA_ "GenSigSwitchedByIgnition" SG_ 1607 SCR_Akustik 0;
BA_ "GenSigSendType" SG_ 1607 SCR_Akustik 0;
BA_ "GenSigSwitchedByIgnition" SG_ 1607 SCR_verbaut 0;
BA_ "GenSigFuncType" SG_ 1607 SCR_verbaut 8;
BA_ "GenSigSendType" SG_ 1607 SCR_verbaut 0;
BA_ "GenSigSwitchedByIgnition" SG_ 1607 MO_Kraftstofffilter_Wasser 0;
BA_ "GenSigSendType" SG_ 1607 MO_Kraftstofffilter_Wasser 0;
BA_ "GenSigSwitchedByIgnition" SG_ 1607 SCR_Systemfehler 0;
BA_ "GenSigSendType" SG_ 1607 SCR_Systemfehler 0;
BA_ "GenSigSwitchedByIgnition" SG_ 1607 SCR_Inducement_Strategie 0;
BA_ "GenSigSendType" SG_ 1607 SCR_Inducement_Strategie 0;
BA_ "Fehlerwert" SG_ 1607 MO_CO2_Faktor 4095;
BA_ "GenSigSwitchedByIgnition" SG_ 1607 MO_CO2_Faktor 0;
BA_ "GenSigSendType" SG_ 1607 MO_CO2_Faktor 0;
BA_ "GenSigSwitchedByIgnition" SG_ 1607 MO_MKB_MUX 0;
BA_ "GenSigSendType" SG_ 1607 MO_MKB_MUX 0;
BA_ "GenSigSwitchedByIgnition" SG_ 1607 MO_MKB_01 0;
BA_ "GenSigFuncType" SG_ 1607 MO_MKB_01 8;
BA_ "GenSigSwitchedByIgnition" SG_ 1607 MO_MKB_02 0;
BA_ "GenSigFuncType" SG_ 1607 MO_MKB_02 8;
BA_ "GenSigSwitchedByIgnition" SG_ 1607 MO_MKB_03 0;
BA_ "GenSigFuncType" SG_ 1607 MO_MKB_03 8;
BA_ "GenSigSwitchedByIgnition" SG_ 1607 MO_MKB_04 0;
BA_ "GenSigFuncType" SG_ 1607 MO_MKB_04 8;
BA_ "GenSigSwitchedByIgnition" SG_ 276 Motor_10_CHK 0;
BA_ "GenSigFuncType" SG_ 276 Motor_10_CHK 3;
BA_ "GenSigSendType" SG_ 276 Motor_10_CHK 0;
BA_ "GenSigSwitchedByIgnition" SG_ 276 Motor_10_BZ 0;
BA_ "GenSigFuncType" SG_ 276 Motor_10_BZ 1;
BA_ "GenSigSendType" SG_ 276 Motor_10_BZ 0;
BA_ "GenSigSwitchedByIgnition" SG_ 276 MO_Sig_Fahrpedalgradient 0;
BA_ "GenSigSendType" SG_ 276 MO_Sig_Fahrpedalgradient 0;
BA_ "GenSigSwitchedByIgnition" SG_ 276 MO_BKV_Unterdruckwarnung 0;
BA_ "GenSigSendType" SG_ 276 MO_BKV_Unterdruckwarnung 0;
BA_ "GenSigSwitchedByIgnition" SG_ 276 MO_Zylinderabschaltung 0;
BA_ "GenSigSendType" SG_ 276 MO_Zylinderabschaltung 0;
BA_ "Fehlerwert" SG_ 276 MO_Fahrpedalgradient 255;
BA_ "GenSigSwitchedByIgnition" SG_ 276 MO_Fahrpedalgradient 0;
BA_ "GenSigSendType" SG_ 276 MO_Fahrpedalgradient 0;
BA_ "GenSigSwitchedByIgnition" SG_ 276 MO_Schubabschaltung 0;
BA_ "GenSigSendType" SG_ 276 MO_Schubabschaltung 0;
BA_ "Fehlerwert" SG_ 276 MO_rel_Saugrohrdruck 63;
BA_ "GenSigSwitchedByIgnition" SG_ 276 MO_rel_Saugrohrdruck 0;
BA_ "GenSigSendType" SG_ 276 MO_rel_Saugrohrdruck 0;
BA_ "GenSigSwitchedByIgnition" SG_ 276 MO_rel_Saugrohrdruck_gem_err 0;
BA_ "GenSigSendType" SG_ 276 MO_rel_Saugrohrdruck_gem_err 0;
BA_ "Fehlerwert" SG_ 276 MO_BKV_Unterdruck 255;
BA_ "GenSigSwitchedByIgnition" SG_ 276 MO_BKV_Unterdruck 0;
BA_ "GenSigStartValue" SG_ 276 MO_BKV_Unterdruck 254;
BA_ "GenSigSendType" SG_ 276 MO_BKV_Unterdruck 0;
BA_ "Fehlerwert" SG_ 276 MO_Bremspedalweg 255;
BA_ "GenSigSwitchedByIgnition" SG_ 276 MO_Bremspedalweg 0;
BA_ "GenSigSendType" SG_ 276 MO_Bremspedalweg 0;
BA_ "Fehlerwert" SG_ 276 MO_Mom_Traegheit_Summe 1023;
BA_ "GenSigSwitchedByIgnition" SG_ 276 MO_Mom_Traegheit_Summe 0;
BA_ "GenSigStartValue" SG_ 276 MO_Mom_Traegheit_Summe 1022;
BA_ "GenSigSendType" SG_ 276 MO_Mom_Traegheit_Summe 0;
BA_ "GenSigSwitchedByIgnition" SG_ 276 MO_ANC_Kennfeld_Anf 0;
BA_ "GenSigSendType" SG_ 276 MO_ANC_Kennfeld_Anf 0;
BA_ "GenSigSwitchedByIgnition" SG_ 168 Motor_12_CRC 0;
BA_ "GenSigFuncType" SG_ 168 Motor_12_CRC 2;
BA_ "GenSigSendType" SG_ 168 Motor_12_CRC 0;
BA_ "GenSigSwitchedByIgnition" SG_ 168 Motor_12_BZ 0;
BA_ "GenSigFuncType" SG_ 168 Motor_12_BZ 1;
BA_ "GenSigSendType" SG_ 168 Motor_12_BZ 0;
BA_ "Fehlerwert" SG_ 168 MO_Mom_neg_verfuegbar 1023;
BA_ "GenSigSwitchedByIgnition" SG_ 168 MO_Mom_neg_verfuegbar 0;
BA_ "GenSigStartValue" SG_ 168 MO_Mom_neg_verfuegbar 510;
BA_ "GenSigSendType" SG_ 168 MO_Mom_neg_verfuegbar 0;
BA_ "Fehlerwert" SG_ 168 MO_Mom_Begr_stat 1023;
BA_ "GenSigSwitchedByIgnition" SG_ 168 MO_Mom_Begr_stat 0;
BA_ "GenSigStartValue" SG_ 168 MO_Mom_Begr_stat 510;
BA_ "GenSigSendType" SG_ 168 MO_Mom_Begr_stat 0;
BA_ "Fehlerwert" SG_ 168 MO_Mom_Begr_dyn 1023;
BA_ "GenSigSwitchedByIgnition" SG_ 168 MO_Mom_Begr_dyn 0;
BA_ "GenSigStartValue" SG_ 168 MO_Mom_Begr_dyn 1022;
BA_ "GenSigSendType" SG_ 168 MO_Mom_Begr_dyn 0;
BA_ "GenSigSwitchedByIgnition" SG_ 168 MO_Momentenintegral_02 0;
BA_ "GenSigSendType" SG_ 168 MO_Momentenintegral_02 0;
BA_ "GenSigSwitchedByIgnition" SG_ 168 MO_QBit_Drehzahl_01 0;
BA_ "GenSigStartValue" SG_ 168 MO_QBit_Drehzahl_01 1;
BA_ "GenSigSendType" SG_ 168 MO_QBit_Drehzahl_01 0;
BA_ "Fehlerwert" SG_ 168 MO_Drehzahl_01 65535;
BA_ "GenSigSwitchedByIgnition" SG_ 168 MO_Drehzahl_01 0;
BA_ "GenSigSendType" SG_ 168 MO_Drehzahl_01 0;
BA_ "GenSigSwitchedByIgnition" SG_ 1648 MO_max_Ladedruck 0;
BA_ "GenSigFuncType" SG_ 1648 MO_max_Ladedruck 8;
BA_ "GenSigSendType" SG_ 1648 MO_max_Ladedruck 0;
BA_ "GenSigSwitchedByIgnition" SG_ 1648 MO_ANC_Kennfeld_Anf 0;
BA_ "GenSigSendType" SG_ 1648 MO_ANC_Kennfeld_Anf 3;
BA_ "GenSigSwitchedByIgnition" SG_ 1648 MO_Bremslicht_Reku 0;
BA_ "GenSigSendType" SG_ 1648 MO_Bremslicht_Reku 3;
BA_ "GenSigSwitchedByIgnition" SG_ 1648 MO_StartStopp_PopUp 0;
BA_ "GenSigSendType" SG_ 1648 MO_StartStopp_PopUp 0;
BA_ "GenSigSwitchedByIgnition" SG_ 1648 MO_EPCL 0;
BA_ "GenSigSendType" SG_ 1648 MO_EPCL 0;
BA_ "GenSigSwitchedByIgnition" SG_ 1648 MO_Zylabsch_Texte_02 0;
BA_ "GenSigSendType" SG_ 1648 MO_Zylabsch_Texte_02 3;
BA_ "GenSigSwitchedByIgnition" SG_ 1648 MO_Fahrzeugtyp 0;
BA_ "GenSigFuncType" SG_ 1648 MO_Fahrzeugtyp 8;
BA_ "GenSigSendType" SG_ 1648 MO_Fahrzeugtyp 0;
BA_ "GenSigSwitchedByIgnition" SG_ 1648 MO_NMAX_Schaltanzeige 0;
BA_ "GenSigSendType" SG_ 1648 MO_NMAX_Schaltanzeige 3;
BA_ "Fehlerwert" SG_ 1648 MO_Abstellzeit 255;
BA_ "GenSigSwitchedByIgnition" SG_ 1648 MO_Abstellzeit 0;
BA_ "GenSigStartValue" SG_ 1648 MO_Abstellzeit 254;
BA_ "GenSigSendType" SG_ 1648 MO_Abstellzeit 0;
BA_ "GenSigSwitchedByIgnition" SG_ 1648 MO_Abstellzeit_Status 0;
BA_ "GenSigSendType" SG_ 1648 MO_Abstellzeit_Status 0;
BA_ "GenSigSwitchedByIgnition" SG_ 1648 MO_Hybrid_StartStopp_LED 0;
BA_ "GenSigSendType" SG_ 1648 MO_Hybrid_StartStopp_LED 3;
BA_ "GenSigSwitchedByIgnition" SG_ 1648 MO_Fehler_Zylabsch 0;
BA_ "GenSigSendType" SG_ 1648 MO_Fehler_Zylabsch 3;
BA_ "GenSigSwitchedByIgnition" SG_ 1648 MO_Anzahl_Abgesch_Zyl 0;
BA_ "GenSigSendType" SG_ 1648 MO_Anzahl_Abgesch_Zyl 3;
BA_ "GenSigSwitchedByIgnition" SG_ 1648 MO_Zylabsch_Texte 0;
BA_ "GenSigSendType" SG_ 1648 MO_Zylabsch_Texte 0;
BA_ "GenSigSwitchedByIgnition" SG_ 1648 MO_Ethanol_BS_Texte 0;
BA_ "GenSigSendType" SG_ 1648 MO_Ethanol_BS_Texte 0;
BA_ "GenSigSwitchedByIgnition" SG_ 1648 MO_Drehzahl_Warnung 0;
BA_ "GenSigSendType" SG_ 1648 MO_Drehzahl_Warnung 0;
BA_ "GenSigSwitchedByIgnition" SG_ 1648 MO_obere_Drehzahlgrenze 0;
BA_ "GenSigSendType" SG_ 1648 MO_obere_Drehzahlgrenze 0;
BA_ "GenSigSwitchedByIgnition" SG_ 1010 Motor_19_BZ 0;
BA_ "GenSigFuncType" SG_ 1010 Motor_19_BZ 1;
BA_ "GenSigSendType" SG_ 1010 Motor_19_BZ 0;
BA_ "Fehlerwert" SG_ 1010 MO_SCR_Tankheizkreis_Leistung 255;
BA_ "GenSigSwitchedByIgnition" SG_ 1010 MO_SCR_Tankheizkreis_Leistung 0;
BA_ "GenSigStartValue" SG_ 1010 MO_SCR_Tankheizkreis_Leistung 254;
BA_ "GenSigSendType" SG_ 1010 MO_SCR_Tankheizkreis_Leistung 0;
BA_ "GenSigSwitchedByIgnition" SG_ 1010 MO_SCR_Heizkreis_3 0;
BA_ "GenSigSendType" SG_ 1010 MO_SCR_Heizkreis_3 0;
BA_ "GenSigSwitchedByIgnition" SG_ 1010 MO_SCR_Tankheizung 0;
BA_ "GenSigSendType" SG_ 1010 MO_SCR_Tankheizung 0;
BA_ "GenSigSwitchedByIgnition" SG_ 1010 MO_SCR_Dosierpumpe_Zustand 0;
BA_ "GenSigSendType" SG_ 1010 MO_SCR_Dosierpumpe_Zustand 0;
BA_ "GenSigSwitchedByIgnition" SG_ 1010 MO_SCR_Leitungsheizung 0;
BA_ "GenSigSendType" SG_ 1010 MO_SCR_Leitungsheizung 0;
BA_ "Fehlerwert" SG_ 1010 MO_SCR_Dosierpumpe_Wartezeit 127;
BA_ "GenSigSwitchedByIgnition" SG_ 1010 MO_SCR_Dosierpumpe_Wartezeit 0;
BA_ "GenSigStartValue" SG_ 1010 MO_SCR_Dosierpumpe_Wartezeit 126;
BA_ "GenSigSendType" SG_ 1010 MO_SCR_Dosierpumpe_Wartezeit 0;
BA_ "GenSigSwitchedByIgnition" SG_ 1010 MO_SCR_Transferpumpe 0;
BA_ "GenSigSendType" SG_ 1010 MO_SCR_Transferpumpe 0;
BA_ "GenSigSwitchedByIgnition" SG_ 1010 MO_SCR_Dosierpumpe_Soll 0;
BA_ "GenSigSendType" SG_ 1010 MO_SCR_Dosierpumpe_Soll 0;
BA_ "GenSigSwitchedByIgnition" SG_ 815 MO_Antriebsstrang_Warnung_HS 0;
BA_ "GenSigSendType" SG_ 815 MO_Antriebsstrang_Warnung_HS 0;
BA_ "GenSigSwitchedByIgnition" SG_ 815 MO_Anzeige_Verbrauch 0;
BA_ "GenSigSendType" SG_ 815 MO_Anzeige_Verbrauch 0;
BA_ "Fehlerwert" SG_ 1391 MO_IstLeistung_EKAT 127;
BA_ "GenSigSwitchedByIgnition" SG_ 1391 MO_IstLeistung_EKAT 0;
BA_ "GenSigStartValue" SG_ 1391 MO_IstLeistung_EKAT 126;
BA_ "GenSigSendType" SG_ 1391 MO_IstLeistung_EKAT 0;
BA_ "Fehlerwert" SG_ 1391 MO_HYB_Drehzahl_VM 65280;
BA_ "GenSigSwitchedByIgnition" SG_ 1391 MO_HYB_Drehzahl_VM 0;
BA_ "GenSigSendType" SG_ 1391 MO_HYB_Drehzahl_VM 0;
BA_ "GenSigSwitchedByIgnition" SG_ 191 Motor_27_CRC 0;
BA_ "GenSigFuncType" SG_ 191 Motor_27_CRC 2;
BA_ "GenSigSendType" SG_ 191 Motor_27_CRC 0;
BA_ "GenSigSwitchedByIgnition" SG_ 191 Motor_27_BZ 0;
BA_ "GenSigFuncType" SG_ 191 Motor_27_BZ 1;
BA_ "GenSigSendType" SG_ 191 Motor_27_BZ 0;
BA_ "GenSigSwitchedByIgnition" SG_ 191 MO_Mom_dyn_Diff 0;
BA_ "GenSigStartValue" SG_ 191 MO_Mom_dyn_Diff 255;
BA_ "GenSigSendType" SG_ 191 MO_Mom_dyn_Diff 0;
BA_ "GenSigSwitchedByIgnition" SG_ 1014 MO_Tankklappensteuerung 0;
BA_ "GenSigSendType" SG_ 1014 MO_Tankklappensteuerung 0;
BA_ "GenSigSwitchedByIgnition" SG_ 1014 MO_Kl_50 0;
BA_ "GenSigSendType" SG_ 1014 MO_Kl_50 3;
BA_ "GenSigSwitchedByIgnition" SG_ 1014 MO_Freigabe_Segeln 0;
BA_ "GenSigSendType" SG_ 1014 MO_Freigabe_Segeln 0;
BA_ "GenSigSwitchedByIgnition" SG_ 1601 Motor_Code_01_CHK 0;
BA_ "GenSigFuncType" SG_ 1601 Motor_Code_01_CHK 3;
BA_ "GenSigSendType" SG_ 1601 Motor_Code_01_CHK 0;
BA_ "GenSigSwitchedByIgnition" SG_ 1601 Motor_Code_01_BZ 0;
BA_ "GenSigFuncType" SG_ 1601 Motor_Code_01_BZ 1;
BA_ "GenSigSendType" SG_ 1601 Motor_Code_01_BZ 0;
BA_ "GenSigSwitchedByIgnition" SG_ 1601 MO_Faktor_Momente 0;
BA_ "GenSigFuncType" SG_ 1601 MO_Faktor_Momente 8;
BA_ "GenSigSendType" SG_ 1601 MO_Faktor_Momente 0;
BA_ "GenSigSwitchedByIgnition" SG_ 1601 MO_Hybridfahrzeug 0;
BA_ "GenSigFuncType" SG_ 1601 MO_Hybridfahrzeug 8;
BA_ "GenSigSendType" SG_ 1601 MO_Hybridfahrzeug 0;
BA_ "GenSigSwitchedByIgnition" SG_ 1601 MO_Code 0;
BA_ "GenSigFuncType" SG_ 1601 MO_Code 8;
BA_ "GenSigSendType" SG_ 1601 MO_Code 0;
BA_ "GenSigSwitchedByIgnition" SG_ 1601 MO_Getriebe_Code 0;
BA_ "GenSigFuncType" SG_ 1601 MO_Getriebe_Code 8;
BA_ "GenSigSendType" SG_ 1601 MO_Getriebe_Code 0;
BA_ "GenSigSwitchedByIgnition" SG_ 1601 MO_StartStopp_Codiert 0;
BA_ "GenSigFuncType" SG_ 1601 MO_StartStopp_Codiert 8;
BA_ "GenSigSendType" SG_ 1601 MO_StartStopp_Codiert 0;
BA_ "GenSigSwitchedByIgnition" SG_ 1601 MO_Anzahl_Zyl 0;
BA_ "GenSigFuncType" SG_ 1601 MO_Anzahl_Zyl 8;
BA_ "GenSigSendType" SG_ 1601 MO_Anzahl_Zyl 0;
BA_ "GenSigSwitchedByIgnition" SG_ 1601 MO_Kraftstoffart 0;
BA_ "GenSigFuncType" SG_ 1601 MO_Kraftstoffart 8;
BA_ "GenSigSendType" SG_ 1601 MO_Kraftstoffart 0;
BA_ "GenSigSwitchedByIgnition" SG_ 1601 MO_Hubraum 0;
BA_ "GenSigFuncType" SG_ 1601 MO_Hubraum 8;
BA_ "GenSigSendType" SG_ 1601 MO_Hubraum 0;
BA_ "GenSigSwitchedByIgnition" SG_ 1601 MO_Ansaugsystem 0;
BA_ "GenSigFuncType" SG_ 1601 MO_Ansaugsystem 8;
BA_ "GenSigSendType" SG_ 1601 MO_Ansaugsystem 0;
BA_ "GenSigSwitchedByIgnition" SG_ 1601 MO_Leistung 0;
BA_ "GenSigFuncType" SG_ 1601 MO_Leistung 8;
BA_ "GenSigSendType" SG_ 1601 MO_Leistung 0;
BA_ "GenSigSwitchedByIgnition" SG_ 1601 MO_Abgastyp 0;
BA_ "GenSigFuncType" SG_ 1601 MO_Abgastyp 8;
BA_ "GenSigSendType" SG_ 1601 MO_Abgastyp 0;
BA_ "GenSigSwitchedByIgnition" SG_ 1601 MO_Einspritzart 0;
BA_ "GenSigFuncType" SG_ 1601 MO_Einspritzart 8;
BA_ "GenSigSendType" SG_ 1601 MO_Einspritzart 0;
BA_ "GenSigSwitchedByIgnition" SG_ 305 MO_ePowermeter 0;
BA_ "GenSigSendType" SG_ 305 MO_ePowermeter 0;
BA_ "GenSigSwitchedByIgnition" SG_ 305 MO_Zust_Antrieb 0;
BA_ "GenSigSendType" SG_ 305 MO_Zust_Antrieb 0;
BA_ "GenSigSwitchedByIgnition" SG_ 305 MO_Zust_Betriebsstrategie 0;
BA_ "GenSigSendType" SG_ 305 MO_Zust_Betriebsstrategie 0;
BA_ "GenSigSwitchedByIgnition" SG_ 305 MO_W_Reku_normiert_ueberlauf 0;
BA_ "GenSigSendType" SG_ 305 MO_W_Reku_normiert_ueberlauf 0;
BA_ "Fehlerwert" SG_ 305 Ladezustand 255;
BA_ "GenSigSwitchedByIgnition" SG_ 305 Ladezustand 0;
BA_ "GenSigSendType" SG_ 305 Ladezustand 0;
BA_ "Fehlerwert" SG_ 305 Enrgfluss_State 255;
BA_ "GenSigSwitchedByIgnition" SG_ 305 Enrgfluss_State 0;
BA_ "GenSigSendType" SG_ 305 Enrgfluss_State 0;
BA_ "GenSigSwitchedByIgnition" SG_ 305 MO_W_Reku_normiert 0;
BA_ "GenSigSendType" SG_ 305 MO_W_Reku_normiert 0;
BA_ "GenSigSwitchedByIgnition" SG_ 305 MO_Powermeter 0;
BA_ "GenSigStartValue" SG_ 305 MO_Powermeter 4093;
BA_ "GenSigSendType" SG_ 305 MO_Powermeter 0;
BA_ "GenSigSwitchedByIgnition" SG_ 1376 Motor_Hybrid_04_CRC 0;
BA_ "GenSigFuncType" SG_ 1376 Motor_Hybrid_04_CRC 2;
BA_ "GenSigSendType" SG_ 1376 Motor_Hybrid_04_CRC 0;
BA_ "GenSigSwitchedByIgnition" SG_ 1376 Motor_Hybrid_04_BZ 0;
BA_ "GenSigFuncType" SG_ 1376 Motor_Hybrid_04_BZ 1;
BA_ "GenSigSendType" SG_ 1376 Motor_Hybrid_04_BZ 0;
BA_ "GenSigSwitchedByIgnition" SG_ 1376 MO_HV_Spannungsfreiheit 0;
BA_ "GenSigSendType" SG_ 1376 MO_HV_Spannungsfreiheit 0;
BA_ "GenSigSwitchedByIgnition" SG_ 1376 MO_Reku_Leistung 0;
BA_ "GenSigSendType" SG_ 1376 MO_Reku_Leistung 0;
BA_ "GenSigSwitchedByIgnition" SG_ 1376 Mo_Powermeter_Grenze 0;
BA_ "GenSigStartValue" SG_ 1376 Mo_Powermeter_Grenze 4093;
BA_ "GenSigSendType" SG_ 1376 Mo_Powermeter_Grenze 0;
BA_ "Fehlerwert" SG_ 1376 MO_Gesamtst_Spgfreiheit 3;
BA_ "GenSigSwitchedByIgnition" SG_ 1376 MO_Gesamtst_Spgfreiheit 0;
BA_ "GenSigSendType" SG_ 1376 MO_Gesamtst_Spgfreiheit 0;
BA_ "GenSigSwitchedByIgnition" SG_ 1376 MO_Tankbereitschaft_Status 0;
BA_ "GenSigSendType" SG_ 1376 MO_Tankbereitschaft_Status 0;
BA_ "Fehlerwert" SG_ 1376 MO_Energieinhalt_BMS 4095;
BA_ "GenSigSwitchedByIgnition" SG_ 1376 MO_Energieinhalt_BMS 0;
BA_ "GenSigStartValue" SG_ 1376 MO_Energieinhalt_BMS 4094;
BA_ "GenSigSendType" SG_ 1376 MO_Energieinhalt_BMS 0;
BA_ "GenSigSwitchedByIgnition" SG_ 1376 MO_HYB_Status_Betriebsstrategie 0;
BA_ "GenSigSendType" SG_ 1376 MO_HYB_Status_Betriebsstrategie 0;
BA_ "GenSigSwitchedByIgnition" SG_ 1376 MO_Boost_aktiv 0;
BA_ "GenSigSendType" SG_ 1376 MO_Boost_aktiv 0;
BA_ "GenSigSwitchedByIgnition" SG_ 969 MOS_KD_Fehler 0;
BA_ "GenSigSendType" SG_ 969 MOS_KD_Fehler 0;
BA_ "GenSigSendType" SG_ 1696 NV_aktiv 3;
BA_ "GenSigSendType" SG_ 1696 NV_Texte 3;
BA_ "GenSigSendType" SG_ 1696 NV_Gong 3;
BA_ "GenSigSendType" SG_ 1696 NV_Symbol 3;
BA_ "GenSigSendType" SG_ 1696 NV_Hinweise 3;
BA_ "GenSigSendType" SG_ 1696 NV_Piktogramm_aktiv 3;
BA_ "GenSigSendType" SG_ 1696 NV_Akustik_deaktiviert_Icon 3;
BA_ "GenSigSendType" SG_ 1696 NV_FGM_deaktiviert_Icon 3;
BA_ "GenSigSendType" SG_ 1696 NV_Markierungslicht_links 3;
BA_ "GenSigSendType" SG_ 1696 NV_Markierungslicht_rechts 3;
BA_ "GenSigSendType" SG_ 1696 NV_Symbol_Tierwarnung 3;
BA_ "GenSigSwitchedByIgnition" SG_ 1696 NV_Anf_Prefill 0;
BA_ "GenSigSendType" SG_ 1696 NV_Anf_Prefill 3;
BA_ "GenSigSendType" SG_ 1696 NV_HBA_Parameter 3;
BA_ "GenSigSendType" SG_ 1696 NV_KD_Fehler 0;
BA_ "GenSigSwitchedByIgnition" SG_ 1742 NMH_BMS_Start_1 0;
BA_ "GenSigSwitchedByIgnition" SG_ 1742 NMH_BMS_Start_2 0;
BA_ "GenSigSwitchedByIgnition" SG_ 1742 NMH_BMS_Normal_Mode_1 0;
BA_ "GenSigSwitchedByIgnition" SG_ 1742 NMH_BMS_Normal_Mode_2 0;
BA_ "GenSigSwitchedByIgnition" SG_ 1742 NMH_BMS_Car_WakeUp 0;
BA_ "GenSigSwitchedByIgnition" SG_ 1742 NMH_BMS_Per_WakeUp 0;
BA_ "NWM-WakeupAllowed" SG_ 1742 NMH_BMS_Per_WakeUp 1;
BA_ "GenSigSwitchedByIgnition" SG_ 1742 NMH_BMS_Fkt_WakeUp 0;
BA_ "NWM-WakeupAllowed" SG_ 1742 NMH_BMS_Fkt_WakeUp 1;
BA_ "GenSigSwitchedByIgnition" SG_ 1742 NMH_BMS_Klemme_15 0;
BA_ "GenSigSwitchedByIgnition" SG_ 1742 NMH_BMS_Diagnose 0;
BA_ "GenSigSwitchedByIgnition" SG_ 1742 NMH_BMS_MindestAktivZeit 0;
BA_ "GenSigSwitchedByIgnition" SG_ 1742 NMH_BMS_NL_Daten_EEPROM 0;
BA_ "GenSigSwitchedByIgnition" SG_ 1742 NMH_BMS_NL_Luefter 0;
BA_ "GenSigSwitchedByIgnition" SG_ 1742 NMH_BMS_Signalfehler 0;
BA_ "GenSigSwitchedByIgnition" SG_ 1742 NMH_BMS_TimeOut_Fehler 0;
BA_ "GenSigSwitchedByIgnition" SG_ 1742 NMH_BMS_CAN_Diag_deaktiv 0;
BA_ "GenSigSwitchedByIgnition" SG_ 1742 NMH_BMS_KompSchutz 0;
BA_ "GenSigSwitchedByIgnition" SG_ 1742 NMH_BMS_Mute_Mode 0;
BA_ "GenSigSwitchedByIgnition" SG_ 1742 NMH_BMS_Transport_Mode 0;
BA_ "GenSigSwitchedByIgnition" SG_ 1742 NMH_BMS_Abschaltstufe_aktiv 0;
BA_ "GenSigSwitchedByIgnition" SG_ 1742 NMH_BMS_Busfehler 0;
BA_ "GenSigSwitchedByIgnition" SG_ 1742 NMH_BMS_Lokalaktiv 0;
BA_ "GenSigSwitchedByIgnition" SG_ 1742 NMH_BMS_Subsystemaktiv 0;
BA_ "GenSigSwitchedByIgnition" SG_ 1743 NMH_EM_Start_1 0;
BA_ "GenSigSwitchedByIgnition" SG_ 1743 NMH_EM_Start_2 0;
BA_ "GenSigSwitchedByIgnition" SG_ 1743 NMH_EM_Normal_Mode_1 0;
BA_ "GenSigSwitchedByIgnition" SG_ 1743 NMH_EM_Normal_Mode_2 0;
BA_ "GenSigSwitchedByIgnition" SG_ 1743 NMH_EM_Car_WakeUp 0;
BA_ "GenSigSwitchedByIgnition" SG_ 1743 NMH_EM_Per_WakeUp 0;
BA_ "NWM-WakeupAllowed" SG_ 1743 NMH_EM_Per_WakeUp 1;
BA_ "GenSigSwitchedByIgnition" SG_ 1743 NMH_EM_Fkt_WakeUp 0;
BA_ "NWM-WakeupAllowed" SG_ 1743 NMH_EM_Fkt_WakeUp 1;
BA_ "GenSigSwitchedByIgnition" SG_ 1743 NMH_EM_Klemme_15 0;
BA_ "GenSigSwitchedByIgnition" SG_ 1743 NMH_EM_Diagnose 0;
BA_ "GenSigSwitchedByIgnition" SG_ 1743 NMH_EM_MindestAktivZeit 0;
BA_ "GenSigSwitchedByIgnition" SG_ 1743 NMH_EM_keine_HV_Entl 0;
BA_ "GenSigSwitchedByIgnition" SG_ 1743 NMH_EM_NL_Datem_EEPROM 0;
BA_ "GenSigSwitchedByIgnition" SG_ 1743 NMH_EM_Signalfehler 0;
BA_ "GenSigSwitchedByIgnition" SG_ 1743 NMH_EM_TimeOut_Fehler 0;
BA_ "GenSigSwitchedByIgnition" SG_ 1743 NMH_EM_CAN_Diag_deaktiv 0;
BA_ "GenSigSwitchedByIgnition" SG_ 1743 NMH_EM_KompSchutz 0;
BA_ "GenSigSwitchedByIgnition" SG_ 1743 NMH_EM_Mute_Mode 0;
BA_ "GenSigSwitchedByIgnition" SG_ 1743 NMH_EM_Transport_Mode 0;
BA_ "GenSigSwitchedByIgnition" SG_ 1743 NMH_EM_Abschaltstufe_aktiv 0;
BA_ "GenSigSwitchedByIgnition" SG_ 1743 NMH_EM_Busfehler 0;
BA_ "GenSigSwitchedByIgnition" SG_ 1743 NMH_EM_Lokalaktiv 0;
BA_ "GenSigSwitchedByIgnition" SG_ 1743 NMH_EM_Subsystemaktiv 0;
BA_ "GenSigSwitchedByIgnition" SG_ 1753 NMH_EPB_Start_1 0;
BA_ "GenSigSwitchedByIgnition" SG_ 1753 NMH_EPB_Start_2 0;
BA_ "GenSigSwitchedByIgnition" SG_ 1753 NMH_EPB_Normal_Mode_1 0;
BA_ "GenSigSwitchedByIgnition" SG_ 1753 NMH_EPB_Normal_Mode_2 0;
BA_ "GenSigSwitchedByIgnition" SG_ 1753 NMH_EPB_Car_WakeUp 0;
BA_ "GenSigSwitchedByIgnition" SG_ 1753 NMH_EPB_Per_WakeUp 0;
BA_ "NWM-WakeupAllowed" SG_ 1753 NMH_EPB_Per_WakeUp 1;
BA_ "GenSigSwitchedByIgnition" SG_ 1753 NMH_EPB_Fkt_WakeUp 0;
BA_ "NWM-WakeupAllowed" SG_ 1753 NMH_EPB_Fkt_WakeUp 1;
BA_ "GenSigSwitchedByIgnition" SG_ 1753 NMH_EPB_NM_aktiv_Klemme_15 0;
BA_ "GenSigSwitchedByIgnition" SG_ 1753 NMH_EPB_NM_aktiv_Diagnose 0;
BA_ "GenSigSwitchedByIgnition" SG_ 1753 NMH_EPB_NM_aktiv_Start 0;
BA_ "GenSigSwitchedByIgnition" SG_ 1753 NMH_EPB_NM_aktiv_Schalter 0;
BA_ "GenSigSwitchedByIgnition" SG_ 1753 NMH_EPB_NM_aktiv_Bedarf_Anzeige 0;
BA_ "GenSigSwitchedByIgnition" SG_ 1753 NMH_EPB_NM_aktiv_v_groesser_Null 0;
BA_ "GenSigSwitchedByIgnition" SG_ 1753 NMH_EPB_AutoAdjust 0;
BA_ "GenSigSwitchedByIgnition" SG_ 1753 NMH_EPB_kein_NL 0;
BA_ "GenSigSwitchedByIgnition" SG_ 1753 NMH_EPB_NL_Temp_Modell 0;
BA_ "GenSigSwitchedByIgnition" SG_ 1753 NMH_EPB_NL_Min 0;
BA_ "GenSigSwitchedByIgnition" SG_ 1753 NM_EPB_Signalfehler 0;
BA_ "GenSigSwitchedByIgnition" SG_ 1753 NMH_EPB_TimeOut_Fehler 0;
BA_ "GenSigSwitchedByIgnition" SG_ 1753 NMH_EPB_CAN_Diag_deaktiv 0;
BA_ "GenSigSwitchedByIgnition" SG_ 1753 NMH_EPB_KompSchutz 0;
BA_ "GenSigSwitchedByIgnition" SG_ 1753 NMH_EPB_Mute_Mode 0;
BA_ "GenSigSwitchedByIgnition" SG_ 1753 NMH_EPB_Transport_Mode 0;
BA_ "GenSigSwitchedByIgnition" SG_ 1753 NMH_EPB_Abschaltstufe_aktiv 0;
BA_ "GenSigSwitchedByIgnition" SG_ 1753 NMH_EPB_Eindraht_Fehler 0;
BA_ "GenSigSwitchedByIgnition" SG_ 1753 NMH_EPB_Lokalaktiv 0;
BA_ "GenSigSwitchedByIgnition" SG_ 1753 NMH_EPB_Subsystemaktiv 0;
BA_ "GenSigSwitchedByIgnition" SG_ 1728 NMH_GW_Start_1 0;
BA_ "GenSigStartValue" SG_ 1728 NMH_GW_Start_1 1;
BA_ "GenSigSwitchedByIgnition" SG_ 1728 NMH_GW_Start_2 0;
BA_ "GenSigSwitchedByIgnition" SG_ 1728 NMH_GW_Normal_Mode_1 0;
BA_ "GenSigSwitchedByIgnition" SG_ 1728 NMH_GW_Normal_Mode_2 0;
BA_ "GenSigSwitchedByIgnition" SG_ 1728 NMH_GW_Car_WakeUp 0;
BA_ "GenSigSwitchedByIgnition" SG_ 1728 NMH_GW_Per_WakeUp 0;
BA_ "NWM-WakeupAllowed" SG_ 1728 NMH_GW_Per_WakeUp 1;
BA_ "GenSigSwitchedByIgnition" SG_ 1728 NMH_GW_Fkt_WakeUp 0;
BA_ "NWM-WakeupAllowed" SG_ 1728 NMH_GW_Fkt_WakeUp 1;
BA_ "GenSigSwitchedByIgnition" SG_ 1728 NMH_GW_NM_aktiv_Klemme_15 0;
BA_ "GenSigSwitchedByIgnition" SG_ 1728 NMH_GW_NM_aktiv_Diagnose 0;
BA_ "GenSigSwitchedByIgnition" SG_ 1728 NMH_GW_NM_aktiv_Start 0;
BA_ "GenSigSwitchedByIgnition" SG_ 1728 NMH_GW_NM_aktiv_BDM 0;
BA_ "GenSigSwitchedByIgnition" SG_ 1728 NMH_GW_NM_aktiv_Warnblinken 0;
BA_ "GenSigSwitchedByIgnition" SG_ 1728 NMH_GW_NM_aktiv_ESP 0;
BA_ "GenSigSwitchedByIgnition" SG_ 1728 NMH_GW_NM_aktiv_EMP 0;
BA_ "GenSigSwitchedByIgnition" SG_ 1728 NMH_GW_Abschaltstufe_3 0;
BA_ "GenSigSwitchedByIgnition" SG_ 1728 NMH_GW_SG_Fehlerdauer 0;
BA_ "GenSigSwitchedByIgnition" SG_ 1728 NMH_GW_STH_Wakeup 0;
BA_ "GenSigSwitchedByIgnition" SG_ 1728 NMH_GW_NL_Diagnose 0;
BA_ "GenSigSwitchedByIgnition" SG_ 1728 NM_GW_Signalfehler 0;
BA_ "GenSigSwitchedByIgnition" SG_ 1728 NMH_GW_TimeOut_Fehler 0;
BA_ "GenSigSwitchedByIgnition" SG_ 1728 NMH_GW_CAN_Diag_deaktiv 0;
BA_ "GenSigSwitchedByIgnition" SG_ 1728 NMH_GW_KompSchutz 0;
BA_ "GenSigSwitchedByIgnition" SG_ 1728 NMH_GW_Mute_Mode 0;
BA_ "GenSigSwitchedByIgnition" SG_ 1728 NMH_GW_Transport_Mode 0;
BA_ "GenSigSwitchedByIgnition" SG_ 1728 NMH_GW_Abschaltstufe_aktiv 0;
BA_ "GenSigSwitchedByIgnition" SG_ 1728 NMH_GW_Eindraht_Fehler 0;
BA_ "GenSigSwitchedByIgnition" SG_ 1728 NMH_GW_ACAN 0;
BA_ "GenSigSwitchedByIgnition" SG_ 1728 NMH_GW_KombiCAN 0;
BA_ "GenSigSwitchedByIgnition" SG_ 1728 NMH_GW_KomfortCAN 0;
BA_ "GenSigSwitchedByIgnition" SG_ 1728 NMH_GW_Infotainment 0;
BA_ "GenSigSwitchedByIgnition" SG_ 1728 NMH_GW_Fahrwerk 0;
BA_ "GenSigSwitchedByIgnition" SG_ 1728 NMH_GW_WakeUp_CAN_Bus 0;
BA_ "GenSigSwitchedByIgnition" SG_ 1730 NMH_GE_Start_1 0;
BA_ "GenSigStartValue" SG_ 1730 NMH_GE_Start_1 1;
BA_ "GenSigSwitchedByIgnition" SG_ 1730 NMH_GE_Start_2 0;
BA_ "GenSigSwitchedByIgnition" SG_ 1730 NMH_GE_Normal_Mode_1 0;
BA_ "GenSigSwitchedByIgnition" SG_ 1730 NMH_GE_Normal_Mode_2 0;
BA_ "GenSigSwitchedByIgnition" SG_ 1730 NMH_GE_Car_WakeUp 0;
BA_ "GenSigSwitchedByIgnition" SG_ 1730 NMH_GE_Per_WakeUp 0;
BA_ "NWM-WakeupAllowed" SG_ 1730 NMH_GE_Per_WakeUp 1;
BA_ "GenSigSwitchedByIgnition" SG_ 1730 NMH_GE_Fkt_WakeUp 0;
BA_ "NWM-WakeupAllowed" SG_ 1730 NMH_GE_Fkt_WakeUp 1;
BA_ "GenSigSwitchedByIgnition" SG_ 1730 NMH_GE_NM_aktiv_Klemme_15 0;
BA_ "GenSigSwitchedByIgnition" SG_ 1730 NMH_GE_NM_aktiv_Diagnose 0;
BA_ "GenSigSwitchedByIgnition" SG_ 1730 NMH_GE_NM_aktiv_Start 0;
BA_ "GenSigSwitchedByIgnition" SG_ 1730 NMH_GE_N_Haltephase 0;
BA_ "GenSigSwitchedByIgnition" SG_ 1730 NMH_GE_Positionsanzeige 0;
BA_ "GenSigSwitchedByIgnition" SG_ 1730 NMH_GE_kein_NL 0;
BA_ "GenSigSwitchedByIgnition" SG_ 1730 NMH_GE_NL_Daten_EEPROM 0;
BA_ "GenSigSwitchedByIgnition" SG_ 1730 NMH_GE_NL_Drucksens 0;
BA_ "GenSigSwitchedByIgnition" SG_ 1730 NMH_GE_NL_Abtrieb 0;
BA_ "GenSigSwitchedByIgnition" SG_ 1730 NMH_GE_NL_Waehlhebel 0;
BA_ "GenSigSwitchedByIgnition" SG_ 1730 NMH_GE_NL_Wegfahrsperre 0;
BA_ "GenSigSwitchedByIgnition" SG_ 1730 NM_GE_Signalfehler 0;
BA_ "GenSigSwitchedByIgnition" SG_ 1730 NMH_GE_TimeOut_Fehler 0;
BA_ "GenSigSwitchedByIgnition" SG_ 1730 NMH_GE_CAN_Diag_deaktiv 0;
BA_ "GenSigSwitchedByIgnition" SG_ 1730 NMH_GE_KompSchutz 0;
BA_ "GenSigSwitchedByIgnition" SG_ 1730 NMH_GE_Mute_Mode 0;
BA_ "GenSigSwitchedByIgnition" SG_ 1730 NMH_GE_Transport_Mode 0;
BA_ "GenSigSwitchedByIgnition" SG_ 1730 NMH_GE_Abschaltstufe_aktiv 0;
BA_ "GenSigSwitchedByIgnition" SG_ 1730 NMH_GE_Eindraht_Fehler 0;
BA_ "GenSigSwitchedByIgnition" SG_ 1730 NMH_GE_Lokalaktiv 0;
BA_ "GenSigSwitchedByIgnition" SG_ 1730 NMH_GE_Subsystemaktiv 0;
BA_ "GenSigSwitchedByIgnition" SG_ 1730 NMH_GSG_Subbusaktiv 0;
BA_ "GenSigSwitchedByIgnition" SG_ 1729 NMH_MO_Start_1 0;
BA_ "GenSigStartValue" SG_ 1729 NMH_MO_Start_1 1;
BA_ "GenSigSwitchedByIgnition" SG_ 1729 NMH_MO_Start_2 0;
BA_ "GenSigSwitchedByIgnition" SG_ 1729 NMH_MO_Normal_Mode_1 0;
BA_ "GenSigSwitchedByIgnition" SG_ 1729 NMH_MO_Normal_Mode_2 0;
BA_ "GenSigSwitchedByIgnition" SG_ 1729 NMH_MO_Car_WakeUp 0;
BA_ "GenSigSwitchedByIgnition" SG_ 1729 NMH_MO_Per_WakeUp 0;
BA_ "NWM-WakeupAllowed" SG_ 1729 NMH_MO_Per_WakeUp 1;
BA_ "GenSigSwitchedByIgnition" SG_ 1729 NMH_MO_Fkt_WakeUp 0;
BA_ "NWM-WakeupAllowed" SG_ 1729 NMH_MO_Fkt_WakeUp 1;
BA_ "GenSigSwitchedByIgnition" SG_ 1729 NMH_MO_NM_aktiv_Klemme_15 0;
BA_ "GenSigSwitchedByIgnition" SG_ 1729 NMH_MO_NM_aktiv_Diagnose 0;
BA_ "GenSigSwitchedByIgnition" SG_ 1729 NMH_MO_NM_aktiv_Start 0;
BA_ "GenSigSwitchedByIgnition" SG_ 1729 NMH_MO_NM_aktiv_EKP_Vorlauf 0;
BA_ "GenSigSwitchedByIgnition" SG_ 1729 NMH_MO_NM_aktiv_STH_Betrieb 0;
BA_ "GenSigSwitchedByIgnition" SG_ 1729 NMH_MO_NM_aktiv_HV 0;
BA_ "GenSigSwitchedByIgnition" SG_ 1729 NMH_MO_kein_NL 0;
BA_ "GenSigSwitchedByIgnition" SG_ 1729 NMH_MO_NL_Kuehlerluefter 0;
BA_ "GenSigSwitchedByIgnition" SG_ 1729 NMH_MO_NL_Diagnose 0;
BA_ "GenSigSwitchedByIgnition" SG_ 1729 NMH_MO_NL_WFS 0;
BA_ "GenSigSwitchedByIgnition" SG_ 1729 NMH_MO_NL_EEPROM 0;
BA_ "GenSigSwitchedByIgnition" SG_ 1729 NMH_MO_NL_Sonstige 0;
BA_ "GenSigSwitchedByIgnition" SG_ 1729 NM_MO_01_NM_aktiv_Betankung 0;
BA_ "GenSigSwitchedByIgnition" SG_ 1729 NM_MO_Signalfehler 0;
BA_ "GenSigSwitchedByIgnition" SG_ 1729 NMH_MO_TimeOut_Fehler 0;
BA_ "GenSigSwitchedByIgnition" SG_ 1729 NMH_MO_CAN_Diag_deaktiv 0;
BA_ "GenSigSwitchedByIgnition" SG_ 1729 NMH_MO_KompSchutz 0;
BA_ "GenSigSwitchedByIgnition" SG_ 1729 NMH_MO_Mute_Mode 0;
BA_ "GenSigSwitchedByIgnition" SG_ 1729 NMH_MO_Transport_Mode 0;
BA_ "GenSigSwitchedByIgnition" SG_ 1729 NMH_MO_Abschaltstufe_aktiv 0;
BA_ "GenSigSwitchedByIgnition" SG_ 1729 NMH_MO_Eindraht_Fehler 0;
BA_ "GenSigSwitchedByIgnition" SG_ 1729 NMH_MO_Lokalaktiv 0;
BA_ "GenSigSwitchedByIgnition" SG_ 1729 NMH_MO_Subsystemaktiv 0;
BA_ "GenSigSwitchedByIgnition" SG_ 1736 NMH_MO_SL_Start_1 0;
BA_ "GenSigStartValue" SG_ 1736 NMH_MO_SL_Start_1 1;
BA_ "GenSigSwitchedByIgnition" SG_ 1736 NMH_MO_SL_Start_2 0;
BA_ "GenSigSwitchedByIgnition" SG_ 1736 NMH_MO_SL_Normal_Mode_1 0;
BA_ "GenSigSwitchedByIgnition" SG_ 1736 NMH_MO_SL_Normal_Mode_2 0;
BA_ "GenSigSwitchedByIgnition" SG_ 1736 NMH_MO_SL_Car_WakeUp 0;
BA_ "GenSigSwitchedByIgnition" SG_ 1736 NMH_MO_SL_Per_WakeUp 0;
BA_ "NWM-WakeupAllowed" SG_ 1736 NMH_MO_SL_Per_WakeUp 1;
BA_ "GenSigSwitchedByIgnition" SG_ 1736 NMH_MO_SL_Fkt_WakeUp 0;
BA_ "NWM-WakeupAllowed" SG_ 1736 NMH_MO_SL_Fkt_WakeUp 1;
BA_ "GenSigSwitchedByIgnition" SG_ 1736 NMH_MO_SL_NM_aktiv_Klemme_15 0;
BA_ "GenSigSwitchedByIgnition" SG_ 1736 NMH_MO_SL_NM_aktiv_Diagnose 0;
BA_ "GenSigSwitchedByIgnition" SG_ 1736 NMH_MO_SL_NM_aktiv_Start 0;
BA_ "GenSigSwitchedByIgnition" SG_ 1736 NMH_MO_SL_NM_aktiv_EKP_Vorlauf 0;
BA_ "GenSigSwitchedByIgnition" SG_ 1736 NMH_MO_SL_NM_aktiv_STH_Betrieb 0;
BA_ "GenSigSwitchedByIgnition" SG_ 1736 NMH_MO_SL_NM_aktiv_HV 0;
BA_ "GenSigSwitchedByIgnition" SG_ 1736 NMH_MO_kein_NL 0;
BA_ "GenSigSwitchedByIgnition" SG_ 1736 NMH_MO_NL_Kuehlerluefter 0;
BA_ "GenSigSwitchedByIgnition" SG_ 1736 NMH_MO_NL_Diagnose 0;
BA_ "GenSigSwitchedByIgnition" SG_ 1736 NMH_MO_NL_WFS 0;
BA_ "GenSigSwitchedByIgnition" SG_ 1736 NMH_MO_NL_EEPROM 0;
BA_ "GenSigSwitchedByIgnition" SG_ 1736 NMH_MO_NL_Sonstige 0;
BA_ "GenSigSwitchedByIgnition" SG_ 1736 NM_MO_SL_Signalfehler 0;
BA_ "GenSigSwitchedByIgnition" SG_ 1736 NMH_MO_SL_TimeOut_Fehler 0;
BA_ "GenSigSwitchedByIgnition" SG_ 1736 NMH_MO_SL_CAN_Diag_deaktiv 0;
BA_ "GenSigSwitchedByIgnition" SG_ 1736 NMH_MO_SL_KompSchutz 0;
BA_ "GenSigSwitchedByIgnition" SG_ 1736 NMH_MO_SL_Mute_Mode 0;
BA_ "GenSigSwitchedByIgnition" SG_ 1736 NMH_MO_SL_Transport_Mode 0;
BA_ "GenSigSwitchedByIgnition" SG_ 1736 NMH_MO_SL_Abschaltstufe_aktiv 0;
BA_ "GenSigSwitchedByIgnition" SG_ 1736 NMH_MO_SL_Busfehler 0;
BA_ "GenSigSwitchedByIgnition" SG_ 1736 NMH_MO_Sl_Lokalaktiv 0;
BA_ "GenSigSwitchedByIgnition" SG_ 1736 NMH_MO_SL_Subsystemaktiv 0;
BA_ "GenSigSwitchedByIgnition" SG_ 1782 NMH_SCR_Start_1 0;
BA_ "GenSigSwitchedByIgnition" SG_ 1782 NMH_SCR_Start_2 0;
BA_ "GenSigSwitchedByIgnition" SG_ 1782 NMH_SCR_Normal_Mode_1 0;
BA_ "GenSigSwitchedByIgnition" SG_ 1782 NMH_SCR_Normal_Mode_2 0;
BA_ "GenSigSwitchedByIgnition" SG_ 1782 NMH_SCR_Car_WakeUp 0;
BA_ "GenSigSwitchedByIgnition" SG_ 1782 NMH_SCR_Per_WakeUp 0;
BA_ "NWM-WakeupAllowed" SG_ 1782 NMH_SCR_Per_WakeUp 1;
BA_ "GenSigSwitchedByIgnition" SG_ 1782 NMH_SCR_Fkt_WakeUp 0;
BA_ "NWM-WakeupAllowed" SG_ 1782 NMH_SCR_Fkt_WakeUp 1;
BA_ "GenSigSwitchedByIgnition" SG_ 1782 NMH_SCR_Klemme_15 0;
BA_ "GenSigSwitchedByIgnition" SG_ 1782 NMH_SCR_Diagnose 0;
BA_ "GenSigSwitchedByIgnition" SG_ 1782 NMH_SCR_MindestAktivZeit 0;
BA_ "GenSigSwitchedByIgnition" SG_ 1782 NMH_SCR_NL_Datem_EEPROM 0;
BA_ "GenSigSwitchedByIgnition" SG_ 1782 NMH_SCR_NL_OBD_Diagnose 0;
BA_ "GenSigSwitchedByIgnition" SG_ 1782 NMH_SCR_Signalfehler 0;
BA_ "GenSigSwitchedByIgnition" SG_ 1782 NMH_SCR_TimeOut_Fehler 0;
BA_ "GenSigSwitchedByIgnition" SG_ 1782 NMH_SCR_CAN_Diag_deaktiv 0;
BA_ "GenSigSwitchedByIgnition" SG_ 1782 NMH_SCR_KompSchutz 0;
BA_ "GenSigSwitchedByIgnition" SG_ 1782 NMH_SCR_Mute_Mode 0;
BA_ "GenSigSwitchedByIgnition" SG_ 1782 NMH_SCR_Transport_Mode 0;
BA_ "GenSigSwitchedByIgnition" SG_ 1782 NMH_SCR_Abschaltstufe_aktiv 0;
BA_ "GenSigSwitchedByIgnition" SG_ 1782 NMH_SCR_Busfehler 0;
BA_ "GenSigSwitchedByIgnition" SG_ 1782 NMH_SCR_Lokalaktiv 0;
BA_ "GenSigSwitchedByIgnition" SG_ 1782 NMH_SCR_Subsystemaktiv 0;
BA_REL_ "GenSigTimeoutTime" BU_SG_REL_ Getriebe_DL382_MLB SG_ 782 Motor_05_CHK 500;
BA_REL_ "GenSigTimeoutTime" BU_SG_REL_ Getriebe_DL382_MLB SG_ 782 Motor_05_BZ 500;
BA_REL_ "GenSigTimeoutTime" BU_SG_REL_ Getriebe_DL382_MLB SG_ 782 MO_Schaltbeeinfl_Leistungsbegr 500;
BA_REL_ "GenSigTimeoutTime" BU_SG_REL_ Getriebe_DL382_MLB SG_ 782 MO_Schaltbeeinfl_Partikelfilter 500;
BA_REL_ "GenSigTimeoutTime" BU_SG_REL_ Getriebe_DL382_MLB SG_ 782 MO_Prio_MIN_Wunschdrehzahl 500;
BA_REL_ "GenSigTimeoutTime" BU_SG_REL_ Getriebe_DL382_MLB SG_ 782 MO_MAX_Wunschdrehzahl 500;
BA_REL_ "GenSigTimeoutTime" BU_SG_REL_ Getriebe_DL382_MLB SG_ 782 MO_Prio_MAX_Wunschdrehzahl 500;
BA_REL_ "GenSigTimeoutTime" BU_SG_REL_ Getriebe_DL382_MLB SG_ 782 MO_Luftpfad_aktiv 500;
BA_REL_ "GenSigTimeoutTime" BU_SG_REL_ Getriebe_DL382_MLB SG_ 782 MO_MIN_Wunschdrehzahl 500;
BA_REL_ "GenSigTimeoutTime" BU_SG_REL_ Getriebe_DL382_MLB SG_ 782 MO_Drehzahlbeeinflussung 500;
BA_REL_ "GenSigTimeoutTime" BU_SG_REL_ Getriebe_DL382_MLB SG_ 1600 MO_QBit_Ansaugluft_Temp 5000;
BA_REL_ "GenSigTimeoutTime" BU_SG_REL_ Getriebe_DL382_MLB SG_ 1600 MO_QBit_Kuehlmittel_Temp 5000;
BA_REL_ "GenSigTimeoutTime" BU_SG_REL_ Getriebe_DL382_MLB SG_ 1600 MO_aktives_Getriebeheizen 5000;
BA_REL_ "GenSigTimeoutTime" BU_SG_REL_ Getriebe_DL382_MLB SG_ 1600 MO_Ansaugluft_Temp 5000;
BA_REL_ "GenSigTimeoutTime" BU_SG_REL_ Getriebe_DL382_MLB SG_ 1600 MO_Kuehlmittel_Temp 5000;
BA_REL_ "GenSigTimeoutTime" BU_SG_REL_ Getriebe_DL382_MLB SG_ 1600 MO_Hoeheninfo 5000;
BA_REL_ "GenSigTimeoutTime" BU_SG_REL_ Getriebe_DL382_MLB SG_ 1600 MO_Getriebe_kuehlen 5000;
BA_REL_ "GenSigTimeoutTime" BU_SG_REL_ Getriebe_DL382_MLB SG_ 1600 MO_Mom_Traegheit_02 5000;
BA_REL_ "GenSigTimeoutTime" BU_SG_REL_ Getriebe_DL382_MLB SG_ 276 Motor_10_CHK 500;
BA_REL_ "GenSigTimeoutTime" BU_SG_REL_ Getriebe_DL382_MLB SG_ 276 Motor_10_BZ 500;
BA_REL_ "GenSigTimeoutTime" BU_SG_REL_ Getriebe_DL382_MLB SG_ 276 MO_Zylinderabschaltung 500;
BA_REL_ "GenSigTimeoutTime" BU_SG_REL_ Getriebe_DL382_MLB SG_ 1648 MO_Abstellzeit 5000;
BA_REL_ "GenSigTimeoutTime" BU_SG_REL_ Getriebe_DL382_MLB SG_ 1648 MO_Abstellzeit_Status 5000;
BA_REL_ "GenSigTimeoutTime" BU_SG_REL_ Getriebe_DL382_MLB SG_ 1648 MO_Anzahl_Abgesch_Zyl 5000;
BA_REL_ "GenSigTimeoutTime" BU_SG_REL_ Getriebe_DL382_MLB SG_ 191 Motor_27_CRC 500;
BA_REL_ "GenSigTimeoutTime" BU_SG_REL_ Getriebe_DL382_MLB SG_ 191 Motor_27_BZ 500;
BA_REL_ "GenSigTimeoutTime" BU_SG_REL_ Getriebe_DL382_MLB SG_ 191 MO_Mom_dyn_Diff 500;
BA_REL_ "GenSigTimeoutTime" BU_SG_REL_ Getriebe_DL382_MLB SG_ 1014 MO_Freigabe_Segeln 1000;
BA_REL_ "GenSigTimeoutTime" BU_SG_REL_ Getriebe_DL382_MLB SG_ 1601 Motor_Code_01_CHK 5000;
BA_REL_ "GenSigTimeoutTime" BU_SG_REL_ Getriebe_DL382_MLB SG_ 1601 Motor_Code_01_BZ 5000;
BA_REL_ "GenSigTimeoutTime" BU_SG_REL_ Getriebe_DL382_MLB SG_ 1601 MO_Faktor_Momente 5000;
BA_REL_ "GenSigTimeoutTime" BU_SG_REL_ Getriebe_DL382_MLB SG_ 1601 MO_Code 5000;
BA_REL_ "GenSigTimeoutTime" BU_SG_REL_ SAK SG_ 1601 MO_Code 5000;
BA_REL_ "GenSigTimeoutTime" BU_SG_REL_ Getriebe_DL382_MLB SG_ 1601 MO_Getriebe_Code 5000;
BA_REL_ "GenSigTimeoutTime" BU_SG_REL_ Gateway SG_ 969 MOS_KD_Fehler 1000;
BA_REL_ "GenSigTimeoutTime" BU_SG_REL_ Getriebe_DL382_MLB SG_ 1742 NMH_BMS_Start_1 2000;
BA_REL_ "GenSigTimeoutTime" BU_SG_REL_ Getriebe_DL382_MLB SG_ 1743 NMH_EM_Start_1 2000;
BA_REL_ "GenSigTimeoutTime" BU_SG_REL_ Getriebe_DL382_MLB SG_ 1753 NMH_EPB_Start_1 2000;
BA_REL_ "GenSigTimeoutTime" BU_SG_REL_ Getriebe_DL382_MLB SG_ 1728 NMH_GW_Start_1 2000;
BA_REL_ "GenSigTimeoutTime" BU_SG_REL_ Getriebe_DL382_MLB SG_ 1728 NMH_GW_Start_2 2000;
BA_REL_ "GenSigTimeoutTime" BU_SG_REL_ Getriebe_DL382_MLB SG_ 1728 NMH_GW_Normal_Mode_1 2000;
BA_REL_ "GenSigTimeoutTime" BU_SG_REL_ Getriebe_DL382_MLB SG_ 1728 NMH_GW_Normal_Mode_2 2000;
BA_REL_ "GenSigTimeoutTime" BU_SG_REL_ Getriebe_DL382_MLB SG_ 1730 NMH_GE_Start_1 2000;
BA_REL_ "GenSigTimeoutTime" BU_SG_REL_ Getriebe_DL382_MLB SG_ 1729 NMH_MO_Start_1 2000;
BA_REL_ "GenSigTimeoutTime" BU_SG_REL_ Getriebe_DL382_MLB SG_ 1736 NMH_MO_SL_Start_1 2000;
BA_REL_ "GenSigTimeoutTime" BU_SG_REL_ Getriebe_DL382_MLB SG_ 1782 NMH_SCR_Start_1 2000;
VAL_ 782 MO_EKlKomLeiRed 0 "keine_Leistungsbegr" 1 "Leistungsbegr_75" 2 "Leistungsbegr_50" 3 "Leistungsbegr_25" ;
VAL_ 782 MO_Freig_Reku 0 "Rekuperations-Modus aus" 1 "Empfehlung Spannungsanhebung" 2 "Empfehlung Spannungsabsenkung" 3 "Rekuperationsmodus aktiv, Spannungsvariation nicht notwendig" ;
VAL_ 782 MO_Klima_Eingr 0 "kein Eingriff" 1 "Klimakompressor ausschalten" 2 "Klimakompressor Leistungsreduzierung" 3 "Klimakompressor aufgrund der Heissleuchtenvorwarnung ausschalten" ;
VAL_ 782 MO_Status_Normalbetrieb_02 0 "kein_Normalbetrieb" 1 "Normalbetrieb_erreicht" ;
VAL_ 782 MO_Prio_MIN_Wunschdrehzahl 0 "Wunsch" 1 "Zwang" ;
VAL_ 782 MO_Freig_Anlass 0 "Start_nicht_zulaessig" 1 "Startfreigabe" ;
VAL_ 782 MO_Aussp_Anlass 0 "Anlasser_darf_angesteuert_werden" 1 "Anlasser_ausspuren__Ansteuerung_nicht_moeglich" ;
VAL_ 782 MO_MAX_Wunschdrehzahl 511 "Fehler" ;
VAL_ 782 MO_Prio_MAX_Wunschdrehzahl 0 "Wunsch" 1 "Zwang" ;
VAL_ 782 MO_Luftpfad_aktiv 0 "kein Eingriff oder nur Eingriff über Zündpfad" 1 "Eingriff über Luftpfad" ;
VAL_ 782 MO_v_Begrenz_Aktiv 0 "inaktiv" 1 "aktiv" ;
VAL_ 782 MO_v_Begrenz_Aktivierbar 0 "V-Begrenzung nicht möglich" 1 "V-Begrenzung möglich" ;
VAL_ 782 MO_Verbot_EKP 0 "Ansteuerung zugelassen" 1 "Ansteuerung verboten" ;
VAL_ 782 MO_Anf_Pruefimpuls 0 "keine Anforderung" 1 "Anforderung" ;
VAL_ 782 MO_Anf_KL75 0 "Anforderung KL75 ausschalten" 1 "Anforderung KL75 einschalten" ;
VAL_ 782 MO_Charisma_FahrPr 0 "nicht_belegt" 1 "Programm_1" 2 "Programm_2" 3 "Programm_3" 4 "Programm_4" 5 "Programm_5" 6 "Programm_6" 7 "Programm_7" ;
VAL_ 782 MO_Charisma_Status 0 "Init" 1 "verfuegbar" 2 "nicht_verfuegbar" 3 "asynchron_durch_Fahrerwunsch" ;
VAL_ 782 MO_Charisma_Umschaltung 0 "Idle" 1 "Erkennung_Umschaltaufforderung" 2 "Steuerbotschaft_nicht_definiert" 3 "Umschaltung_verzoegert" ;
VAL_ 782 MO_Handshake_STH 0 "keine EKP-Ansteuerung durch STH-Anforderung" 1 "EKP-Ansteuerung durch STH-Anforderung" ;
VAL_ 782 MO_MIN_Wunschdrehzahl 255 "Fehler" ;
VAL_ 1088 MO_Kuehlerluefter_MUX 0 "Kuehlerluefter_1" 1 "Kuehlerluefter_2" ;
VAL_ 1088 MO_Kuehlerluefter_1 126 "Init" 127 "Fehler" ;
VAL_ 1088 MO_Kuehlerluefter_2 126 "Init" 127 "Fehler" ;
VAL_ 1088 MO_HYB_Status_HV_Ladung 0 "HV-Ladung_nicht_notwendig" 1 "HV-Ladung_notwendig_Freigaben_erforderlich" 2 "HV-Ladung laeuf" 3 "HV-Ladung_erfolgreich_Motorstart_moeglich" 4 "HV_Ladung_abgebrochen" ;
VAL_ 1088 MO_ITM_Warnung_Pumpe 0 "keine_Warnung" 1 "ITM_Warnung" ;
VAL_ 1088 WIV_Anzeige_aktiv 0 "Anzeige aus" 1 "WIV Anzeige aktiv" ;
VAL_ 1088 WIV_Oelmin_Warn 0 "in_Ordnung" 1 "Warnung" ;
VAL_ 1088 WIV_Sensorfehler 0 "in_Ordnung" 1 "Sensor_defekt" ;
VAL_ 1088 WIV_Schieflage 0 "Fahrzeug_gerade" 1 "Fahrzeug_in_Schieflage" ;
VAL_ 1088 MO_Zustand_HWP 0 "HWP_nicht_schaltbar" 1 "HWP_foerdert_nicht" 2 "HWP_foerdert" 3 "reserviert" ;
VAL_ 1088 MO_Kat_Warnung 0 "Lampe_aus" 1 "Lampe_ein" ;
VAL_ 1088 MO_Vorglueh_Lampe 0 "Lampe_aus" 1 "Lampe_ein" ;
VAL_ 1088 WIV_Oelsystem_aktiv 0 "Anzeige_aus" 1 "Anzeige_aktiv" ;
VAL_ 1088 WIV_nicht_betriebswarm 0 "Motor_warm" 1 "Motor_nicht_betriebswarm" ;
VAL_ 1088 WIV_Ueberfuell_Warn 0 "in_Ordnung" 1 "Ueberfuellwarnung" ;
VAL_ 1088 WIV_laufender_Motor 0 "Messung_moeglich" 1 "Messung_nicht_moeglich" ;
VAL_ 1088 MO_HYB_Text_1 0 "kein_Text" 1 "Text_anzeigen" ;
VAL_ 1088 MO_HYB_Text_2 0 "kein_Text" 1 "Text_anzeigen" ;
VAL_ 1088 MO_HYB_Text_3 0 "kein_Text" 1 "Text_anzeigen" ;
VAL_ 1088 MO_HYB_Text_4 0 "kein_Text" 1 "Text_anzeigen" ;
VAL_ 1088 MO_Text_Motorstart 0 "keine_Anzeige" 1 "Motor_im_Stoppbetrieb" 2 "StartStopp_sicherheitsbedingt_deaktiviert" 3 "System_fordert_Wiederstart" 5 "Motorlauf_noetig" 9 "Unerwuenschter_Motorstillstand" 12 "Motor_startet" 13 "Kupplung_betaetigen" 14 "Waehlhebel_in_PN_Position" 15 "Bremse_treten" ;
VAL_ 1088 MO_HYB_Text_5 0 "kein_Text" 1 "Text_anzeigen" ;
VAL_ 1088 MO_HYB_Text_6 0 "kein_Text" 1 "Text_anzeigen" ;
VAL_ 1088 MO_HYB_Text_7 0 "kein_Text" 1 "Text_anzeigen" ;
VAL_ 1088 WIV_Oeldyn_avl 0 "Oeldyn_nicht_vorhanden" 1 "Oeldyn_vorhanden" ;
VAL_ 1088 MO_Systemlampe 0 "Lampe aus" 1 "Lampe ein" ;
VAL_ 1088 MO_OBD2_Lampe 0 "Lampe aus" 1 "Lampe ein" ;
VAL_ 1088 MO_Heissleuchte 0 "Lampe aus" 1 "Lampe ein" ;
VAL_ 1088 MO_Partikel_Lampe 0 "Lampe aus" 1 "Lampe ein" ;
VAL_ 1088 WIV_Oelstand_nicht_vorhanden 0 "Ölstand vorhanden" 1 "Ölstand nicht vorhanden" ;
VAL_ 1088 WIV_nachfuellanzeige_ein 0 "keine_Nachfuellanzeige" 1 "Nachfuellanzeige" ;
VAL_ 1088 WIV_Ueberfuell_deaktiv 0 "Ueberfuellwarnung_am_Kombi_aktiv" 1 "Ueberfuellwarnung_am_Kombi_deaktiv" ;
VAL_ 1088 WIV_Unterfuell_Warn 0 "in_Ordnung" 1 "Unterfuellwarnung" ;
VAL_ 1088 MO_Tankdeckel_Lampe 0 "Lampe aus" 1 "Lampe ein" ;
VAL_ 1088 MO_Text_Tankdeckelwarn 0 "kein_Text" 1 "Anzeige_Text_Tankdeckelwarnung_im_Kombi" ;
VAL_ 1088 WIV_Enable_Oeldr_Motor 0 "Oeldruckauswertung_im_Kombi" 1 "Oeldruckauswertung_im_MSG" ;
VAL_ 1088 WIV_Oeldr_Warn_Motor 0 "keine_Warnung" 1 "niedrige_Oeldruckstufe_nicht_erreicht " ;
VAL_ 1088 MO_Avus_Motorschutz 0 "keine Warnung" 1 "Drehzahlwarnung Stufe 1" 2 "Drehzahlwarnung Stufe 2" 3 "Drehzahlwarnung Stufe 3" ;
VAL_ 1088 MO_HYB_Fahrbereitschaft 0 "keine_Fahrbereitschaft" 1 "Fahrbereitschaft" ;
VAL_ 1600 MO_QBit_Ansaugluft_Temp 0 "gueltiger_Wert" 1 "Ersatz_Init_oder_Fehlerwert" ;
VAL_ 1600 MO_QBit_Oel_Temp 0 "gueltiger_Wert" 1 "Ersatz_Init_oder_Fehlerwert" ;
VAL_ 1600 MO_QBit_Kuehlmittel_Temp 0 "gueltiger_Wert" 1 "Ersatz_Init_oder_Fehlerwert" ;
VAL_ 1600 MO_HYB_Fehler_HV_Netz 0 "i_O" 1 "kein_generatorischer_Betrieb_moeglich" ;
VAL_ 1600 MO_aktives_Getriebeheizen 0 "kein_Ventil_ansteuern" 1 "Ventil_muss_angesteuert_werden" ;
VAL_ 1600 MO_Absperrventil_oeffnen 0 "nicht_verfuegbar" 1 "Ansteuerung_Ventil_zulaessig" 2 "Ventil_oeffnen_oder_geoeffnet" 3 "Ventil_schliessen_oder_geschlossen" ;
VAL_ 1600 MO_Ansaugluft_Temp 254 "Init" 255 "Fehler" ;
VAL_ 1600 MO_Oel_Temp 253 "nicht_verbaut" 254 "Init" 255 "Fehler" ;
VAL_ 1600 MO_Kuehlmittel_Temp 254 "Init" 255 "Fehler" ;
VAL_ 1600 MO_Hoeheninfo 255 "Fehler" ;
VAL_ 1600 MO_Kennfeldk 0 "keine Kennfeldkühlung vorhanden" 1 "Kennfeldkühlung vorhanden" ;
VAL_ 1600 MO_Versionsinfo 0 "zum Projektbeginn 'aufgeräumter CAN' " 1 "Motor_03_mit_10ms" 16 "MQB_mit_neuer_Momentenschnittstelle" ;
VAL_ 1600 MO_Getriebe_kuehlen 0 "nicht_kuehlen" 1 "kuehlen" ;
VAL_ 1600 MO_Heizungspumpenansteuerung 13 "Fehler" 14 "Init" 15 "nicht_verbaut" ;
VAL_ 1600 MO_SpannungsAnf 0 "keine_Anforderung" 1 "Anforderung" ;
VAL_ 1607 MO_ITM_Kuehlmittel_Temp 0 "nicht_verbaut" 1 "Init" 2 "Fehler" ;
VAL_ 1607 MO_E85_Sensor 13 "nicht_verbaut" 14 "Init" 15 "Fehler" ;
VAL_ 1607 SCR_Anz_Motorstarts 14 "Fahrbarkeitseinschraenkung" 15 "keine_Einschraenkung" ;
VAL_ 1607 SCR_Reichweite 32767 "keine_Anzeige" ;
VAL_ 1607 MO_Ethanol_Spuelhinweis 0 "Kein_Hinweis" 1 "Spuelhinweis_aktiv" ;
VAL_ 1607 SCR_Warnstufe_1 0 "nicht_aktiv" 1 "Warnstufe_1_aktiv" ;
VAL_ 1607 SCR_Warnstufe_2 0 "nicht_aktiv" 1 "Warnstufe_2_aktiv" ;
VAL_ 1607 SCR_Text 0 "kein_Text" 1 "Warntext_1" 2 "Warntext_2" 3 "Hinweis_Fuellstand" 4 "Reserve" 5 "SysFehler_1" 6 "SysFehler_2" 7 "Hinweis_Systemfehler" ;
VAL_ 1607 SCR_Akustik 0 "keine_Akustik" 1 "Akustik_1" 2 "Akustik_2" 3 "Akustik_bei_Hinweis" ;
VAL_ 1607 SCR_verbaut 0 "kein_SCR" 1 "SCR_verbaut" ;
VAL_ 1607 MO_Kraftstofffilter_Wasser 0 "keine_Anzeige" 1 "Abscheidevolumen_erschoepft" ;
VAL_ 1607 SCR_Systemfehler 0 "Warnung_nicht_aktiv" 1 "Warnung_aktiv" ;
VAL_ 1607 SCR_Inducement_Strategie 0 "Restart_Strategie" 1 "Reduced_Drivability_Strategie" ;
VAL_ 1607 MO_CO2_Faktor 0 "nicht_verbaut" 4095 "Fehler" ;
VAL_ 1607 MO_MKB_MUX 0 "MKB_01" 1 "MKB_02" 2 "MKB_03" 3 "MKB_04" ;
VAL_ 1607 MO_MKB_01 0 "Minus" 1 "A" 2 "B" 3 "C" 4 "D" 5 "E" 6 "F" 7 "G" 8 "H" 9 "I" 10 "J" 11 "K" 12 "L" 13 "M" 14 "N" 15 "O" 16 "P" 17 "Q" 18 "R" 19 "S" 20 "T" 21 "U" 22 "V" 23 "W" 24 "X" 25 "Y" 26 "Z" 27 "Leerzeichen" 28 "Leerzeichen" 29 "Leerzeichen" 30 "Leerzeichen" 31 "Unterstrich" ;
VAL_ 1607 MO_MKB_02 0 "Minus" 1 "A" 2 "B" 3 "C" 4 "D" 5 "E" 6 "F" 7 "G" 8 "H" 9 "I" 10 "J" 11 "K" 12 "L" 13 "M" 14 "N" 15 "O" 16 "P" 17 "Q" 18 "R" 19 "S" 20 "T" 21 "U" 22 "V" 23 "W" 24 "X" 25 "Y" 26 "Z" 27 "Leerzeichen" 28 "Leerzeichen" 29 "Leerzeichen" 30 "Leerzeichen" 31 "Unterstrich" ;
VAL_ 1607 MO_MKB_03 0 "Minus" 1 "A" 2 "B" 3 "C" 4 "D" 5 "E" 6 "F" 7 "G" 8 "H" 9 "I" 10 "J" 11 "K" 12 "L" 13 "M" 14 "N" 15 "O" 16 "P" 17 "Q" 18 "R" 19 "S" 20 "T" 21 "U" 22 "V" 23 "W" 24 "X" 25 "Y" 26 "Z" 27 "Leerzeichen" 28 "Leerzeichen" 29 "Leerzeichen" 30 "Leerzeichen" 31 "Unterstrich" ;
VAL_ 1607 MO_MKB_04 0 "Minus" 1 "A" 2 "B" 3 "C" 4 "D" 5 "E" 6 "F" 7 "G" 8 "H" 9 "I" 10 "J" 11 "K" 12 "L" 13 "M" 14 "N" 15 "O" 16 "P" 17 "Q" 18 "R" 19 "S" 20 "T" 21 "U" 22 "V" 23 "W" 24 "X" 25 "Y" 26 "Z" 27 "Leerzeichen" 28 "Leerzeichen" 29 "Leerzeichen" 30 "Leerzeichen" 31 "Unterstrich" ;
VAL_ 276 MO_Sig_Fahrpedalgradient 0 "Fahrpedalgradient positiv" 1 "Fahrpedalgradient negativ" ;
VAL_ 276 MO_BKV_Unterdruckwarnung 0 "Unterdruckhaushalt_iO" 1 "Unterdruckhaushalt_niO" ;
VAL_ 276 MO_Zylinderabschaltung 0 "Vollmotorbetrieb_VMB" 1 "Uebergang_HMB_in_VMB" 2 "Uebergang_VMB_in_HMB" 3 "Halbmotorbetrieb_HMB" ;
VAL_ 276 MO_Fahrpedalgradient 255 "Fehler" ;
VAL_ 276 MO_Schubabschaltung 0 "keine_Schubabschaltung" 1 "Schubabschaltung_aktiv" ;
VAL_ 276 MO_rel_Saugrohrdruck 0 "Init_Ueberdruck" 63 "Fehler" ;
VAL_ 276 MO_rel_Saugrohrdruck_gem_err 0 "errechnet" 1 "gemessen" ;
VAL_ 276 MO_BKV_Unterdruck 254 "Init" 255 "Fehler" ;
VAL_ 276 MO_Bremspedalweg 0 "INIT" 255 "Fehler" ;
VAL_ 276 MO_Mom_Traegheit_Summe 1022 "Init" 1023 "Fehler" ;
VAL_ 276 MO_ANC_Kennfeld_Anf 0 "Kennfeld_1" 1 "Uebergang_Kennfeld_2_nach_1" 2 "Uebergang_Kennfeld_1_nach_2" 3 "Kennfeld_2" ;
VAL_ 168 MO_Mom_neg_verfuegbar 510 "Init" 511 "Fehler" ;
VAL_ 168 MO_Mom_Begr_stat 510 "Init" 511 "Fehler" ;
VAL_ 168 MO_Mom_Begr_dyn 1022 "Init" 1023 "Fehler" ;
VAL_ 168 MO_QBit_Drehzahl_01 0 "gueltiger_Wert" 1 "Ersatz_Init_oder_Fehlerwert" ;
VAL_ 168 MO_Drehzahl_01 65535 "Fehler" ;
VAL_ 1648 MO_ANC_Kennfeld_Anf 0 "Kennfeld_1" 1 "Uebergang_Kennfeld_2_nach_1" 2 "Uebergang_Kennfeld_1_nach_2" 3 "Kennfeld_2" ;
VAL_ 1648 MO_Bremslicht_Reku 0 "Aus" 1 "Ein" ;
VAL_ 1648 MO_StartStopp_PopUp 0 "Statuswechsel_ohne_Taster (Init)" 1 "StSt_per_Taster_deaktiviert" 2 "StSt_per_Taster_aktiviert" 3 "nicht verwendet" ;
VAL_ 1648 MO_EPCL 0 "EPCL_aus_kein_Text" 1 "EPCL_an_Stoerung" 2 "EPCL_an_Leistungseinschraenkung" ;
VAL_ 1648 MO_Zylabsch_Texte_02 0 "ein_ZAS_generell_keine_ZAS_Anzeigen" 1 "ZAS_im_VMB" 2 "ZAS_im_ASB_1_Zyl_aktiv" 3 "ZAS_im_ASB_2_Zyl_aktiv" 4 "ZAS_im_ASB_3_Zyl_aktiv" 5 "ZAS_im_ASB_4_Zyl_aktiv" 6 "ZAS_im_ASB_5_Zyl_aktiv" 7 "ZAS_im_ASB_6_Zyl_aktiv" 8 "ZAS_im_ASB_8_Zyl_aktiv" 9 "ZAS_im_ASB_12_Zyl_aktiv" 13 "Uebergangsbetrieb" 14 "keine_ZAS_Anzeige_ggf_Stopp_Schub_Betrieb" 15 "ZAS_Stoerungs_Anzeige" ;
VAL_ 1648 MO_Fahrzeugtyp 0 "Verbrenner_Fahrzeug" 1 "Hybrid" 2 "E_Fahrzeug" 3 "E_Fahrzeug_mit_Range_Extender" 4 "tbd" 5 "tbd" 6 "tbd" 7 "tbd" ;
VAL_ 1648 MO_Abstellzeit 254 "Init" 255 "Fehler" ;
VAL_ 1648 MO_Abstellzeit_Status 0 "Abstellzeit_nicht_berechnet" 1 "Abstellzeit_berechnet" 2 "Abstellzeit_Minimalwert" 3 "Abstellzeit_ungueltig" ;
VAL_ 1648 MO_Hybrid_StartStopp_LED 0 "LED_aus_und_Blinken_aus" 1 "LED_ein_und_Blinken_aus" 2 "LED_ein_und_Blinken_ein_50_percent" 3 "reserviert" ;
VAL_ 1648 MO_Fehler_Zylabsch 0 "kein_Fehler" 1 "Notlauf_Vollmotorbetrieb" 2 "Notlauf_mindestens_einem_abgesch_Zylinder" ;
VAL_ 1648 MO_Anzahl_Abgesch_Zyl 0 "Vollmotorbetrieb" 1 "1_Zylinder_abgeschaltet" 2 "2_Zylinder_abgeschaltet" 3 "3_Zylinder_abgeschaltet" 4 "4_Zylinder_abgeschaltet" 5 "5_Zylinder_abgeschaltet" 6 "6_Zylinder_abgeschaltet" 7 "8_Zylinder_abgeschaltet" ;
VAL_ 1648 MO_Zylabsch_Texte 0 "keine_Texte" 1 "Zylinderabschaltung_deaktivieren" 2 "Zylinderabschaltung_aktivieren" 3 "Zylinderabschaltung_unruhig" ;
VAL_ 1648 MO_Ethanol_BS_Texte 0 "kein_Text" 1 "E85_Warm_Up" 2 "FlexFuel_Warnung_Stufe_3" 3 "Warmfahrempfehlung_MQB__FlexFuel_Warnung_Stufe_1" 4 "FlexFuel_Warnung_Stufe_2" 5 "FlexFuel_Warnung_Stufe_4" 6 "E25_Warm_Up" ;
VAL_ 1648 MO_Drehzahl_Warnung 0 "keinen_Warnhinweis_anzeigen" 1 "Warnhinweis_anzeigen" ;
VAL_ 1648 MO_obere_Drehzahlgrenze 0 "Init" ;
VAL_ 1010 MO_SCR_Tankheizkreis_Leistung 254 "Init" 255 "Fehler" ;
VAL_ 1010 MO_SCR_Heizkreis_3 0 "Heizung_aus" 1 "Heizung_ein" ;
VAL_ 1010 MO_SCR_Tankheizung 0 "Heizung_aus" 1 "Heizung_ein" ;
VAL_ 1010 MO_SCR_Dosierpumpe_Zustand 0 "Pumpe_Stop" 1 "Drehzahlregelung" 2 "Druckregelung_langsam" 3 "Druckregelung_schnell" 4 "frei" 5 "Rueckwaertsbetrieb" 6 "verzoegerter_Rueckwaertsbetrieb" 7 "Pumpe_heizen" ;
VAL_ 1010 MO_SCR_Leitungsheizung 0 "Heizung_aus" 1 "Heizung_ein" ;
VAL_ 1010 MO_SCR_Dosierpumpe_Wartezeit 125 "nicht_verbaut" 127 "Fehler" ;
VAL_ 1010 MO_SCR_Transferpumpe 0 "Pumpe_aus" 1 "Pumpe_ein" ;
VAL_ 815 MO_Antriebsstrang_Warnung_HS 0 "Keine_Anzeige" 1 "Fehlereskalationsstufe_I" 2 "Fehlereskalationsstufe_II" 3 "Fehlereskalationsstufe_III" ;
VAL_ 815 MO_Anzeige_Verbrauch 0 "Init" ;
VAL_ 1391 MO_IstLeistung_EKAT 126 "Init" 127 "Fehler" ;
VAL_ 1391 MO_HYB_Drehzahl_VM 65280 "Fehler" ;
VAL_ 191 MO_Mom_dyn_Diff 255 "Init" ;
VAL_ 1014 MO_Tankklappensteuerung 0 "Init_nicht_verbaut" 1 "Tankklappe_soll_entriegeln" 2 "Tankklappe_soll_verriegeln" 3 "keine_Aktion" ;
VAL_ 1014 MO_Kl_50 0 "aus" 1 "KL50_ein_Startausfuehrung_Fahrer" ;
VAL_ 1014 MO_Freigabe_Segeln 0 "Segelbetrieb_nicht_freigegeben" 1 "Segelbetrieb_freigegeben" ;
VAL_ 1601 MO_Faktor_Momente 0 "nicht belegt" 1 "Faktor: x 0,5Nm" 2 "Faktor: x 1,0Nm" 3 "Faktor: x 2,0Nm" ;
VAL_ 1601 MO_Hybridfahrzeug 0 "kein_Hybridfahrzeug" 1 "Mild_Hybrid" 2 "Full_Hybrid" 3 "PlugIn_Hybrid" ;
VAL_ 1601 MO_Getriebe_Code 0 "Init" 2 "DL501" 3 "DL800" 4 "VL381" 5 "DL382" 6 "DL382_Hybrid" 8 "AL552" 9 "AL552_Hybrid" 10 "AL651" 11 "AL551__AL951__AL1000_8A" 12 "PDK_PAG" 13 "AL551_Hybrid" 15 "Handschalter_konventionell" 16 "AQ250_160" 17 "AQ450" 18 "DQ200" 19 "DQ250" 20 "DQ500" 21 "SQ100" 22 "SQ200" 32 "Single_Gear__ohne_GSG_WH_am_MSG" ;
VAL_ 1601 MO_StartStopp_Codiert 0 "Start_Stopp_nicht_verbaut" 1 "Start_Stopp_verbaut" ;
VAL_ 1601 MO_Anzahl_Zyl 0 "kein_Zylinder" 1 "1_Zylinder" 2 "2_Zylinder" 3 "3_Zylinder" 4 "4_Zylinder" 5 "5_Zylinder" 6 "6_Zylinder" 7 "7_Zylinder" 8 "8_Zylinder" 9 "9_Zylinder" 10 "10_Zylinder" 11 "11_Zylinder" 12 "12_Zylinder" 13 "15_Zylinder" 14 "16_Zylinder" 15 "18_Zylinder" ;
VAL_ 1601 MO_Kraftstoffart 0 "Diesel" 1 "Benzin_inkl_E25_E85" 2 "CNG" 3 "LPG" 4 "Wasserstoff" 5 "E100_Ethanol" 15 "kein_Verbrennungskraftstoff" ;
VAL_ 1601 MO_Ansaugsystem 0 "Turbo" 1 "Sauger" ;
VAL_ 1601 MO_Einspritzart 0 "MPI" 1 "FSI_TDI" ;
VAL_ 305 MO_ePowermeter 0 "Init_keine_Anzeige" 254 "Funktion_deaktiv_Anzeige_ausgegraut" 255 "Fehler_keine_Anzeige" ;
VAL_ 305 MO_Zust_Antrieb 0 "VKM aktiv" 1 "EM aktiv" 2 "VKM und EM aktiv" 3 "Segeln oder Reku aktiv" ;
VAL_ 305 MO_Zust_Betriebsstrategie 0 "Kein Hybrid" 1 "Depleting" 2 "Soft-Depleting " 3 "Sustaining" 4 "Increasing" 5 "Fremdgesteuert" ;
VAL_ 305 MO_W_Reku_normiert_ueberlauf 0 "kein_Ueberlauf" 1 "Rekuperationssignal_min_1_mal_uebergelaufen" ;
VAL_ 305 Ladezustand 255 "Fehler" ;
VAL_ 305 Enrgfluss_State 0 "Init" 1 "no_torques" 2 "pos_tor_EE" 3 "pos_tor_ICE" 4 "pos_tor_ICE_bat_charge" 5 "pos_tor_EE_ICE" 6 "neg_tor_EE_bar_charge" 7 "neg_tor_EE_bat_discharge" 8 "neg_tor_EE" 9 "ICE_charge_bat" 10 "neg_tor_EE_and_ICE" 11 "no_tor_sailing" 12 "no_tor_sailing_and_ICE" 13 "stand_pos_tor_ICE_bat_charge" 14 "stand_pos_tor_ICE" 15 "stand_no_tor_EE_bat_charge" 16 "stand_no_tor_EE_bat_discharge" 17 "stand_pos_tor_EE_bat_discharge" 18 "neg_tor_ICE_EE_bat_charge" 19 "no_tor_ICE_bat_charge" 20 "neg_tor_ICE_EE_bat_discharge" 21 "no_tor_ICE_bat_discharge" 22 "pos_tor_ICE_bat_discharge" 23 "rev_neg_tor_ICE_EE__batt_charge" 24 "rev_no_tor_ICE_bat_charge" 25 "rev_pos_tor_ICE_bat_charge" 26 "rev_neg_tor_ICE_EE" 27 "rev_no_tor_ICE" 28 "rev_pos_tor_ICE" 29 "rev_neg_tor_ICE_EE_bat_discharge" 30 "rev_no_tor_ICE_bat_discharge" 31 "rev_pos_tor_ICE_bat_discharge" 32 "rev_neg_tor_EE_bat_charge" 33 "rev_neg_tor_EE" 34 "rev_neg_tor_EE_bat_discharge" 35 "rev_no_tor_EE_bat_discharge" 36 "rev_pos_tor_EE_bat_discharge" 255 "Fehler" ;
VAL_ 305 MO_Powermeter 4093 "Off" ;
VAL_ 1376 MO_HV_Spannungsfreiheit 0 "HV_System_nicht_spannungsfrei" 1 "frei" 2 "frei" 3 "HV_System_spannungsfrei" ;
VAL_ 1376 Mo_Powermeter_Grenze 4093 "OFF" ;
VAL_ 1376 MO_Gesamtst_Spgfreiheit 0 "Init" 1 "HV_Komponente_spannungsfrei" 2 "HV_Komp_nicht_spannungsfrei" 3 "Fehler_nicht_spannungsfrei" ;
VAL_ 1376 MO_Tankbereitschaft_Status 0 "keine_Aktion_Init" 1 "Tankbereitschaft_wird_hergestellt" 2 "Tankbereitschaft_ist_hergestellt" 3 "Tankbereitschaft_kann_nicht_hergestellt_werden" 4 "Tanksystem_Systemfehler" 5 "Tankklappe_pruefen_schliessen" 6 "Tankvorgang_abgebrochen" ;
VAL_ 1376 MO_Energieinhalt_BMS 4094 "Init" 4095 "Fehler" ;
VAL_ 1376 MO_HYB_Status_Betriebsstrategie 0 "Init" 1 "Aktiv" 2 "Passiv_VKM_Ein" 3 "Passiv_VKM_Aus__HV_Verbraucher_Aus" 4 "Passiv_VKM_Aus__HV_Verbraucher_Ein" ;
VAL_ 1376 MO_Boost_aktiv 0 "kein_Boost_aktiv" 1 "Boost_aktiv" ;
VAL_ 969 MOS_KD_Fehler 0 "kein_KD_Fehler" 1 "KD_Fehler" ;
VAL_ 1696 NV_aktiv 0 "NV nicht aktiv" 1 "NV aktiv" ;
VAL_ 1696 NV_Texte 0 "kein_Text" 1 "Abblendlicht_einschalten" 2 "Fussgaengermarkierung_nicht_verfuegbar" 3 "zur_Zeit_nicht_verfuegbar" 4 "Systemfehler" ;
VAL_ 1696 NV_Gong 0 "kein_Gong" 1 "Gong_leise" 2 "Gong_mittel" 3 "Gong_laut" ;
VAL_ 1696 NV_Symbol 0 "kein_Symbol_anzeigen" 1 "Symbol_fuer_erkanntes_Objekt_anzeigen" ;
VAL_ 1696 NV_Hinweise 0 "keine_Anzeige" 1 "Disclaimer" 2 "Fussgaenger_Markierung_nicht_verfuegbar" 3 "Nachtsichtsystem_wird_initialisiert" ;
VAL_ 1696 NV_Piktogramm_aktiv 0 "keine_Anzeigenprioritaet" 1 "Anzeigenprioritaet" ;
VAL_ 1696 NV_Akustik_deaktiviert_Icon 0 "aus" 1 "ein" ;
VAL_ 1696 NV_FGM_deaktiviert_Icon 0 "aus" 1 "ein" ;
VAL_ 1696 NV_Markierungslicht_links 0 "Aus" 1 "Ein" ;
VAL_ 1696 NV_Markierungslicht_rechts 0 "Aus" 1 "Ein" ;
VAL_ 1696 NV_Symbol_Tierwarnung 0 "Aus" 1 "Ein" ;
VAL_ 1696 NV_Anf_Prefill 0 "nicht_angefordert" 1 "angefordert" ;
VAL_ 1696 NV_HBA_Parameter 0 "Defaultparametersatz" 1 "Parametersatz_mit_leicht_erhoehter_Empfindlichkeit" 2 "Parametersatz_mit_erhoehter_Empfindlichkeit" 3 "Parametersatz_mit_hoechster_Empfindlichkeit" ;
VAL_ 1696 NV_KD_Fehler 0 "kein_KD_Fehler" 1 "KD_Fehler" ;
VAL_ 1742 NMH_BMS_Start_1 1 "Zustand Start (<--Sleep)" ;
VAL_ 1742 NMH_BMS_Start_2 1 "Zustand Start (<--Prepare to Sleep)" ;
VAL_ 1742 NMH_BMS_Normal_Mode_1 1 "Zustand Normal Mode (<-- Start)" ;
VAL_ 1742 NMH_BMS_Normal_Mode_2 1 "Zustand Normal Mode (<-- Ready to Sleep)" ;
VAL_ 1742 NMH_BMS_Car_WakeUp 1 "Car Wake Up" ;
VAL_ 1742 NMH_BMS_Per_WakeUp 0 "Funktions-WakeUp" 1 "CAN" 2 "P_WakeUp_Ursache_unbekannt" 3 "KL_15_Hardware_falls_vorhanden" ;
VAL_ 1742 NMH_BMS_Fkt_WakeUp 0 "Peripheriewakeup" 1 "Uebertemp_HV_Zellen" ;
VAL_ 1742 NMH_BMS_Klemme_15 1 "Klemme 15 ein" ;
VAL_ 1742 NMH_BMS_Diagnose 1 "Diagnose bei Kl 15 aus" ;
VAL_ 1742 NMH_BMS_MindestAktivZeit 1 "aktiv" ;
VAL_ 1742 NMH_BMS_NL_Daten_EEPROM 0 "kein_Nachlauf" 1 "EEPROM_schreibzugriff" ;
VAL_ 1742 NMH_BMS_NL_Luefter 0 "kein_Nachlauf" 1 "Luefter_aktiv" ;
VAL_ 1742 NMH_BMS_Signalfehler 1 "Aktiver_Signalfehler_eingetragen" ;
VAL_ 1742 NMH_BMS_TimeOut_Fehler 1 "Aktiver Timeout Fehlerspeichereintrag" ;
VAL_ 1742 NMH_BMS_CAN_Diag_deaktiv 1 "CAN Bus bezogene Eigendiagnose deaktiviert" ;
VAL_ 1742 NMH_BMS_KompSchutz 0 "inaktiv" 1 "aktiv" ;
VAL_ 1742 NMH_BMS_Mute_Mode 1 "Mute Mode aktiv" ;
VAL_ 1742 NMH_BMS_Transport_Mode 1 "Transportmodus aktiv" ;
VAL_ 1742 NMH_BMS_Abschaltstufe_aktiv 1 "Funktionsabschaltung wegen Abschaltschaltstufe" ;
VAL_ 1742 NMH_BMS_Busfehler 1 "Busfehler" ;
VAL_ 1742 NMH_BMS_Lokalaktiv 0 "war_nicht_lokal_aktiv" 1 "war_lokal_aktiv" ;
VAL_ 1742 NMH_BMS_Subsystemaktiv 0 "Subsystem_war_nicht_lokalaktiv" 1 "war_lokalaktiv" ;
VAL_ 1743 NMH_EM_Start_1 1 "Zustand Start (<--Sleep)" ;
VAL_ 1743 NMH_EM_Start_2 1 "Zustand Start (<--Prepare to Sleep)" ;
VAL_ 1743 NMH_EM_Normal_Mode_1 1 "Zustand Normal Mode (<-- Start)" ;
VAL_ 1743 NMH_EM_Normal_Mode_2 1 "Zustand Normal Mode (<-- Ready to Sleep)" ;
VAL_ 1743 NMH_EM_Car_WakeUp 1 "Car Wake Up" ;
VAL_ 1743 NMH_EM_Per_WakeUp 0 "Funktions-WakeUp" 1 "CAN" 2 "P_WakeUp_Ursache_unbekannt" 3 "KL_15_Hardware_falls_vorhanden" ;
VAL_ 1743 NMH_EM_Fkt_WakeUp 0 "Peripheriewakeup" ;
VAL_ 1743 NMH_EM_Klemme_15 1 "Klemme 15 ein" ;
VAL_ 1743 NMH_EM_Diagnose 1 "Diagnose bei Kl 15 aus" ;
VAL_ 1743 NMH_EM_MindestAktivZeit 1 "aktiv" ;
VAL_ 1743 NMH_EM_keine_HV_Entl 0 "kein_Nachlauf" 1 "HV_Entladung_nicht_moeglich" ;
VAL_ 1743 NMH_EM_NL_Datem_EEPROM 0 "kein_Nachlauf" 1 "EEPROM_schreibzugriff" ;
VAL_ 1743 NMH_EM_Signalfehler 1 "Aktiver_Signalfehler_eingetragen" ;
VAL_ 1743 NMH_EM_TimeOut_Fehler 1 "Aktiver Timeout Fehlerspeichereintrag" ;
VAL_ 1743 NMH_EM_CAN_Diag_deaktiv 1 "CAN Bus bezogene Eigendiagnose deaktiviert" ;
VAL_ 1743 NMH_EM_KompSchutz 0 "inaktiv" 1 "aktiv" ;
VAL_ 1743 NMH_EM_Mute_Mode 1 "Mute Mode aktiv" ;
VAL_ 1743 NMH_EM_Transport_Mode 1 "Transportmodus aktiv" ;
VAL_ 1743 NMH_EM_Abschaltstufe_aktiv 1 "Funktionsabschaltung wegen Abschaltschaltstufe" ;
VAL_ 1743 NMH_EM_Busfehler 1 "Busfehler" ;
VAL_ 1743 NMH_EM_Lokalaktiv 0 "war_nicht_lokal_aktiv" 1 "war_lokal_aktiv" ;
VAL_ 1743 NMH_EM_Subsystemaktiv 0 "Subsystem_war_nicht_lokalaktiv" 1 "war_lokalaktiv" ;
VAL_ 1753 NMH_EPB_Start_1 1 "Zustand Start (<--Sleep)" ;
VAL_ 1753 NMH_EPB_Start_2 1 "Zustand Start (<--Prepare to Sleep)" ;
VAL_ 1753 NMH_EPB_Normal_Mode_1 1 "Zustand Normal Mode (<-- Start)" ;
VAL_ 1753 NMH_EPB_Normal_Mode_2 1 "Zustand Normal Mode (<-- Ready to Sleep)" ;
VAL_ 1753 NMH_EPB_Per_WakeUp 0 "Wenn Funktions-Wakeup" 1 "CAN-Wakeup" 2 "Periphrie-Wakeup Ursache nicht bekannt" 3 "Klemme 15 HW (falls vorhanden)" 5 "Schalter_EPB" ;
VAL_ 1753 NMH_EPB_Fkt_WakeUp 0 "Wenn Peripherie-Wakeup" ;
VAL_ 1753 NMH_EPB_NM_aktiv_Klemme_15 1 "Klemme 15 EIN" ;
VAL_ 1753 NMH_EPB_NM_aktiv_Diagnose 1 "Diagnose bei Kl 15 aus" ;
VAL_ 1753 NMH_EPB_NM_aktiv_Start 1 "Zustand 'START' (NM-high)" ;
VAL_ 1753 NMH_EPB_NM_aktiv_Schalter 1 "Schalter aktiv" ;
VAL_ 1753 NMH_EPB_NM_aktiv_Bedarf_Anzeige 1 "Kombi-Anzeige EPB" ;
VAL_ 1753 NMH_EPB_NM_aktiv_v_groesser_Null 1 "v > 0" ;
VAL_ 1753 NMH_EPB_AutoAdjust 0 "AutoAdjust_nicht_aktiv" 1 "AutoAdjust_aktiv" ;
VAL_ 1753 NMH_EPB_kein_NL 1 "kein lokaler Nachlauf" ;
VAL_ 1753 NMH_EPB_NL_Temp_Modell 1 "Temperaturmodell aktiv" ;
VAL_ 1753 NM_EPB_Signalfehler 1 "Aktiver_Signalfehler_eingetragen" ;
VAL_ 1753 NMH_EPB_TimeOut_Fehler 1 "Aktiver Timeout Fehlerspeichereintrag  " ;
VAL_ 1753 NMH_EPB_CAN_Diag_deaktiv 1 "CAN-Diagnose deaktiv" ;
VAL_ 1753 NMH_EPB_KompSchutz 0 "inaktiv" 1 "aktiv" ;
VAL_ 1753 NMH_EPB_Mute_Mode 1 "MuteMode aktiv" ;
VAL_ 1753 NMH_EPB_Transport_Mode 1 "Transportmodus aktiv" ;
VAL_ 1753 NMH_EPB_Abschaltstufe_aktiv 1 "Abschaltstufe aktiv" ;
VAL_ 1753 NMH_EPB_Eindraht_Fehler 1 "Eindrahtbetrieb erkannt" ;
VAL_ 1753 NMH_EPB_Lokalaktiv 0 "war_nicht_lokal_aktiv" 1 "war_lokal_aktiv" ;
VAL_ 1753 NMH_EPB_Subsystemaktiv 0 "Subsystem_war_nicht_lokalaktiv" 1 "war_lokalaktiv" ;
VAL_ 1728 NMH_GW_Start_1 1 "Zustand Start (<--Sleep)" ;
VAL_ 1728 NMH_GW_Start_2 1 "Zustand Start (<--Prepare to Sleep)" ;
VAL_ 1728 NMH_GW_Normal_Mode_1 1 "Zustand Normal Mode (<-- Start)" ;
VAL_ 1728 NMH_GW_Normal_Mode_2 1 "Zustand Normal Mode (<-- Ready to Sleep)" ;
VAL_ 1728 NMH_GW_Per_WakeUp 0 "Wenn_FunktionsWakeup" 1 "CAN_Wakeup__Weckendes_CAN_Segment_siehe_NMH_GW_WakeUp_CAN_Bus" 2 "P_WakeUp_Ursache_unbekannt" 3 "Klemme_15HW__falls_vorhanden" 4 "MOST_Wakeup" 5 "LIN_Wakeup" 6 "KL30_Reset" ;
VAL_ 1728 NMH_GW_Fkt_WakeUp 0 "Wenn_Peripherie_Wakeup" 1 "Funktionswakeup_EM" 2 "Car_Wakeup_empfangen" 3 "VNSM_VehicleNetworkStateManager" 4 "Alarm_RTC__Wecken_weil_Weckzeit_abgelaufen" 5 "Wecken_durch_Diagnose" ;
VAL_ 1728 NMH_GW_NM_aktiv_Klemme_15 1 "Klemme 15 EIN" ;
VAL_ 1728 NMH_GW_NM_aktiv_Diagnose 1 "Diagnose bei Kl 15 aus" ;
VAL_ 1728 NMH_GW_NM_aktiv_Start 1 "Zustand 'START' (NM-high)" ;
VAL_ 1728 NMH_GW_NM_aktiv_BDM 1 "BDM-Kommunikation" ;
VAL_ 1728 NMH_GW_NM_aktiv_Warnblinken 1 "Warnblinken aktiv" ;
VAL_ 1728 NMH_GW_NM_aktiv_ESP 1 "ESP aktiv (Wakeup/Sleep-Konzept)" ;
VAL_ 1728 NMH_GW_NM_aktiv_EMP 1 "EMP_aktiv" ;
VAL_ 1728 NMH_GW_Abschaltstufe_3 1 "BEM aufgrund Abschaltstufe 3 aktiv" ;
VAL_ 1728 NMH_GW_SG_Fehlerdauer 1 "BEM aufgrund Steuergeraetefehlerdauer aktiv" ;
VAL_ 1728 NMH_GW_STH_Wakeup 1 "BEM aktiv aufgrund Standheizungswakeup" ;
VAL_ 1728 NMH_GW_NL_Diagnose 0 "keine_Diagnose_aktiv" 1 "Diagnose_war_lokal_aktiv" ;
VAL_ 1728 NM_GW_Signalfehler 1 "Aktiver_Signalfehler_eingetragen" ;
VAL_ 1728 NMH_GW_TimeOut_Fehler 1 "Aktiver Timeout Fehlerspeichereintrag  " ;
VAL_ 1728 NMH_GW_CAN_Diag_deaktiv 1 "CAN Bus bezogene Eigendiagnose deaktiv" ;
VAL_ 1728 NMH_GW_KompSchutz 0 "inaktiv" 1 "aktiv" ;
VAL_ 1728 NMH_GW_Mute_Mode 1 "MuteMode aktiv" ;
VAL_ 1728 NMH_GW_Transport_Mode 1 "Transportmodus aktiv" ;
VAL_ 1728 NMH_GW_Abschaltstufe_aktiv 1 "Abschaltstufe aktiv" ;
VAL_ 1728 NMH_GW_Eindraht_Fehler 1 "Eindrahtbetrieb erkannt" ;
VAL_ 1728 NMH_GW_ACAN 1 "ACAN aktiv (Wakeup/Sleep-Konzept)" ;
VAL_ 1728 NMH_GW_KombiCAN 1 "KombiCAN aktiv (Wakeup/Sleep-Konzept)" ;
VAL_ 1728 NMH_GW_KomfortCAN 1 "KomfortCAN aktiv (Wakeup/Sleep-Konzept)" ;
VAL_ 1728 NMH_GW_Infotainment 1 "Infotainment aktiv (CAN oder MOST), Wakeup/Sleep-Konzept" ;
VAL_ 1728 NMH_GW_Fahrwerk 1 "BUS_Fahrwerk_aktiv (Wakeup/Sleep-Konzept)" ;
VAL_ 1728 NMH_GW_WakeUp_CAN_Bus 0 "Nicht zutreffend (kein CAN-Wakeup bzw. CarWakeup)" 1 "Antriebs-CAN" 2 "Kombi-CAN" 3 "Komfort-CAN" 4 "Infotainment-CAN (wenn verfuegbar)" 5 "Fahrwerks-CAN" 6 "Diagnose-CAN" ;
VAL_ 1730 NMH_GE_Start_1 1 "Zustand Start (<--Sleep)" ;
VAL_ 1730 NMH_GE_Start_2 1 "Zustand Start (<--Prepare to Sleep)" ;
VAL_ 1730 NMH_GE_Normal_Mode_1 1 "Zustand Normal Mode (<-- Start)" ;
VAL_ 1730 NMH_GE_Normal_Mode_2 1 "Zustand Normal Mode (<-- Ready to Sleep)" ;
VAL_ 1730 NMH_GE_Per_WakeUp 0 "wenn Funktionswakeup" 1 "CAN" 2 "P-Wakeup, Ursache nicht bekannt" 3 "KL 15 HW (falls vorhanden)" ;
VAL_ 1730 NMH_GE_Fkt_WakeUp 0 "wenn Peripheriewakeup" 1 "Ende_N_Haltephase" ;
VAL_ 1730 NMH_GE_NM_aktiv_Klemme_15 1 "Klemme 15 ein" ;
VAL_ 1730 NMH_GE_NM_aktiv_Diagnose 1 "Diagnose bei Kl 15 aus" ;
VAL_ 1730 NMH_GE_NM_aktiv_Start 1 "Zustand 'START' (NM-high)" ;
VAL_ 1730 NMH_GE_N_Haltephase 0 "keine_N_Haltephase" 1 "N_Haltephase_aktiv" ;
VAL_ 1730 NMH_GE_Positionsanzeige 0 "GE_Postitionsanzeige_Inaktiv" 1 "GE_Postitionsanzeige_Aktiv" ;
VAL_ 1730 NMH_GE_kein_NL 1 "kein lokaler Nachlauf" ;
VAL_ 1730 NMH_GE_NL_Daten_EEPROM 1 "EEPROM Datenspeicherung" ;
VAL_ 1730 NM_GE_Signalfehler 1 "Aktiver_Signalfehler_eingetragen" ;
VAL_ 1730 NMH_GE_TimeOut_Fehler 1 "Aktiver Timeout Fehlerspeichereintrag  " ;
VAL_ 1730 NMH_GE_CAN_Diag_deaktiv 1 "CAN-Diagnose deaktiv" ;
VAL_ 1730 NMH_GE_KompSchutz 0 "inaktiv" 1 "aktiv" ;
VAL_ 1730 NMH_GE_Mute_Mode 1 "MuteMode aktiv" ;
VAL_ 1730 NMH_GE_Transport_Mode 1 "Transportmodus aktiv" ;
VAL_ 1730 NMH_GE_Abschaltstufe_aktiv 1 "Abschaltstufe aktiv" ;
VAL_ 1730 NMH_GE_Eindraht_Fehler 1 "Eindrahtbetrieb erkannt" ;
VAL_ 1730 NMH_GE_Lokalaktiv 0 "war_nicht_lokal_aktiv" 1 "war_lokal_aktiv" ;
VAL_ 1730 NMH_GE_Subsystemaktiv 0 "Subsystem_war_nicht_lokalaktiv" 1 "war_lokalaktiv" ;
VAL_ 1730 NMH_GSG_Subbusaktiv 0 "Subbus inaktiv" 1 "Subbus aktiv" ;
VAL_ 1729 NMH_MO_Start_1 1 "Zustand Start (<--Sleep)" ;
VAL_ 1729 NMH_MO_Start_2 1 "Zustand Start (<--Prepare to Sleep)" ;
VAL_ 1729 NMH_MO_Normal_Mode_1 1 "Zustand Normal Mode (<-- Start)" ;
VAL_ 1729 NMH_MO_Normal_Mode_2 1 "Zustand Normal Mode (<-- Ready to Sleep)" ;
VAL_ 1729 NMH_MO_Per_WakeUp 0 "Wenn Funktions-Wakeup" 1 "CAN-Wakeup" 2 "Peripherie-Wakeup Ursache nicht bekannt" 3 "Klemme 15 HW (falls vorhanden)" 4 "analog (Standheizung/Tuerkontakt)(nur MED9)" ;
VAL_ 1729 NMH_MO_Fkt_WakeUp 0 "Wenn_Peripherie_Wakeup" ;
VAL_ 1729 NMH_MO_NM_aktiv_Klemme_15 1 "Klemme 15 EIN" ;
VAL_ 1729 NMH_MO_NM_aktiv_Diagnose 1 "Diagnose bei Kl 15 aus " ;
VAL_ 1729 NMH_MO_NM_aktiv_Start 1 "Zustand 'START' (NM-high)" ;
VAL_ 1729 NMH_MO_NM_aktiv_EKP_Vorlauf 1 "EKP-Vorlauf" ;
VAL_ 1729 NMH_MO_NM_aktiv_STH_Betrieb 1 "STH-Betrieb" ;
VAL_ 1729 NMH_MO_NM_aktiv_HV 0 "keine_HV_Abschaltung__Laden__Konditionieren" 1 "HV_Abschaltung__Laden__Konditionieren_aktiv" ;
VAL_ 1729 NMH_MO_kein_NL 1 "kein lokaler Nachlauf" ;
VAL_ 1729 NMH_MO_NL_Kuehlerluefter 1 "Kühlerlüfter Steuerung / Zusatzwasserpumpe aktiv" ;
VAL_ 1729 NMH_MO_NL_Diagnose 1 "Diagnosefunktionen aktiv" ;
VAL_ 1729 NMH_MO_NL_WFS 1 "WFS aktiv" ;
VAL_ 1729 NMH_MO_NL_EEPROM 1 "EEPROM Zugriffe RAM/ROM Tests" ;
VAL_ 1729 NMH_MO_NL_Sonstige 1 "Sonstige Nachläufe aktiv" ;
VAL_ 1729 NM_MO_01_NM_aktiv_Betankung 0 "kein_Nachlauf" 1 "Betankung_Drucktank" ;
VAL_ 1729 NM_MO_Signalfehler 1 "Aktiver_Signalfehler_eingetragen" ;
VAL_ 1729 NMH_MO_TimeOut_Fehler 1 "Aktiver Timeout Fehlerspeichereintrag  " ;
VAL_ 1729 NMH_MO_CAN_Diag_deaktiv 1 "CAN-Diagnose deaktiv" ;
VAL_ 1729 NMH_MO_KompSchutz 0 "inaktiv" 1 "aktiv" ;
VAL_ 1729 NMH_MO_Mute_Mode 1 "MuteMode aktiv" ;
VAL_ 1729 NMH_MO_Transport_Mode 1 "Transportmodus aktiv" ;
VAL_ 1729 NMH_MO_Abschaltstufe_aktiv 1 "Abschaltstufe aktiv" ;
VAL_ 1729 NMH_MO_Eindraht_Fehler 1 "Eindrahtbetrieb erkannt" ;
VAL_ 1729 NMH_MO_Lokalaktiv 0 "war_nicht_lokal_aktiv" 1 "war_lokal_aktiv" ;
VAL_ 1729 NMH_MO_Subsystemaktiv 0 "Subsystem_war_nicht_lokalaktiv" 1 "war_lokalaktiv" ;
VAL_ 1736 NMH_MO_SL_Start_1 1 "Zustand Start (<--Sleep)" ;
VAL_ 1736 NMH_MO_SL_Start_2 1 "Zustand Start (<--Prepare to Sleep)" ;
VAL_ 1736 NMH_MO_SL_Normal_Mode_1 1 "Zustand Normal Mode (<-- Start)" ;
VAL_ 1736 NMH_MO_SL_Normal_Mode_2 1 "Zustand Normal Mode (<-- Ready to Sleep)" ;
VAL_ 1736 NMH_MO_SL_Per_WakeUp 0 "Wenn Funktions-Wakeup" 1 "CAN-Wakeup" 2 "Peripherie-Wakeup Ursache nicht bekannt" 3 "Klemme 15 HW (falls vorhanden)" 4 "analog (Standheizung/Tuerkontakt)(nur MED9)" ;
VAL_ 1736 NMH_MO_SL_Fkt_WakeUp 0 "Wenn Peripherie-Wakeup" ;
VAL_ 1736 NMH_MO_SL_NM_aktiv_Klemme_15 1 "Klemme 15 EIN" ;
VAL_ 1736 NMH_MO_SL_NM_aktiv_Diagnose 1 "Diagnose bei Kl 15 aus " ;
VAL_ 1736 NMH_MO_SL_NM_aktiv_Start 1 "Zustand 'START' (NM-high)" ;
VAL_ 1736 NMH_MO_SL_NM_aktiv_EKP_Vorlauf 1 "EKP-Vorlauf" ;
VAL_ 1736 NMH_MO_SL_NM_aktiv_STH_Betrieb 1 "STH-Betrieb" ;
VAL_ 1736 NMH_MO_SL_NM_aktiv_HV 0 "keine_HV_Abschaltung__Laden__Konditionieren" 1 "HV_Abschaltung__Laden__Konditionieren_aktiv" ;
VAL_ 1736 NMH_MO_kein_NL 1 "kein lokaler Nachlauf" ;
VAL_ 1736 NMH_MO_NL_Kuehlerluefter 1 "Kühlerlüfter Steuerung / Zusatzwasserpumpe aktiv" ;
VAL_ 1736 NMH_MO_NL_Diagnose 1 "Diagnosefunktionen aktiv" ;
VAL_ 1736 NMH_MO_NL_WFS 1 "WFS aktiv" ;
VAL_ 1736 NMH_MO_NL_EEPROM 1 "EEPROM Zugriffe RAM/ROM Tests" ;
VAL_ 1736 NMH_MO_NL_Sonstige 1 "Sonstige Nachläufe aktiv" ;
VAL_ 1736 NM_MO_SL_Signalfehler 1 "Aktiver_Signalfehler_eingetragen" ;
VAL_ 1736 NMH_MO_SL_TimeOut_Fehler 1 "Aktiver Timeout Fehlerspeichereintrag  " ;
VAL_ 1736 NMH_MO_SL_CAN_Diag_deaktiv 1 "CAN-Diagnose deaktiv" ;
VAL_ 1736 NMH_MO_SL_KompSchutz 0 "inaktiv" 1 "aktiv" ;
VAL_ 1736 NMH_MO_SL_Mute_Mode 1 "MuteMode aktiv" ;
VAL_ 1736 NMH_MO_SL_Transport_Mode 1 "Transportmodus aktiv" ;
VAL_ 1736 NMH_MO_SL_Abschaltstufe_aktiv 1 "Abschaltstufe aktiv" ;
VAL_ 1736 NMH_MO_SL_Busfehler 1 "Busfehler" ;
VAL_ 1736 NMH_MO_Sl_Lokalaktiv 0 "war_nicht_lokal_aktiv" 1 "war_lokal_aktiv" ;
VAL_ 1736 NMH_MO_SL_Subsystemaktiv 0 "Subsystem_war_nicht_lokalaktiv" 1 "war_lokalaktiv" ;
VAL_ 1782 NMH_SCR_Start_1 1 "Zustand Start (<--Sleep)" ;
VAL_ 1782 NMH_SCR_Start_2 1 "Zustand Start (<--Prepare to Sleep)" ;
VAL_ 1782 NMH_SCR_Normal_Mode_1 1 "Zustand Normal Mode (<-- Start)" ;
VAL_ 1782 NMH_SCR_Normal_Mode_2 1 "Zustand Normal Mode (<-- Ready to Sleep)" ;
VAL_ 1782 NMH_SCR_Car_WakeUp 1 "Car Wake Up" ;
VAL_ 1782 NMH_SCR_Per_WakeUp 0 "Funktions-WakeUp" 1 "CAN" 2 "P_WakeUp_Ursache_unbekannt" 3 "KL_15_Hardware_falls_vorhanden" 4 "KL_87_Hardware" ;
VAL_ 1782 NMH_SCR_Fkt_WakeUp 0 "Peripheriewakeup" 1 "OBD_Diagnoseinformationen" ;
VAL_ 1782 NMH_SCR_Klemme_15 1 "Klemme 15 ein" ;
VAL_ 1782 NMH_SCR_Diagnose 1 "Diagnose bei Kl 15 aus" ;
VAL_ 1782 NMH_SCR_MindestAktivZeit 1 "aktiv" ;
VAL_ 1782 NMH_SCR_NL_Datem_EEPROM 0 "kein_Nachlauf" 1 "EEPROM_schreibzugriff" ;
VAL_ 1782 NMH_SCR_NL_OBD_Diagnose 1 "OBD_Diagnose_aktiv" ;
VAL_ 1782 NMH_SCR_Signalfehler 1 "Aktiver_Signalfehler_eingetragen" ;
VAL_ 1782 NMH_SCR_TimeOut_Fehler 1 "Aktiver Timeout Fehlerspeichereintrag" ;
VAL_ 1782 NMH_SCR_CAN_Diag_deaktiv 1 "CAN Bus bezogene Eigendiagnose deaktiviert" ;
VAL_ 1782 NMH_SCR_KompSchutz 0 "inaktiv" 1 "aktiv" ;
VAL_ 1782 NMH_SCR_Mute_Mode 1 "Mute Mode aktiv" ;
VAL_ 1782 NMH_SCR_Transport_Mode 1 "Transportmodus aktiv" ;
VAL_ 1782 NMH_SCR_Abschaltstufe_aktiv 1 "Funktionsabschaltung wegen Abschaltschaltstufe" ;
VAL_ 1782 NMH_SCR_Busfehler 1 "Busfehler" ;
VAL_ 1782 NMH_SCR_Lokalaktiv 0 "war_nicht_lokal_aktiv" 1 "war_lokal_aktiv" ;
VAL_ 1782 NMH_SCR_Subsystemaktiv 0 "Subsystem_war_nicht_lokalaktiv" 1 "war_lokalaktiv" ;
